VERSION ""

NS_ :

BS_:

BU_: ESP_ABR Vector__XXX

BA_DEF_ BO_ "GenMsgCycleTime" INT 0 65535;
BA_DEF_DEF_ "GenMsgCycleTime" 0;

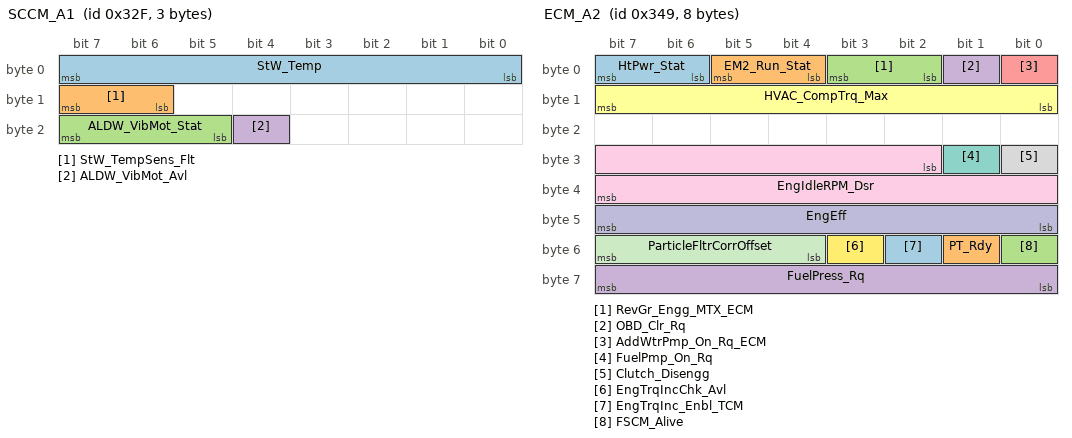
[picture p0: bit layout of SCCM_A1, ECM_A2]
BO_ 815 SCCM_A1: 3 ESP_ABR
 SG_ StW_Temp : 0|8@1+ (0.5,-40) [-40|87.5] "degC" Vector__XXX

CM_ SG_ 815 StW_Temp "StW_Temp";
 SG_ StW_TempSens_Flt : 14|2@1+ (1,0) [0|3] "" Vector__XXX

CM_ SG_ 815 StW_TempSens_Flt "StW_TempSens_Flt [source enum/value-table reference]";
 SG_ ALDW_VibMot_Stat : 21|3@1+ (1,0) [0|7] "" Vector__XXX

CM_ SG_ 815 ALDW_VibMot_Stat "ALDW_VibMot_Stat [source enum/value-table reference]";
 SG_ ALDW_VibMot_Avl : 20|1@1+ (1,0) [0|1] "" Vector__XXX

CM_ SG_ 815 ALDW_VibMot_Avl "ALDW_VibMot_Avl [source boolean]";

BA_ "GenMsgCycleTime" BO_ 815 4;

BO_ 822 TANK_OBD: 3 ESP_ABR
 SG_ TankLvl_OBD : 0|8@1+ (0.392156869173,0) [0|100.000001639] "%" Vector__XXX

CM_ SG_ 822 TankLvl_OBD "TankLvl_OBD";
 SG_ TankLvl_Max_OBD : 8|8@1+ (1,0) [0|255] "l" Vector__XXX

CM_ SG_ 822 TankLvl_Max_OBD "TankLvl_Max_OBD";
 SG_ TankSens_Rt_Stat_IC : 20|4@1+ (1,0) [0|15] "" Vector__XXX

CM_ SG_ 822 TankSens_Rt_Stat_IC "TankSens_Rt_Stat_IC [source enum/value-table reference]";
 SG_ TankSens_Lt_Stat_IC : 16|4@1+ (1,0) [0|15] "" Vector__XXX

CM_ SG_ 822 TankSens_Lt_Stat_IC "TankSens_Lt_Stat_IC [source enum/value-table reference]";

BA_ "GenMsgCycleTime" BO_ 822 4;

BO_ 828 ECM_DISP_RQ2: 8 ESP_ABR
 SG_ EngIconDisp_Rq : 6|2@1+ (1,0) [0|3] "" Vector__XXX

CM_ SG_ 828 EngIconDisp_Rq "EngIconDisp_Rq [source enum/value-table reference]";
 SG_ EM1_IconDisp_Rq : 4|2@1+ (1,0) [0|3] "" Vector__XXX

CM_ SG_ 828 EM1_IconDisp_Rq "EM1_IconDisp_Rq [source enum/value-table reference]";
 SG_ ArrEM1_EngDisp_Rq : 2|2@1+ (1,0) [0|3] "" Vector__XXX

CM_ SG_ 828 ArrEM1_EngDisp_Rq "ArrEM1_EngDisp_Rq [source enum/value-table reference]";
 SG_ ArrEM1_BatDisp_Rq : 0|2@1+ (1,0) [0|3] "" Vector__XXX

CM_ SG_ 828 ArrEM1_BatDisp_Rq "ArrEM1_BatDisp_Rq [source enum/value-table reference]";
 SG_ ArrEM1_WhlDisp_Rq : 14|2@1+ (1,0) [0|3] "" Vector__XXX

CM_ SG_ 828 ArrEM1_WhlDisp_Rq "ArrEM1_WhlDisp_Rq [source enum/value-table reference]";
 SG_ ArrBatDisp_Rq : 12|2@1+ (1,0) [0|3] "" Vector__XXX

CM_ SG_ 828 ArrBatDisp_Rq "ArrBatDisp_Rq [source enum/value-table reference]";
 SG_ PT_Rdy_IndLmp_Rq : 10|2@1+ (1,0) [0|3] "" Vector__XXX

CM_ SG_ 828 PT_Rdy_IndLmp_Rq "PT_Rdy_IndLmp_Rq [source enum/value-table reference]";
 SG_ PNHV_SupBat_SOC_Disp_Rq : 16|8@1+ (0.5,0) [0|127.5] "%" Vector__XXX

CM_ SG_ 828 PNHV_SupBat_SOC_Disp_Rq "PNHV_SupBat_SOC_Disp_Rq";
 SG_ Hyb_Msg_Disp_Rq : 28|4@1+ (1,0) [0|15] "" Vector__XXX

CM_ SG_ 828 Hyb_Msg_Disp_Rq "Hyb_Msg_Disp_Rq [source enum/value-table reference]";
 SG_ Hyb_WarnDisp_Rq : 24|4@1+ (1,0) [0|15] "" Vector__XXX

CM_ SG_ 828 Hyb_WarnDisp_Rq "Hyb_WarnDisp_Rq [source enum/value-table reference]";
 SG_ MC_ECM_DISP_RQ2 : 36|4@1+ (1,0) [0|15] "" Vector__XXX

CM_ SG_ 828 MC_ECM_DISP_RQ2 "MC_ECM_DISP_RQ2";
 SG_ Prty_PNHV_SupBat_VoltMax_Disp_Rq : 35|1@1+ (1,0) [0|1] "" Vector__XXX

CM_ SG_ 828 Prty_PNHV_SupBat_VoltMax_Disp_Rq "Prty_PNHV_SupBat_VoltMax_Disp_Rq [source boolean]";
 SG_ Prty_PNHV_VoltDn_Disp_Rq : 34|1@1+ (1,0) [0|1] "" Vector__XXX

CM_ SG_ 828 Prty_PNHV_VoltDn_Disp_Rq "Prty_PNHV_VoltDn_Disp_Rq [source boolean]";
 SG_ PNHV_VoltDn_Disp_Rq : 33|1@1+ (1,0) [0|1] "" Vector__XXX

CM_ SG_ 828 PNHV_VoltDn_Disp_Rq "PNHV_VoltDn_Disp_Rq [source boolean]";
 SG_ PT_Rdy_IndLmp_On_Rq : 32|1@1+ (1,0) [0|1] "" Vector__XXX

CM_ SG_ 828 PT_Rdy_IndLmp_On_Rq "PT_Rdy_IndLmp_On_Rq [source boolean]";
 SG_ PNHV_SupBat_VoltMax_Disp_Rq : 40|8@1+ (2,0) [0|510] "V" Vector__XXX

CM_ SG_ 828 PNHV_SupBat_VoltMax_Disp_Rq "PNHV_SupBat_VoltMax_Disp_Rq";
 SG_ PNHV_SupBat_Curr_Disp_Rq : 48|8@1+ (5,-640) [-640|635] "A" Vector__XXX

CM_ SG_ 828 PNHV_SupBat_Curr_Disp_Rq "PNHV_SupBat_Curr_Disp_Rq";
 SG_ EngOilPress_Disp_Rq : 56|8@1+ (0.10000000149,0) [0|25.50000038] "bar" Vector__XXX

CM_ SG_ 828 EngOilPress_Disp_Rq "EngOilPress_Disp_Rq";

BA_ "GenMsgCycleTime" BO_ 828 18;

BO_ 829 ECM_DISP_RQ: 4 ESP_ABR
 SG_ WtrFuelIndLmp_On_Rq : 7|1@1+ (1,0) [0|1] "" Vector__XXX

CM_ SG_ 829 WtrFuelIndLmp_On_Rq "WtrFuelIndLmp_On_Rq [source boolean]";
 SG_ FuelFltrIndLmp_On_Rq : 6|1@1+ (1,0) [0|1] "" Vector__XXX

CM_ SG_ 829 FuelFltrIndLmp_On_Rq "FuelFltrIndLmp_On_Rq [source boolean]";
 SG_ TankCapIndLmp_On_Rq : 5|1@1+ (1,0) [0|1] "" Vector__XXX

CM_ SG_ 829 TankCapIndLmp_On_Rq "TankCapIndLmp_On_Rq [source boolean]";
 SG_ MIL_On_Rq : 4|1@1+ (1,0) [0|1] "" Vector__XXX

CM_ SG_ 829 MIL_On_Rq "MIL_On_Rq [source boolean]";
 SG_ EngOilIndLmp_On_Rq : 3|1@1+ (1,0) [0|1] "" Vector__XXX

CM_ SG_ 829 EngOilIndLmp_On_Rq "EngOilIndLmp_On_Rq [source boolean]";
 SG_ PreHtIndLmp_On_Rq : 2|1@1+ (1,0) [0|1] "" Vector__XXX

CM_ SG_ 829 PreHtIndLmp_On_Rq "PreHtIndLmp_On_Rq [source boolean]";
 SG_ AirStrIndLmp_On_Rq : 1|1@1+ (1,0) [0|1] "" Vector__XXX

CM_ SG_ 829 AirStrIndLmp_On_Rq "AirStrIndLmp_On_Rq [source boolean]";
 SG_ FanMtrIndLmp_On_Rq : 0|1@1+ (1,0) [0|1] "" Vector__XXX

CM_ SG_ 829 FanMtrIndLmp_On_Rq "FanMtrIndLmp_On_Rq [source boolean]";
 SG_ EngOilTemp_Above_Max : 15|1@1+ (1,0) [0|1] "" Vector__XXX

CM_ SG_ 829 EngOilTemp_Above_Max "EngOilTemp_Above_Max [source boolean]";
 SG_ SSA_ECO_Sw_LED_On_Rq : 13|2@1+ (1,0) [0|3] "" Vector__XXX

CM_ SG_ 829 SSA_ECO_Sw_LED_On_Rq "SSA_ECO_Sw_LED_On_Rq [source enum/value-table reference]";
 SG_ SSA_ECO_Md_DispCol_Rq : 12|1@1+ (1,0) [0|1] "" Vector__XXX

CM_ SG_ 829 SSA_ECO_Md_DispCol_Rq "SSA_ECO_Md_DispCol_Rq [source boolean]";
 SG_ ParticleFltrWarn : 10|2@1+ (1,0) [0|3] "" Vector__XXX

CM_ SG_ 829 ParticleFltrWarn "ParticleFltrWarn [source enum/value-table reference]";
 SG_ OvrRPM_Actv : 9|1@1+ (1,0) [0|1] "" Vector__XXX

CM_ SG_ 829 OvrRPM_Actv "OvrRPM_Actv [source boolean]";
 SG_ DAC_StErr : 8|1@1+ (1,0) [0|1] "" Vector__XXX

CM_ SG_ 829 DAC_StErr "DAC_StErr [source boolean]";
 SG_ SSA_Msg_Disp_Rq : 20|4@1+ (1,0) [0|15] "" Vector__XXX

CM_ SG_ 829 SSA_Msg_Disp_Rq "SSA_Msg_Disp_Rq [source enum/value-table reference]";
 SG_ SSA_WarnDisp_Rq : 16|4@1+ (1,0) [0|15] "" Vector__XXX

CM_ SG_ 829 SSA_WarnDisp_Rq "SSA_WarnDisp_Rq [source enum/value-table reference]";
 SG_ Gr_Target_Disp_Rq_ECM : 28|4@1+ (1,0) [0|15] "" Vector__XXX

CM_ SG_ 829 Gr_Target_Disp_Rq_ECM "Gr_Target_Disp_Rq_ECM [source enum/value-table reference]";
 SG_ TxShiftRcmmnd_Disp_Rq_ECM : 26|2@1+ (1,0) [0|3] "" Vector__XXX

CM_ SG_ 829 TxShiftRcmmnd_Disp_Rq_ECM "TxShiftRcmmnd_Disp_Rq_ECM [source enum/value-table reference]";
 SG_ SSA_ECO_Md_Actv_Disp_Rq : 25|1@1+ (1,0) [0|1] "" Vector__XXX

CM_ SG_ 829 SSA_ECO_Md_Actv_Disp_Rq "SSA_ECO_Md_Actv_Disp_Rq [source boolean]";
 SG_ IndLmpChk_Off_Rq : 24|1@1+ (1,0) [0|1] "" Vector__XXX

CM_ SG_ 829 IndLmpChk_Off_Rq "IndLmpChk_Off_Rq [source boolean]";

BA_ "GenMsgCycleTime" BO_ 829 20;

BO_ 832 EPS_STAT: 1 ESP_ABR
 SG_ EPS_WarnDisp_Rq : 5|3@1+ (1,0) [0|7] "" Vector__XXX

CM_ SG_ 832 EPS_WarnDisp_Rq "EPS_WarnDisp_Rq [source enum/value-table reference]";

BA_ "GenMsgCycleTime" BO_ 832 1;

BO_ 841 ECM_A2: 8 ESP_ABR
 SG_ HtPwr_Stat : 6|2@1+ (1,0) [0|3] "" Vector__XXX

CM_ SG_ 841 HtPwr_Stat "HtPwr_Stat [source enum/value-table reference]";
 SG_ EM2_Run_Stat : 4|2@1+ (1,0) [0|3] "" Vector__XXX

CM_ SG_ 841 EM2_Run_Stat "EM2_Run_Stat [source enum/value-table reference]";
 SG_ RevGr_Engg_MTX_ECM : 2|2@1+ (1,0) [0|3] "" Vector__XXX

CM_ SG_ 841 RevGr_Engg_MTX_ECM "RevGr_Engg_MTX_ECM [source enum/value-table reference]";
 SG_ OBD_Clr_Rq : 1|1@1+ (1,0) [0|1] "" Vector__XXX

CM_ SG_ 841 OBD_Clr_Rq "OBD_Clr_Rq [source boolean]";
 SG_ AddWtrPmp_On_Rq_ECM : 0|1@1+ (1,0) [0|1] "" Vector__XXX

CM_ SG_ 841 AddWtrPmp_On_Rq_ECM "AddWtrPmp_On_Rq_ECM [source boolean]";
 SG_ HVAC_CompTrq_Max : 8|8@1+ (0.25,0) [0|63.75] "Nm" Vector__XXX

CM_ SG_ 841 HVAC_CompTrq_Max "HVAC_CompTrq_Max";
 SG_ FuelPmp_On_Rq : 25|1@1+ (1,0) [0|1] "" Vector__XXX

CM_ SG_ 841 FuelPmp_On_Rq "FuelPmp_On_Rq [source boolean]";
 SG_ Clutch_Disengg : 24|1@1+ (1,0) [0|1] "" Vector__XXX

CM_ SG_ 841 Clutch_Disengg "Clutch_Disengg [source boolean]";
 SG_ EngIdleRPM_Dsr : 26|14@1+ (1,0) [0|16383] "rpm" Vector__XXX

CM_ SG_ 841 EngIdleRPM_Dsr "EngIdleRPM_Dsr";
 SG_ EngEff : 40|8@1+ (0.5,0) [0|127.5] "%" Vector__XXX

CM_ SG_ 841 EngEff "EngEff";
 SG_ ParticleFltrCorrOffset : 52|4@1+ (0.0299999993294,0) [0|0.449999989942] "" Vector__XXX

CM_ SG_ 841 ParticleFltrCorrOffset "ParticleFltrCorrOffset";
 SG_ EngTrqIncChk_Avl : 51|1@1+ (1,0) [0|1] "" Vector__XXX

CM_ SG_ 841 EngTrqIncChk_Avl "EngTrqIncChk_Avl [source boolean]";
 SG_ EngTrqInc_Enbl_TCM : 50|1@1+ (1,0) [0|1] "" Vector__XXX

CM_ SG_ 841 EngTrqInc_Enbl_TCM "EngTrqInc_Enbl_TCM [source boolean]";
 SG_ PT_Rdy : 49|1@1+ (1,0) [0|1] "" Vector__XXX

CM_ SG_ 841 PT_Rdy "PT_Rdy [source boolean]";
 SG_ FSCM_Alive : 48|1@1+ (1,0) [0|1] "" Vector__XXX

CM_ SG_ 841 FSCM_Alive "FSCM_Alive [source boolean]";
 SG_ FuelPress_Rq : 56|8@1+ (0.0500000007451,0) [0|12.75000019] "bar" Vector__XXX

CM_ SG_ 841 FuelPress_Rq "FuelPress_Rq";

BA_ "GenMsgCycleTime" BO_ 841 16;

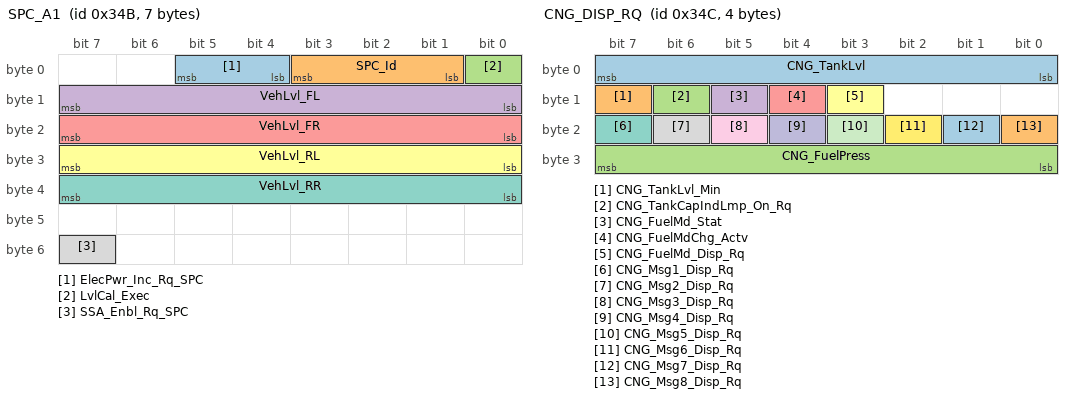
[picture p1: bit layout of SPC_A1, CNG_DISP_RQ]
BO_ 843 SPC_A1: 7 ESP_ABR
 SG_ ElecPwr_Inc_Rq_SPC : 4|2@1+ (1,0) [0|3] "" Vector__XXX

CM_ SG_ 843 ElecPwr_Inc_Rq_SPC "ElecPwr_Inc_Rq_SPC [source enum/value-table reference]";
 SG_ SPC_Id : 1|3@1+ (1,0) [0|7] "" Vector__XXX

CM_ SG_ 843 SPC_Id "SPC_Id [source enum/value-table reference]";
 SG_ LvlCal_Exec : 0|1@1+ (1,0) [0|1] "" Vector__XXX

CM_ SG_ 843 LvlCal_Exec "LvlCal_Exec [source boolean]";
 SG_ VehLvl_FL : 8|8@1+ (1,-127) [-127|128] "mm" Vector__XXX

CM_ SG_ 843 VehLvl_FL "VehLvl_FL";
 SG_ VehLvl_FR : 16|8@1+ (1,-127) [-127|128] "mm" Vector__XXX

CM_ SG_ 843 VehLvl_FR "VehLvl_FR";
 SG_ VehLvl_RL : 24|8@1+ (1,-127) [-127|128] "mm" Vector__XXX

CM_ SG_ 843 VehLvl_RL "VehLvl_RL";
 SG_ VehLvl_RR : 32|8@1+ (1,-127) [-127|128] "mm" Vector__XXX

CM_ SG_ 843 VehLvl_RR "VehLvl_RR";
 SG_ SSA_Enbl_Rq_SPC : 55|1@1+ (1,0) [0|1] "" Vector__XXX

CM_ SG_ 843 SSA_Enbl_Rq_SPC "SSA_Enbl_Rq_SPC [source boolean]";

BA_ "GenMsgCycleTime" BO_ 843 8;

BO_ 844 CNG_DISP_RQ: 4 ESP_ABR
 SG_ CNG_TankLvl : 0|8@1+ (1,0) [0|255] "%" Vector__XXX

CM_ SG_ 844 CNG_TankLvl "CNG_TankLvl";
 SG_ CNG_TankLvl_Min : 15|1@1+ (1,0) [0|1] "" Vector__XXX

CM_ SG_ 844 CNG_TankLvl_Min "CNG_TankLvl_Min [source boolean]";
 SG_ CNG_TankCapIndLmp_On_Rq : 14|1@1+ (1,0) [0|1] "" Vector__XXX

CM_ SG_ 844 CNG_TankCapIndLmp_On_Rq "CNG_TankCapIndLmp_On_Rq [source boolean]";
 SG_ CNG_FuelMd_Stat : 13|1@1+ (1,0) [0|1] "" Vector__XXX

CM_ SG_ 844 CNG_FuelMd_Stat "CNG_FuelMd_Stat [source boolean]";
 SG_ CNG_FuelMdChg_Actv : 12|1@1+ (1,0) [0|1] "" Vector__XXX

CM_ SG_ 844 CNG_FuelMdChg_Actv "CNG_FuelMdChg_Actv [source boolean]";
 SG_ CNG_FuelMd_Disp_Rq : 11|1@1+ (1,0) [0|1] "" Vector__XXX

CM_ SG_ 844 CNG_FuelMd_Disp_Rq "CNG_FuelMd_Disp_Rq [source boolean]";
 SG_ CNG_Msg1_Disp_Rq : 23|1@1+ (1,0) [0|1] "" Vector__XXX

CM_ SG_ 844 CNG_Msg1_Disp_Rq "CNG_Msg1_Disp_Rq [source boolean]";
 SG_ CNG_Msg2_Disp_Rq : 22|1@1+ (1,0) [0|1] "" Vector__XXX

CM_ SG_ 844 CNG_Msg2_Disp_Rq "CNG_Msg2_Disp_Rq [source boolean]";
 SG_ CNG_Msg3_Disp_Rq : 21|1@1+ (1,0) [0|1] "" Vector__XXX

CM_ SG_ 844 CNG_Msg3_Disp_Rq "CNG_Msg3_Disp_Rq [source boolean]";
 SG_ CNG_Msg4_Disp_Rq : 20|1@1+ (1,0) [0|1] "" Vector__XXX

CM_ SG_ 844 CNG_Msg4_Disp_Rq "CNG_Msg4_Disp_Rq [source boolean]";
 SG_ CNG_Msg5_Disp_Rq : 19|1@1+ (1,0) [0|1] "" Vector__XXX

CM_ SG_ 844 CNG_Msg5_Disp_Rq "CNG_Msg5_Disp_Rq [source boolean]";
 SG_ CNG_Msg6_Disp_Rq : 18|1@1+ (1,0) [0|1] "" Vector__XXX

CM_ SG_ 844 CNG_Msg6_Disp_Rq "CNG_Msg6_Disp_Rq [source boolean]";
 SG_ CNG_Msg7_Disp_Rq : 17|1@1+ (1,0) [0|1] "" Vector__XXX

CM_ SG_ 844 CNG_Msg7_Disp_Rq "CNG_Msg7_Disp_Rq [source boolean]";
 SG_ CNG_Msg8_Disp_Rq : 16|1@1+ (1,0) [0|1] "" Vector__XXX

CM_ SG_ 844 CNG_Msg8_Disp_Rq "CNG_Msg8_Disp_Rq [source boolean]";
 SG_ CNG_FuelPress : 24|8@1+ (1,0) [0|255] "bar" Vector__XXX

CM_ SG_ 844 CNG_FuelPress "CNG_FuelPress";

BA_ "GenMsgCycleTime" BO_ 844 15;

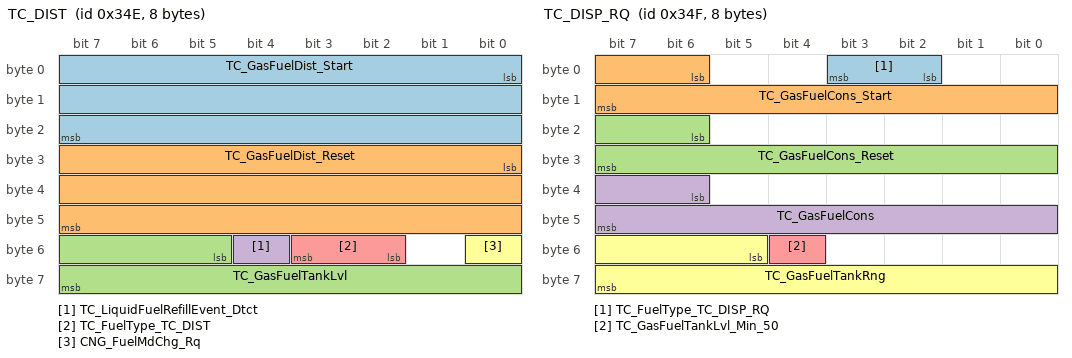
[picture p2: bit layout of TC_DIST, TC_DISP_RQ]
BO_ 846 TC_DIST: 8 ESP_ABR
 SG_ TC_GasFuelDist_Start : 0|24@1+ (0.10000000149,0) [0|1677721.525] "km" Vector__XXX

CM_ SG_ 846 TC_GasFuelDist_Start "TC_GasFuelDist_Start";
 SG_ TC_GasFuelDist_Reset : 24|24@1+ (0.10000000149,0) [0|1677721.525] "km" Vector__XXX

CM_ SG_ 846 TC_GasFuelDist_Reset "TC_GasFuelDist_Reset";
 SG_ TC_GasFuelTankLvl : 53|11@1+ (0.10000000149,0) [0|204.70000305] "kg" Vector__XXX

CM_ SG_ 846 TC_GasFuelTankLvl "TC_GasFuelTankLvl";
 SG_ TC_LiquidFuelRefillEvent_Dtct : 52|1@1+ (1,0) [0|1] "" Vector__XXX

CM_ SG_ 846 TC_LiquidFuelRefillEvent_Dtct "TC_LiquidFuelRefillEvent_Dtct [source boolean]";
 SG_ TC_FuelType_TC_DIST : 50|2@1+ (1,0) [0|3] "" Vector__XXX

CM_ SG_ 846 TC_FuelType_TC_DIST "TC_FuelType_TC_DIST [source enum/value-table reference]";
 SG_ CNG_FuelMdChg_Rq : 48|1@1+ (1,0) [0|1] "" Vector__XXX

CM_ SG_ 846 CNG_FuelMdChg_Rq "CNG_FuelMdChg_Rq [source boolean]";

BA_ "GenMsgCycleTime" BO_ 846 6;

BO_ 847 TC_DISP_RQ: 8 ESP_ABR
 SG_ TC_FuelType_TC_DISP_RQ : 2|2@1+ (1,0) [0|3] "" Vector__XXX

CM_ SG_ 847 TC_FuelType_TC_DISP_RQ "TC_FuelType_TC_DISP_RQ [source enum/value-table reference]";
 SG_ TC_GasFuelCons_Start : 6|10@1+ (0.10000000149,0) [0|102.300001524] "kg/100km" Vector__XXX

CM_ SG_ 847 TC_GasFuelCons_Start "TC_GasFuelCons_Start";
 SG_ TC_GasFuelCons_Reset : 22|10@1+ (0.10000000149,0) [0|102.300001524] "kg/100km" Vector__XXX

CM_ SG_ 847 TC_GasFuelCons_Reset "TC_GasFuelCons_Reset";
 SG_ TC_GasFuelCons : 38|10@1+ (0.10000000149,0) [0|102.300001524] "kg/100km" Vector__XXX

CM_ SG_ 847 TC_GasFuelCons "TC_GasFuelCons";
 SG_ TC_GasFuelTankLvl_Min_50 : 52|1@1+ (1,0) [0|1] "" Vector__XXX

CM_ SG_ 847 TC_GasFuelTankLvl_Min_50 "TC_GasFuelTankLvl_Min_50 [source boolean]";
 SG_ TC_GasFuelTankRng : 53|11@1+ (1,0) [0|2047] "km" Vector__XXX

CM_ SG_ 847 TC_GasFuelTankRng "TC_GasFuelTankRng";

BA_ "GenMsgCycleTime" BO_ 847 6;

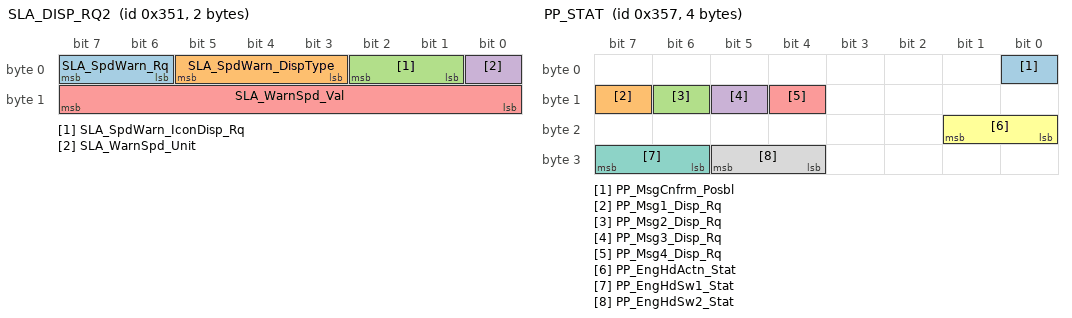
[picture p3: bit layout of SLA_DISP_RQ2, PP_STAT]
BO_ 849 SLA_DISP_RQ2: 2 ESP_ABR
 SG_ SLA_SpdWarn_Rq : 6|2@1+ (1,0) [0|3] "" Vector__XXX

CM_ SG_ 849 SLA_SpdWarn_Rq "SLA_SpdWarn_Rq [source enum/value-table reference]";
 SG_ SLA_SpdWarn_DispType : 3|3@1+ (1,0) [0|7] "" Vector__XXX

CM_ SG_ 849 SLA_SpdWarn_DispType "SLA_SpdWarn_DispType [source enum/value-table reference]";
 SG_ SLA_SpdWarn_IconDisp_Rq : 1|2@1+ (1,0) [0|3] "" Vector__XXX

CM_ SG_ 849 SLA_SpdWarn_IconDisp_Rq "SLA_SpdWarn_IconDisp_Rq [source enum/value-table reference]";
 SG_ SLA_WarnSpd_Unit : 0|1@1+ (1,0) [0|1] "" Vector__XXX

CM_ SG_ 849 SLA_WarnSpd_Unit "SLA_WarnSpd_Unit [source boolean]";
 SG_ SLA_WarnSpd_Val : 8|8@1+ (1,0) [0|255] "" Vector__XXX

CM_ SG_ 849 SLA_WarnSpd_Val "SLA_WarnSpd_Val";

BA_ "GenMsgCycleTime" BO_ 849 5;

BO_ 851 IC_A10: 1 ESP_ABR
 SG_ SLA_SpdOffset_Rq_D_Val : 1|7@1+ (1,-64) [-64|63] "" Vector__XXX

CM_ SG_ 851 SLA_SpdOffset_Rq_D_Val "SLA_SpdOffset_Rq_D_Val";
 SG_ SLA_SpdOffset_Rq_D_Unit : 0|1@1+ (1,0) [0|1] "" Vector__XXX

CM_ SG_ 851 SLA_SpdOffset_Rq_D_Unit "SLA_SpdOffset_Rq_D_Unit [source boolean]";

BA_ "GenMsgCycleTime" BO_ 851 2;

BO_ 855 PP_STAT: 4 ESP_ABR
 SG_ PP_MsgCnfrm_Posbl : 0|1@1+ (1,0) [0|1] "" Vector__XXX

CM_ SG_ 855 PP_MsgCnfrm_Posbl "PP_MsgCnfrm_Posbl [source boolean]";
 SG_ PP_Msg1_Disp_Rq : 15|1@1+ (1,0) [0|1] "" Vector__XXX

CM_ SG_ 855 PP_Msg1_Disp_Rq "PP_Msg1_Disp_Rq [source boolean]";
 SG_ PP_Msg2_Disp_Rq : 14|1@1+ (1,0) [0|1] "" Vector__XXX

CM_ SG_ 855 PP_Msg2_Disp_Rq "PP_Msg2_Disp_Rq [source boolean]";
 SG_ PP_Msg3_Disp_Rq : 13|1@1+ (1,0) [0|1] "" Vector__XXX

CM_ SG_ 855 PP_Msg3_Disp_Rq "PP_Msg3_Disp_Rq [source boolean]";
 SG_ PP_Msg4_Disp_Rq : 12|1@1+ (1,0) [0|1] "" Vector__XXX

CM_ SG_ 855 PP_Msg4_Disp_Rq "PP_Msg4_Disp_Rq [source boolean]";
 SG_ PP_EngHdActn_Stat : 16|2@1+ (1,0) [0|3] "" Vector__XXX

CM_ SG_ 855 PP_EngHdActn_Stat "PP_EngHdActn_Stat [source enum/value-table reference]";
 SG_ PP_EngHdSw1_Stat : 30|2@1+ (1,0) [0|3] "" Vector__XXX

CM_ SG_ 855 PP_EngHdSw1_Stat "PP_EngHdSw1_Stat [source enum/value-table reference]";
 SG_ PP_EngHdSw2_Stat : 28|2@1+ (1,0) [0|3] "" Vector__XXX

CM_ SG_ 855 PP_EngHdSw2_Stat "PP_EngHdSw2_Stat [source enum/value-table reference]";

BA_ "GenMsgCycleTime" BO_ 855 8;

BO_ 867 TCASE_DIFFLK_DISP_RQ: 6 ESP_ABR
 SG_ TCASE_GrLo_IndLmp_On_Rq : 10|2@1+ (1,0) [0|3] "" Vector__XXX

CM_ SG_ 867 TCASE_GrLo_IndLmp_On_Rq "TCASE_GrLo_IndLmp_On_Rq [source enum/value-table reference]";
 SG_ TCASE_Msg1_Disp_Rq : 23|1@1+ (1,0) [0|1] "" Vector__XXX

CM_ SG_ 867 TCASE_Msg1_Disp_Rq "TCASE_Msg1_Disp_Rq [source boolean]";
 SG_ TCASE_Msg2_Disp_Rq : 22|1@1+ (1,0) [0|1] "" Vector__XXX

CM_ SG_ 867 TCASE_Msg2_Disp_Rq "TCASE_Msg2_Disp_Rq [source boolean]";
 SG_ TCASE_Msg3_Disp_Rq : 21|1@1+ (1,0) [0|1] "" Vector__XXX

CM_ SG_ 867 TCASE_Msg3_Disp_Rq "TCASE_Msg3_Disp_Rq [source boolean]";
 SG_ TCASE_Msg4_Disp_Rq : 20|1@1+ (1,0) [0|1] "" Vector__XXX

CM_ SG_ 867 TCASE_Msg4_Disp_Rq "TCASE_Msg4_Disp_Rq [source boolean]";
 SG_ TCASE_Msg5_Disp_Rq : 19|1@1+ (1,0) [0|1] "" Vector__XXX

CM_ SG_ 867 TCASE_Msg5_Disp_Rq "TCASE_Msg5_Disp_Rq [source boolean]";
 SG_ TCASE_Msg6_Disp_Rq : 18|1@1+ (1,0) [0|1] "" Vector__XXX

CM_ SG_ 867 TCASE_Msg6_Disp_Rq "TCASE_Msg6_Disp_Rq [source boolean]";
 SG_ TCASE_Msg7_Disp_Rq : 17|1@1+ (1,0) [0|1] "" Vector__XXX

CM_ SG_ 867 TCASE_Msg7_Disp_Rq "TCASE_Msg7_Disp_Rq [source boolean]";
 SG_ TCASE_Msg8_Disp_Rq : 16|1@1+ (1,0) [0|1] "" Vector__XXX

CM_ SG_ 867 TCASE_Msg8_Disp_Rq "TCASE_Msg8_Disp_Rq [source boolean]";
 SG_ DiffLk_Msg9_Disp_Rq : 27|1@1+ (1,0) [0|1] "" Vector__XXX

CM_ SG_ 867 DiffLk_Msg9_Disp_Rq "DiffLk_Msg9_Disp_Rq [source boolean]";
 SG_ HPP_Disp_TrgRq_TCASE : 24|2@1+ (1,0) [0|3] "" Vector__XXX

CM_ SG_ 867 HPP_Disp_TrgRq_TCASE "HPP_Disp_TrgRq_TCASE [source enum/value-table reference]";
 SG_ DiffLk_Msg1_Disp_Rq : 39|1@1+ (1,0) [0|1] "" Vector__XXX

CM_ SG_ 867 DiffLk_Msg1_Disp_Rq "DiffLk_Msg1_Disp_Rq [source boolean]";
 SG_ DiffLk_Msg2_Disp_Rq : 38|1@1+ (1,0) [0|1] "" Vector__XXX

CM_ SG_ 867 DiffLk_Msg2_Disp_Rq "DiffLk_Msg2_Disp_Rq [source boolean]";
 SG_ DiffLk_Msg3_Disp_Rq : 37|1@1+ (1,0) [0|1] "" Vector__XXX

CM_ SG_ 867 DiffLk_Msg3_Disp_Rq "DiffLk_Msg3_Disp_Rq [source boolean]";
 SG_ DiffLk_Msg4_Disp_Rq : 36|1@1+ (1,0) [0|1] "" Vector__XXX

CM_ SG_ 867 DiffLk_Msg4_Disp_Rq "DiffLk_Msg4_Disp_Rq [source boolean]";
 SG_ DiffLk_Msg5_Disp_Rq : 35|1@1+ (1,0) [0|1] "" Vector__XXX

CM_ SG_ 867 DiffLk_Msg5_Disp_Rq "DiffLk_Msg5_Disp_Rq [source boolean]";
 SG_ DiffLk_Msg6_Disp_Rq : 34|1@1+ (1,0) [0|1] "" Vector__XXX

CM_ SG_ 867 DiffLk_Msg6_Disp_Rq "DiffLk_Msg6_Disp_Rq [source boolean]";
 SG_ DiffLk_Msg7_Disp_Rq : 33|1@1+ (1,0) [0|1] "" Vector__XXX

CM_ SG_ 867 DiffLk_Msg7_Disp_Rq "DiffLk_Msg7_Disp_Rq [source boolean]";
 SG_ DiffLk_Msg8_Disp_Rq : 32|1@1+ (1,0) [0|1] "" Vector__XXX

CM_ SG_ 867 DiffLk_Msg8_Disp_Rq "DiffLk_Msg8_Disp_Rq [source boolean]";
 SG_ TCASE_Msg9_Disp_Rq : 47|1@1+ (1,0) [0|1] "" Vector__XXX

CM_ SG_ 867 TCASE_Msg9_Disp_Rq "TCASE_Msg9_Disp_Rq [source boolean]";
 SG_ TCASE_Msg10_Disp_Rq : 46|1@1+ (1,0) [0|1] "" Vector__XXX

CM_ SG_ 867 TCASE_Msg10_Disp_Rq "TCASE_Msg10_Disp_Rq [source boolean]";
 SG_ TCASE_Msg11_Disp_Rq : 45|1@1+ (1,0) [0|1] "" Vector__XXX

CM_ SG_ 867 TCASE_Msg11_Disp_Rq "TCASE_Msg11_Disp_Rq [source boolean]";

BA_ "GenMsgCycleTime" BO_ 867 22;

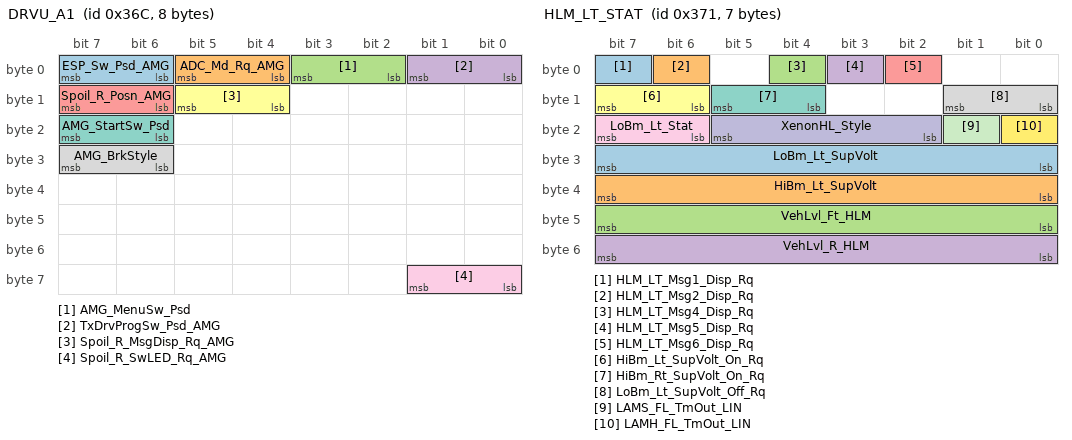
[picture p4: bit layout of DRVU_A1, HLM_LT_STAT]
BO_ 876 DRVU_A1: 8 ESP_ABR
 SG_ ESP_Sw_Psd_AMG : 6|2@1+ (1,0) [0|3] "" Vector__XXX

CM_ SG_ 876 ESP_Sw_Psd_AMG "ESP_Sw_Psd_AMG [source enum/value-table reference]";
 SG_ ADC_Md_Rq_AMG : 4|2@1+ (1,0) [0|3] "" Vector__XXX

CM_ SG_ 876 ADC_Md_Rq_AMG "ADC_Md_Rq_AMG [source enum/value-table reference]";
 SG_ AMG_MenuSw_Psd : 2|2@1+ (1,0) [0|3] "" Vector__XXX

CM_ SG_ 876 AMG_MenuSw_Psd "AMG_MenuSw_Psd [source enum/value-table reference]";
 SG_ TxDrvProgSw_Psd_AMG : 0|2@1+ (1,0) [0|3] "" Vector__XXX

CM_ SG_ 876 TxDrvProgSw_Psd_AMG "TxDrvProgSw_Psd_AMG [source enum/value-table reference]";
 SG_ Spoil_R_Posn_AMG : 14|2@1+ (1,0) [0|3] "" Vector__XXX

CM_ SG_ 876 Spoil_R_Posn_AMG "Spoil_R_Posn_AMG [source enum/value-table reference]";
 SG_ Spoil_R_MsgDisp_Rq_AMG : 12|2@1+ (1,0) [0|3] "" Vector__XXX

CM_ SG_ 876 Spoil_R_MsgDisp_Rq_AMG "Spoil_R_MsgDisp_Rq_AMG [source enum/value-table reference]";
 SG_ AMG_StartSw_Psd : 22|2@1+ (1,0) [0|3] "" Vector__XXX

CM_ SG_ 876 AMG_StartSw_Psd "AMG_StartSw_Psd [source enum/value-table reference]";
 SG_ AMG_BrkStyle : 30|2@1+ (1,0) [0|3] "" Vector__XXX

CM_ SG_ 876 AMG_BrkStyle "AMG_BrkStyle [source enum/value-table reference]";
 SG_ Spoil_R_SwLED_Rq_AMG : 56|2@1+ (1,0) [0|3] "" Vector__XXX

CM_ SG_ 876 Spoil_R_SwLED_Rq_AMG "Spoil_R_SwLED_Rq_AMG [source enum/value-table reference]";

BA_ "GenMsgCycleTime" BO_ 876 9;

BO_ 881 HLM_LT_STAT: 7 ESP_ABR
 SG_ HLM_LT_Msg1_Disp_Rq : 7|1@1+ (1,0) [0|1] "" Vector__XXX

CM_ SG_ 881 HLM_LT_Msg1_Disp_Rq "HLM_LT_Msg1_Disp_Rq [source boolean]";
 SG_ HLM_LT_Msg2_Disp_Rq : 6|1@1+ (1,0) [0|1] "" Vector__XXX

CM_ SG_ 881 HLM_LT_Msg2_Disp_Rq "HLM_LT_Msg2_Disp_Rq [source boolean]";
 SG_ HLM_LT_Msg4_Disp_Rq : 4|1@1+ (1,0) [0|1] "" Vector__XXX

CM_ SG_ 881 HLM_LT_Msg4_Disp_Rq "HLM_LT_Msg4_Disp_Rq [source boolean]";
 SG_ HLM_LT_Msg5_Disp_Rq : 3|1@1+ (1,0) [0|1] "" Vector__XXX

CM_ SG_ 881 HLM_LT_Msg5_Disp_Rq "HLM_LT_Msg5_Disp_Rq [source boolean]";
 SG_ HLM_LT_Msg6_Disp_Rq : 2|1@1+ (1,0) [0|1] "" Vector__XXX

CM_ SG_ 881 HLM_LT_Msg6_Disp_Rq "HLM_LT_Msg6_Disp_Rq [source boolean]";
 SG_ HiBm_Lt_SupVolt_On_Rq : 14|2@1+ (1,0) [0|3] "" Vector__XXX

CM_ SG_ 881 HiBm_Lt_SupVolt_On_Rq "HiBm_Lt_SupVolt_On_Rq [source enum/value-table reference]";
 SG_ HiBm_Rt_SupVolt_On_Rq : 12|2@1+ (1,0) [0|3] "" Vector__XXX

CM_ SG_ 881 HiBm_Rt_SupVolt_On_Rq "HiBm_Rt_SupVolt_On_Rq [source enum/value-table reference]";
 SG_ LoBm_Lt_SupVolt_Off_Rq : 8|2@1+ (1,0) [0|3] "" Vector__XXX

CM_ SG_ 881 LoBm_Lt_SupVolt_Off_Rq "LoBm_Lt_SupVolt_Off_Rq [source enum/value-table reference]";
 SG_ LoBm_Lt_Stat : 22|2@1+ (1,0) [0|3] "" Vector__XXX

CM_ SG_ 881 LoBm_Lt_Stat "LoBm_Lt_Stat [source enum/value-table reference]";
 SG_ XenonHL_Style : 18|4@1+ (1,0) [0|15] "" Vector__XXX

CM_ SG_ 881 XenonHL_Style "XenonHL_Style [source enum/value-table reference]";
 SG_ LAMS_FL_TmOut_LIN : 17|1@1+ (1,0) [0|1] "" Vector__XXX

CM_ SG_ 881 LAMS_FL_TmOut_LIN "LAMS_FL_TmOut_LIN [source boolean]";
 SG_ LAMH_FL_TmOut_LIN : 16|1@1+ (1,0) [0|1] "" Vector__XXX

CM_ SG_ 881 LAMH_FL_TmOut_LIN "LAMH_FL_TmOut_LIN [source boolean]";
 SG_ LoBm_Lt_SupVolt : 24|8@1+ (0.10000000149,0) [0|25.50000038] "V" Vector__XXX

CM_ SG_ 881 LoBm_Lt_SupVolt "LoBm_Lt_SupVolt";
 SG_ HiBm_Lt_SupVolt : 32|8@1+ (0.10000000149,0) [0|25.50000038] "V" Vector__XXX

CM_ SG_ 881 HiBm_Lt_SupVolt "HiBm_Lt_SupVolt";
 SG_ VehLvl_Ft_HLM : 40|8@1+ (1,-127) [-127|128] "mm" Vector__XXX

CM_ SG_ 881 VehLvl_Ft_HLM "VehLvl_Ft_HLM";
 SG_ VehLvl_R_HLM : 48|8@1+ (1,-127) [-127|128] "mm" Vector__XXX

CM_ SG_ 881 VehLvl_R_HLM "VehLvl_R_HLM";

BA_ "GenMsgCycleTime" BO_ 881 16;

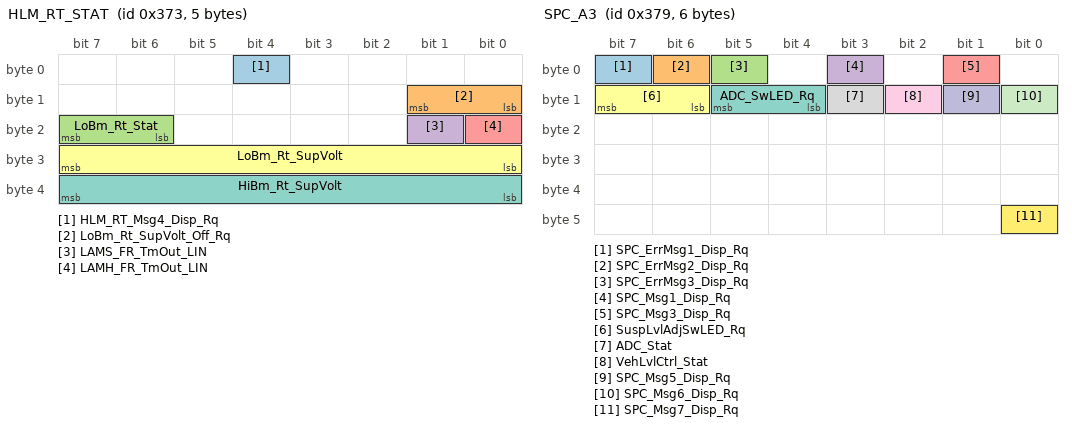
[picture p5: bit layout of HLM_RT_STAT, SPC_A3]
BO_ 883 HLM_RT_STAT: 5 ESP_ABR
 SG_ HLM_RT_Msg4_Disp_Rq : 4|1@1+ (1,0) [0|1] "" Vector__XXX

CM_ SG_ 883 HLM_RT_Msg4_Disp_Rq "HLM_RT_Msg4_Disp_Rq [source boolean]";
 SG_ LoBm_Rt_SupVolt_Off_Rq : 8|2@1+ (1,0) [0|3] "" Vector__XXX

CM_ SG_ 883 LoBm_Rt_SupVolt_Off_Rq "LoBm_Rt_SupVolt_Off_Rq [source enum/value-table reference]";
 SG_ LoBm_Rt_Stat : 22|2@1+ (1,0) [0|3] "" Vector__XXX

CM_ SG_ 883 LoBm_Rt_Stat "LoBm_Rt_Stat [source enum/value-table reference]";
 SG_ LAMS_FR_TmOut_LIN : 17|1@1+ (1,0) [0|1] "" Vector__XXX

CM_ SG_ 883 LAMS_FR_TmOut_LIN "LAMS_FR_TmOut_LIN [source boolean]";
 SG_ LAMH_FR_TmOut_LIN : 16|1@1+ (1,0) [0|1] "" Vector__XXX

CM_ SG_ 883 LAMH_FR_TmOut_LIN "LAMH_FR_TmOut_LIN [source boolean]";
 SG_ LoBm_Rt_SupVolt : 24|8@1+ (0.10000000149,0) [0|25.50000038] "V" Vector__XXX

CM_ SG_ 883 LoBm_Rt_SupVolt "LoBm_Rt_SupVolt";
 SG_ HiBm_Rt_SupVolt : 32|8@1+ (0.10000000149,0) [0|25.50000038] "V" Vector__XXX

CM_ SG_ 883 HiBm_Rt_SupVolt "HiBm_Rt_SupVolt";

BA_ "GenMsgCycleTime" BO_ 883 7;

BO_ 885 ORC_A1: 8 ESP_ABR
 SG_ SRS_SrvMsg_Disp_Rq : 6|2@1+ (1,0) [0|3] "" Vector__XXX

CM_ SG_ 885 SRS_SrvMsg_Disp_Rq "SRS_SrvMsg_Disp_Rq [source enum/value-table reference]";
 SG_ SRS_IndLmp_Rq : 4|2@1+ (1,0) [0|3] "" Vector__XXX

CM_ SG_ 885 SRS_IndLmp_Rq "SRS_IndLmp_Rq [source enum/value-table reference]";
 SG_ COD_IndLmp_Rq : 2|2@1+ (1,0) [0|3] "" Vector__XXX

CM_ SG_ 885 COD_IndLmp_Rq "COD_IndLmp_Rq [source enum/value-table reference]";
 SG_ Airbag_P_LED_On_Rq : 0|2@1+ (1,0) [0|3] "" Vector__XXX

CM_ SG_ 885 Airbag_P_LED_On_Rq "Airbag_P_LED_On_Rq [source enum/value-table reference]";
 SG_ OC_P_ORC : 13|3@1+ (1,0) [0|7] "" Vector__XXX

CM_ SG_ 885 OC_P_ORC "OC_P_ORC [source enum/value-table reference]";
 SG_ OC_P_Flt_ORC : 12|1@1+ (1,0) [0|1] "" Vector__XXX

CM_ SG_ 885 OC_P_Flt_ORC "OC_P_Flt_ORC [source boolean]";
 SG_ OC_P_Fast_ORC : 10|2@1+ (1,0) [0|3] "" Vector__XXX

CM_ SG_ 885 OC_P_Fast_ORC "OC_P_Fast_ORC [source enum/value-table reference]";
 SG_ KG_Sync : 9|1@1+ (1,0) [0|1] "" Vector__XXX

CM_ SG_ 885 KG_Sync "KG_Sync [source boolean]";
 SG_ Bckl_Sw_D_Stat : 22|2@1+ (1,0) [0|3] "" Vector__XXX

CM_ SG_ 885 Bckl_Sw_D_Stat "Bckl_Sw_D_Stat [source enum/value-table reference]";
 SG_ Bckl_Sw_FP_Stat : 20|2@1+ (1,0) [0|3] "" Vector__XXX

CM_ SG_ 885 Bckl_Sw_FP_Stat "Bckl_Sw_FP_Stat [source enum/value-table reference]";
 SG_ CSL_Sw_FP_Stat : 18|2@1+ (1,0) [0|3] "" Vector__XXX

CM_ SG_ 885 CSL_Sw_FP_Stat "CSL_Sw_FP_Stat [source enum/value-table reference]";
 SG_ COD_Stat : 45|3@1+ (1,0) [0|7] "" Vector__XXX

CM_ SG_ 885 COD_Stat "COD_Stat [source enum/value-table reference]";
 SG_ SRS_DtlMsg01_Disp_Rq : 55|1@1+ (1,0) [0|1] "" Vector__XXX

CM_ SG_ 885 SRS_DtlMsg01_Disp_Rq "SRS_DtlMsg01_Disp_Rq [source boolean]";
 SG_ SRS_DtlMsg02_Disp_Rq : 54|1@1+ (1,0) [0|1] "" Vector__XXX

CM_ SG_ 885 SRS_DtlMsg02_Disp_Rq "SRS_DtlMsg02_Disp_Rq [source boolean]";
 SG_ SRS_DtlMsg03_Disp_Rq : 53|1@1+ (1,0) [0|1] "" Vector__XXX

CM_ SG_ 885 SRS_DtlMsg03_Disp_Rq "SRS_DtlMsg03_Disp_Rq [source boolean]";
 SG_ SRS_DtlMsg04_Disp_Rq : 52|1@1+ (1,0) [0|1] "" Vector__XXX

CM_ SG_ 885 SRS_DtlMsg04_Disp_Rq "SRS_DtlMsg04_Disp_Rq [source boolean]";
 SG_ SRS_DtlMsg05_Disp_Rq : 51|1@1+ (1,0) [0|1] "" Vector__XXX

CM_ SG_ 885 SRS_DtlMsg05_Disp_Rq "SRS_DtlMsg05_Disp_Rq [source boolean]";
 SG_ SRS_DtlMsg06_Disp_Rq : 50|1@1+ (1,0) [0|1] "" Vector__XXX

CM_ SG_ 885 SRS_DtlMsg06_Disp_Rq "SRS_DtlMsg06_Disp_Rq [source boolean]";
 SG_ SRS_DtlMsg07_Disp_Rq : 49|1@1+ (1,0) [0|1] "" Vector__XXX

CM_ SG_ 885 SRS_DtlMsg07_Disp_Rq "SRS_DtlMsg07_Disp_Rq [source boolean]";
 SG_ SRS_DtlMsg08_Disp_Rq : 48|1@1+ (1,0) [0|1] "" Vector__XXX

CM_ SG_ 885 SRS_DtlMsg08_Disp_Rq "SRS_DtlMsg08_Disp_Rq [source boolean]";
 SG_ SRS_DtlMsg09_Disp_Rq : 63|1@1+ (1,0) [0|1] "" Vector__XXX

CM_ SG_ 885 SRS_DtlMsg09_Disp_Rq "SRS_DtlMsg09_Disp_Rq [source boolean]";
 SG_ SRS_DtlMsg10_Disp_Rq : 62|1@1+ (1,0) [0|1] "" Vector__XXX

CM_ SG_ 885 SRS_DtlMsg10_Disp_Rq "SRS_DtlMsg10_Disp_Rq [source boolean]";
 SG_ SRS_DtlMsg11_Disp_Rq : 61|1@1+ (1,0) [0|1] "" Vector__XXX

CM_ SG_ 885 SRS_DtlMsg11_Disp_Rq "SRS_DtlMsg11_Disp_Rq [source boolean]";
 SG_ SRS_DtlMsg12_Disp_Rq : 60|1@1+ (1,0) [0|1] "" Vector__XXX

CM_ SG_ 885 SRS_DtlMsg12_Disp_Rq "SRS_DtlMsg12_Disp_Rq [source boolean]";
 SG_ SRS_DtlMsg13_Disp_Rq : 59|1@1+ (1,0) [0|1] "" Vector__XXX

CM_ SG_ 885 SRS_DtlMsg13_Disp_Rq "SRS_DtlMsg13_Disp_Rq [source boolean]";
 SG_ SRS_DtlMsg14_Disp_Rq : 58|1@1+ (1,0) [0|1] "" Vector__XXX

CM_ SG_ 885 SRS_DtlMsg14_Disp_Rq "SRS_DtlMsg14_Disp_Rq [source boolean]";
 SG_ SRS_DtlMsg15_Disp_Rq : 57|1@1+ (1,0) [0|1] "" Vector__XXX

CM_ SG_ 885 SRS_DtlMsg15_Disp_Rq "SRS_DtlMsg15_Disp_Rq [source boolean]";
 SG_ SRS_DtlMsg16_Disp_Rq : 56|1@1+ (1,0) [0|1] "" Vector__XXX

CM_ SG_ 885 SRS_DtlMsg16_Disp_Rq "SRS_DtlMsg16_Disp_Rq [source boolean]";

BA_ "GenMsgCycleTime" BO_ 885 28;

BO_ 887 TP_PTS_IC33: 8 ESP_ABR
 SG_ TP_PTS_IC : 0|64@1+ (1,0) [0|9.22337203685e+18] "" Vector__XXX

CM_ SG_ 887 TP_PTS_IC "TP_PTS_IC [source string/raw data]";

BA_ "GenMsgCycleTime" BO_ 887 1;

BO_ 888 DTR_DISP_RQ: 8 ESP_ABR
 SG_ DTR_FltDisp_Rq_V2 : 4|4@1+ (1,0) [0|15] "" Vector__XXX

CM_ SG_ 888 DTR_FltDisp_Rq_V2 "DTR_FltDisp_Rq_V2 [source enum/value-table reference]";
 SG_ DTR_IndLmp_On_Rq : 3|1@1+ (1,0) [0|1] "" Vector__XXX

CM_ SG_ 888 DTR_IndLmp_On_Rq "DTR_IndLmp_On_Rq [source boolean]";
 SG_ DTR_Beep_Rq : 2|1@1+ (1,0) [0|1] "" Vector__XXX

CM_ SG_ 888 DTR_Beep_Rq "DTR_Beep_Rq [source boolean]";
 SG_ SRD_Off_GPS : 1|1@1+ (1,0) [0|1] "" Vector__XXX

CM_ SG_ 888 SRD_Off_GPS "SRD_Off_GPS [source boolean]";
 SG_ DTR_Disp_On_Rq : 0|1@1+ (1,0) [0|1] "" Vector__XXX

CM_ SG_ 888 DTR_Disp_On_Rq "DTR_Disp_On_Rq [source boolean]";
 SG_ DTR_Spd_Dsr : 8|8@1+ (1,0) [0|255] "km/h(mph)" Vector__XXX

CM_ SG_ 888 DTR_Spd_Dsr "DTR_Spd_Dsr";
 SG_ ObjIntrst_Dist : 16|8@1+ (1,0) [0|255] "m" Vector__XXX

CM_ SG_ 888 ObjIntrst_Dist "ObjIntrst_Dist";
 SG_ Dist_D_Dsr : 24|8@1+ (1,0) [0|255] "m" Vector__XXX

CM_ SG_ 888 Dist_D_Dsr "Dist_D_Dsr";
 SG_ DTR_CC_Enbl : 39|1@1+ (1,0) [0|1] "" Vector__XXX

CM_ SG_ 888 DTR_CC_Enbl "DTR_CC_Enbl [source boolean]";
 SG_ DTR_Disp_Blink_Rq : 38|1@1+ (1,0) [0|1] "" Vector__XXX

CM_ SG_ 888 DTR_Disp_Blink_Rq "DTR_Disp_Blink_Rq [source boolean]";
 SG_ DTR_SegDisp_On_Rq : 37|1@1+ (1,0) [0|1] "" Vector__XXX

CM_ SG_ 888 DTR_SegDisp_On_Rq "DTR_SegDisp_On_Rq [source boolean]";
 SG_ ObjIntrst_Dtct : 36|1@1+ (1,0) [0|1] "" Vector__XXX

CM_ SG_ 888 ObjIntrst_Dtct "ObjIntrst_Dtct [source boolean]";
 SG_ DTR_Enbl : 35|1@1+ (1,0) [0|1] "" Vector__XXX

CM_ SG_ 888 DTR_Enbl "DTR_Enbl [source boolean]";
 SG_ DTR_Msg1_Disp_Rq : 34|1@1+ (1,0) [0|1] "" Vector__XXX

CM_ SG_ 888 DTR_Msg1_Disp_Rq "DTR_Msg1_Disp_Rq [source boolean]";
 SG_ DTR_Msg2_Disp_Rq : 33|1@1+ (1,0) [0|1] "" Vector__XXX

CM_ SG_ 888 DTR_Msg2_Disp_Rq "DTR_Msg2_Disp_Rq [source boolean]";
 SG_ DTR_Msg3_Disp_Rq : 32|1@1+ (1,0) [0|1] "" Vector__XXX

CM_ SG_ 888 DTR_Msg3_Disp_Rq "DTR_Msg3_Disp_Rq [source boolean]";
 SG_ TargetVehSpd : 40|8@1+ (1,0) [0|255] "km/h(mph)" Vector__XXX

CM_ SG_ 888 TargetVehSpd "TargetVehSpd";
 SG_ AS_Actv_V3 : 54|2@1+ (1,0) [0|3] "" Vector__XXX

CM_ SG_ 888 AS_Actv_V3 "AS_Actv_V3 [source enum/value-table reference]";
 SG_ DTR_DistWarn_Enbl : 51|1@1+ (1,0) [0|1] "" Vector__XXX

CM_ SG_ 888 DTR_DistWarn_Enbl "DTR_DistWarn_Enbl [source boolean]";
 SG_ DTR_Avl_Ind : 50|1@1+ (1,0) [0|1] "" Vector__XXX

CM_ SG_ 888 DTR_Avl_Ind "DTR_Avl_Ind [source boolean]";
 SG_ DTR_Ovr_D : 49|1@1+ (1,0) [0|1] "" Vector__XXX

CM_ SG_ 888 DTR_Ovr_D "DTR_Ovr_D [source boolean]";
 SG_ MinIndTm_Reset_Rq : 48|1@1+ (1,0) [0|1] "" Vector__XXX

CM_ SG_ 888 MinIndTm_Reset_Rq "MinIndTm_Reset_Rq [source boolean]";
 SG_ AS_MsgDisp_Rq_V4 : 59|5@1+ (1,0) [0|31] "" Vector__XXX

CM_ SG_ 888 AS_MsgDisp_Rq_V4 "AS_MsgDisp_Rq_V4 [source enum/value-table reference]";
 SG_ PKAS_FltDisp_Rq : 56|3@1+ (1,0) [0|7] "" Vector__XXX

CM_ SG_ 888 PKAS_FltDisp_Rq "PKAS_FltDisp_Rq [source enum/value-table reference]";

BA_ "GenMsgCycleTime" BO_ 888 24;

BO_ 889 SPC_A3: 6 ESP_ABR
 SG_ SPC_ErrMsg1_Disp_Rq : 7|1@1+ (1,0) [0|1] "" Vector__XXX

CM_ SG_ 889 SPC_ErrMsg1_Disp_Rq "SPC_ErrMsg1_Disp_Rq [source boolean]";
 SG_ SPC_ErrMsg2_Disp_Rq : 6|1@1+ (1,0) [0|1] "" Vector__XXX

CM_ SG_ 889 SPC_ErrMsg2_Disp_Rq "SPC_ErrMsg2_Disp_Rq [source boolean]";
 SG_ SPC_ErrMsg3_Disp_Rq : 5|1@1+ (1,0) [0|1] "" Vector__XXX

CM_ SG_ 889 SPC_ErrMsg3_Disp_Rq "SPC_ErrMsg3_Disp_Rq [source boolean]";
 SG_ SPC_Msg1_Disp_Rq : 3|1@1+ (1,0) [0|1] "" Vector__XXX

CM_ SG_ 889 SPC_Msg1_Disp_Rq "SPC_Msg1_Disp_Rq [source boolean]";
 SG_ SPC_Msg3_Disp_Rq : 1|1@1+ (1,0) [0|1] "" Vector__XXX

CM_ SG_ 889 SPC_Msg3_Disp_Rq "SPC_Msg3_Disp_Rq [source boolean]";
 SG_ SuspLvlAdjSwLED_Rq : 14|2@1+ (1,0) [0|3] "" Vector__XXX

CM_ SG_ 889 SuspLvlAdjSwLED_Rq "SuspLvlAdjSwLED_Rq [source enum/value-table reference]";
 SG_ ADC_SwLED_Rq : 12|2@1+ (1,0) [0|3] "" Vector__XXX

CM_ SG_ 889 ADC_SwLED_Rq "ADC_SwLED_Rq [source enum/value-table reference]";
 SG_ ADC_Stat : 11|1@1+ (1,0) [0|1] "" Vector__XXX

CM_ SG_ 889 ADC_Stat "ADC_Stat [source boolean]";
 SG_ VehLvlCtrl_Stat : 10|1@1+ (1,0) [0|1] "" Vector__XXX

CM_ SG_ 889 VehLvlCtrl_Stat "VehLvlCtrl_Stat [source boolean]";
 SG_ SPC_Msg5_Disp_Rq : 9|1@1+ (1,0) [0|1] "" Vector__XXX

CM_ SG_ 889 SPC_Msg5_Disp_Rq "SPC_Msg5_Disp_Rq [source boolean]";
 SG_ SPC_Msg6_Disp_Rq : 8|1@1+ (1,0) [0|1] "" Vector__XXX

CM_ SG_ 889 SPC_Msg6_Disp_Rq "SPC_Msg6_Disp_Rq [source boolean]";
 SG_ SPC_Msg7_Disp_Rq : 40|1@1+ (1,0) [0|1] "" Vector__XXX

CM_ SG_ 889 SPC_Msg7_Disp_Rq "SPC_Msg7_Disp_Rq [source boolean]";

BA_ "GenMsgCycleTime" BO_ 889 12;

BO_ 890 EIS_A3: 7 ESP_ABR
 SG_ KeyId_EIS : 0|32@1+ (1,0) [0|4294967295] "" Vector__XXX

CM_ SG_ 890 KeyId_EIS "KeyId_EIS";
 SG_ Odo_EIS : 32|24@1+ (0.10000000149,0) [0|1677721.525] "km" Vector__XXX

CM_ SG_ 890 Odo_EIS "Odo_EIS";

BA_ "GenMsgCycleTime" BO_ 890 2;

BO_ 892 TP_IC_PTS33: 8 ESP_ABR
 SG_ TP_IC_PTS : 0|64@1+ (1,0) [0|9.22337203685e+18] "" Vector__XXX

CM_ SG_ 892 TP_IC_PTS "TP_IC_PTS [source string/raw data]";

BA_ "GenMsgCycleTime" BO_ 892 1;

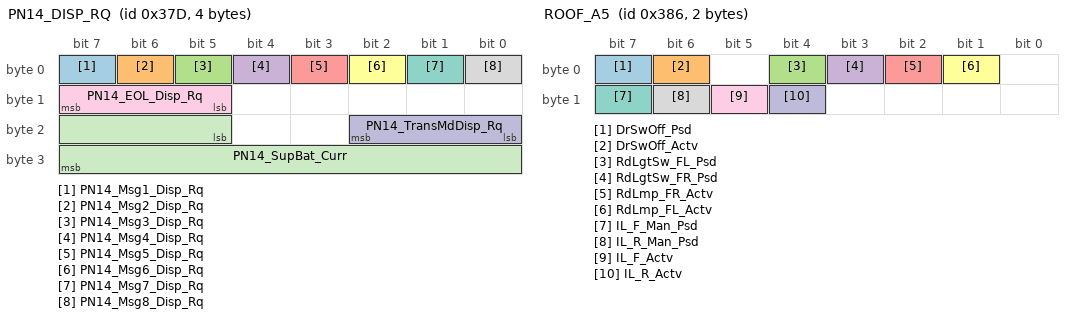
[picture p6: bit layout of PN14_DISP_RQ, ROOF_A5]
BO_ 893 PN14_DISP_RQ: 4 ESP_ABR
 SG_ PN14_Msg1_Disp_Rq : 7|1@1+ (1,0) [0|1] "" Vector__XXX

CM_ SG_ 893 PN14_Msg1_Disp_Rq "PN14_Msg1_Disp_Rq [source boolean]";
 SG_ PN14_Msg2_Disp_Rq : 6|1@1+ (1,0) [0|1] "" Vector__XXX

CM_ SG_ 893 PN14_Msg2_Disp_Rq "PN14_Msg2_Disp_Rq [source boolean]";
 SG_ PN14_Msg3_Disp_Rq : 5|1@1+ (1,0) [0|1] "" Vector__XXX

CM_ SG_ 893 PN14_Msg3_Disp_Rq "PN14_Msg3_Disp_Rq [source boolean]";
 SG_ PN14_Msg4_Disp_Rq : 4|1@1+ (1,0) [0|1] "" Vector__XXX

CM_ SG_ 893 PN14_Msg4_Disp_Rq "PN14_Msg4_Disp_Rq [source boolean]";
 SG_ PN14_Msg5_Disp_Rq : 3|1@1+ (1,0) [0|1] "" Vector__XXX

CM_ SG_ 893 PN14_Msg5_Disp_Rq "PN14_Msg5_Disp_Rq [source boolean]";
 SG_ PN14_Msg6_Disp_Rq : 2|1@1+ (1,0) [0|1] "" Vector__XXX

CM_ SG_ 893 PN14_Msg6_Disp_Rq "PN14_Msg6_Disp_Rq [source boolean]";
 SG_ PN14_Msg7_Disp_Rq : 1|1@1+ (1,0) [0|1] "" Vector__XXX

CM_ SG_ 893 PN14_Msg7_Disp_Rq "PN14_Msg7_Disp_Rq [source boolean]";
 SG_ PN14_Msg8_Disp_Rq : 0|1@1+ (1,0) [0|1] "" Vector__XXX

CM_ SG_ 893 PN14_Msg8_Disp_Rq "PN14_Msg8_Disp_Rq [source boolean]";
 SG_ PN14_EOL_Disp_Rq : 13|3@1+ (1,0) [0|7] "" Vector__XXX

CM_ SG_ 893 PN14_EOL_Disp_Rq "PN14_EOL_Disp_Rq [source enum/value-table reference]";
 SG_ PN14_TransMdDisp_Rq : 16|3@1+ (1,0) [0|7] "" Vector__XXX

CM_ SG_ 893 PN14_TransMdDisp_Rq "PN14_TransMdDisp_Rq [source enum/value-table reference]";
 SG_ PN14_SupBat_Curr : 21|11@1+ (0.10000000149,-102.400001526) [-102.400001526|102.300001524] "A" Vector__XXX

CM_ SG_ 893 PN14_SupBat_Curr "PN14_SupBat_Curr";

BA_ "GenMsgCycleTime" BO_ 893 11;

BO_ 894 DCL_APD_STAT: 3 ESP_ABR
 SG_ DCL_Accel_X_BhvrIdx : 0|8@1+ (1,0) [0|255] "" Vector__XXX

CM_ SG_ 894 DCL_Accel_X_BhvrIdx "DCL_Accel_X_BhvrIdx";
 SG_ DCL_Accel_Y_BhvrIdx : 8|8@1+ (1,0) [0|255] "" Vector__XXX

CM_ SG_ 894 DCL_Accel_Y_BhvrIdx "DCL_Accel_Y_BhvrIdx";
 SG_ DCL_BrkBhvrIdx : 16|8@1+ (1,0) [0|255] "" Vector__XXX

CM_ SG_ 894 DCL_BrkBhvrIdx "DCL_BrkBhvrIdx";

BA_ "GenMsgCycleTime" BO_ 894 3;

BO_ 895 TP_RDU_IC7: 8 ESP_ABR
 SG_ TP_RDU_IC : 0|64@1+ (1,0) [0|9.22337203685e+18] "" Vector__XXX

CM_ SG_ 895 TP_RDU_IC "TP_RDU_IC [source string/raw data]";

BA_ "GenMsgCycleTime" BO_ 895 1;

BO_ 902 ROOF_A5: 2 ESP_ABR
 SG_ DrSwOff_Psd : 7|1@1+ (1,0) [0|1] "" Vector__XXX

CM_ SG_ 902 DrSwOff_Psd "DrSwOff_Psd [source boolean]";
 SG_ DrSwOff_Actv : 6|1@1+ (1,0) [0|1] "" Vector__XXX

CM_ SG_ 902 DrSwOff_Actv "DrSwOff_Actv [source boolean]";
 SG_ RdLgtSw_FL_Psd : 4|1@1+ (1,0) [0|1] "" Vector__XXX

CM_ SG_ 902 RdLgtSw_FL_Psd "RdLgtSw_FL_Psd [source boolean]";
 SG_ RdLgtSw_FR_Psd : 3|1@1+ (1,0) [0|1] "" Vector__XXX

CM_ SG_ 902 RdLgtSw_FR_Psd "RdLgtSw_FR_Psd [source boolean]";
 SG_ RdLmp_FR_Actv : 2|1@1+ (1,0) [0|1] "" Vector__XXX

CM_ SG_ 902 RdLmp_FR_Actv "RdLmp_FR_Actv [source boolean]";
 SG_ RdLmp_FL_Actv : 1|1@1+ (1,0) [0|1] "" Vector__XXX

CM_ SG_ 902 RdLmp_FL_Actv "RdLmp_FL_Actv [source boolean]";
 SG_ IL_F_Man_Psd : 15|1@1+ (1,0) [0|1] "" Vector__XXX

CM_ SG_ 902 IL_F_Man_Psd "IL_F_Man_Psd [source boolean]";
 SG_ IL_R_Man_Psd : 14|1@1+ (1,0) [0|1] "" Vector__XXX

CM_ SG_ 902 IL_R_Man_Psd "IL_R_Man_Psd [source boolean]";
 SG_ IL_F_Actv : 13|1@1+ (1,0) [0|1] "" Vector__XXX

CM_ SG_ 902 IL_F_Actv "IL_F_Actv [source boolean]";
 SG_ IL_R_Actv : 12|1@1+ (1,0) [0|1] "" Vector__XXX

CM_ SG_ 902 IL_R_Actv "IL_R_Actv [source boolean]";

BA_ "GenMsgCycleTime" BO_ 902 10;

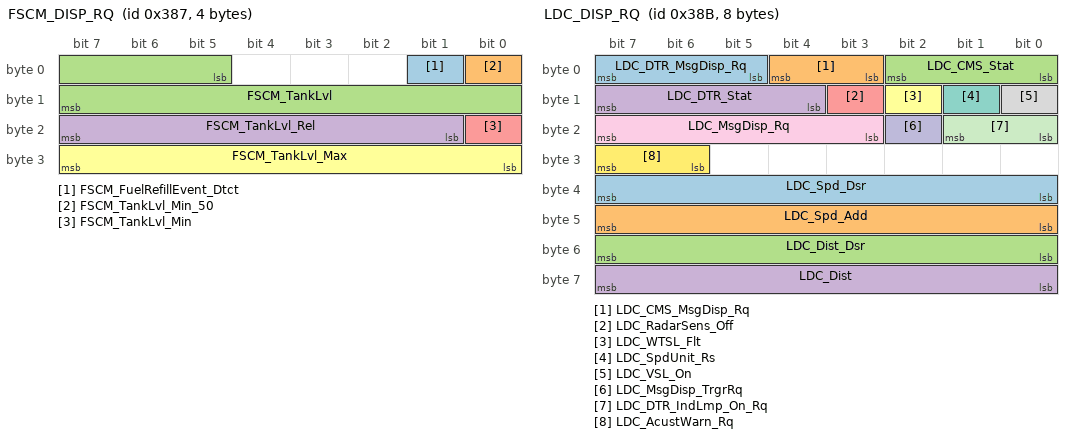
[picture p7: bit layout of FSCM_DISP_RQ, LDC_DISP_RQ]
BO_ 903 FSCM_DISP_RQ: 4 ESP_ABR
 SG_ FSCM_FuelRefillEvent_Dtct : 1|1@1+ (1,0) [0|1] "" Vector__XXX

CM_ SG_ 903 FSCM_FuelRefillEvent_Dtct "FSCM_FuelRefillEvent_Dtct [source boolean]";
 SG_ FSCM_TankLvl_Min_50 : 0|1@1+ (1,0) [0|1] "" Vector__XXX

CM_ SG_ 903 FSCM_TankLvl_Min_50 "FSCM_TankLvl_Min_50 [source boolean]";
 SG_ FSCM_TankLvl : 5|11@1+ (0.10000000149,0) [0|204.70000305] "l" Vector__XXX

CM_ SG_ 903 FSCM_TankLvl "FSCM_TankLvl";
 SG_ FSCM_TankLvl_Rel : 17|7@1+ (1,0) [0|127] "%" Vector__XXX

CM_ SG_ 903 FSCM_TankLvl_Rel "FSCM_TankLvl_Rel";
 SG_ FSCM_TankLvl_Min : 16|1@1+ (1,0) [0|1] "" Vector__XXX

CM_ SG_ 903 FSCM_TankLvl_Min "FSCM_TankLvl_Min [source boolean]";
 SG_ FSCM_TankLvl_Max : 24|8@1+ (1,0) [0|255] "l" Vector__XXX

CM_ SG_ 903 FSCM_TankLvl_Max "FSCM_TankLvl_Max";

BA_ "GenMsgCycleTime" BO_ 903 6;

BO_ 907 LDC_DISP_RQ: 8 ESP_ABR
 SG_ LDC_DTR_MsgDisp_Rq : 5|3@1+ (1,0) [0|7] "" Vector__XXX

CM_ SG_ 907 LDC_DTR_MsgDisp_Rq "LDC_DTR_MsgDisp_Rq [source enum/value-table reference]";
 SG_ LDC_CMS_MsgDisp_Rq : 3|2@1+ (1,0) [0|3] "" Vector__XXX

CM_ SG_ 907 LDC_CMS_MsgDisp_Rq "LDC_CMS_MsgDisp_Rq [source enum/value-table reference]";
 SG_ LDC_CMS_Stat : 0|3@1+ (1,0) [0|7] "" Vector__XXX

CM_ SG_ 907 LDC_CMS_Stat "LDC_CMS_Stat [source enum/value-table reference]";
 SG_ LDC_DTR_Stat : 12|4@1+ (1,0) [0|15] "" Vector__XXX

CM_ SG_ 907 LDC_DTR_Stat "LDC_DTR_Stat [source enum/value-table reference]";
 SG_ LDC_RadarSens_Off : 11|1@1+ (1,0) [0|1] "" Vector__XXX

CM_ SG_ 907 LDC_RadarSens_Off "LDC_RadarSens_Off [source boolean]";
 SG_ LDC_WTSL_Flt : 10|1@1+ (1,0) [0|1] "" Vector__XXX

CM_ SG_ 907 LDC_WTSL_Flt "LDC_WTSL_Flt [source boolean]";
 SG_ LDC_SpdUnit_Rs : 9|1@1+ (1,0) [0|1] "" Vector__XXX

CM_ SG_ 907 LDC_SpdUnit_Rs "LDC_SpdUnit_Rs [source boolean]";
 SG_ LDC_VSL_On : 8|1@1+ (1,0) [0|1] "" Vector__XXX

CM_ SG_ 907 LDC_VSL_On "LDC_VSL_On [source boolean]";
 SG_ LDC_MsgDisp_Rq : 19|5@1+ (1,0) [0|31] "" Vector__XXX

CM_ SG_ 907 LDC_MsgDisp_Rq "LDC_MsgDisp_Rq [source enum/value-table reference]";
 SG_ LDC_MsgDisp_TrgrRq : 18|1@1+ (1,0) [0|1] "" Vector__XXX

CM_ SG_ 907 LDC_MsgDisp_TrgrRq "LDC_MsgDisp_TrgrRq [source boolean]";
 SG_ LDC_DTR_IndLmp_On_Rq : 16|2@1+ (1,0) [0|3] "" Vector__XXX

CM_ SG_ 907 LDC_DTR_IndLmp_On_Rq "LDC_DTR_IndLmp_On_Rq [source enum/value-table reference]";
 SG_ LDC_AcustWarn_Rq : 30|2@1+ (1,0) [0|3] "" Vector__XXX

CM_ SG_ 907 LDC_AcustWarn_Rq "LDC_AcustWarn_Rq [source enum/value-table reference]";
 SG_ LDC_Spd_Dsr : 32|8@1+ (1,0) [0|255] "km/h(mph)" Vector__XXX

CM_ SG_ 907 LDC_Spd_Dsr "LDC_Spd_Dsr";
 SG_ LDC_Spd_Add : 40|8@1+ (1,0) [0|255] "km/h(mph)" Vector__XXX

CM_ SG_ 907 LDC_Spd_Add "LDC_Spd_Add";
 SG_ LDC_Dist_Dsr : 48|8@1+ (1,0) [0|255] "m" Vector__XXX

CM_ SG_ 907 LDC_Dist_Dsr "LDC_Dist_Dsr";
 SG_ LDC_Dist : 56|8@1+ (1,0) [0|255] "m" Vector__XXX

CM_ SG_ 907 LDC_Dist "LDC_Dist";

BA_ "GenMsgCycleTime" BO_ 907 16;

BO_ 909 NV_DISP_CTRL_TGW: 1 ESP_ABR
 SG_ NV_DispLnk_Flt_TGW : 7|1@1+ (1,0) [0|1] "" Vector__XXX

CM_ SG_ 909 NV_DispLnk_Flt_TGW "NV_DispLnk_Flt_TGW [source boolean]";
 SG_ NV_Disp_Actv_TGW : 6|1@1+ (1,0) [0|1] "" Vector__XXX

CM_ SG_ 909 NV_Disp_Actv_TGW "NV_Disp_Actv_TGW [source boolean]";

BA_ "GenMsgCycleTime" BO_ 909 2;

BO_ 911 SLA_DISP_RQ: 8 ESP_ABR
 SG_ SLA_Disp_Rq : 0|64@1+ (1,0) [0|9.22337203685e+18] "" Vector__XXX

CM_ SG_ 911 SLA_Disp_Rq "SLA_Disp_Rq [source string/raw data]";

BA_ "GenMsgCycleTime" BO_ 911 1;

BO_ 925 IC_A2: 8 ESP_ABR
 SG_ TankLvl_Disp : 1|7@1+ (1,0) [0|127] "l" Vector__XXX

CM_ SG_ 925 TankLvl_Disp "TankLvl_Disp";
 SG_ TankLvl_Min : 0|1@1+ (1,0) [0|1] "" Vector__XXX

CM_ SG_ 925 TankLvl_Min "TankLvl_Min [source boolean]";
 SG_ SPCR_Conf_IC : 14|2@1+ (1,0) [0|3] "" Vector__XXX

CM_ SG_ 925 SPCR_Conf_IC "SPCR_Conf_IC [source enum/value-table reference]";
 SG_ SPCR_Flt_IC : 12|2@1+ (1,0) [0|3] "" Vector__XXX

CM_ SG_ 925 SPCR_Flt_IC "SPCR_Flt_IC [source enum/value-table reference]";
 SG_ ESP_Md_Rq : 10|2@1+ (1,0) [0|3] "" Vector__XXX

CM_ SG_ 925 ESP_Md_Rq "ESP_Md_Rq [source enum/value-table reference]";
 SG_ PreHtIndLmp_Flt : 8|1@1+ (1,0) [0|1] "" Vector__XXX

CM_ SG_ 925 PreHtIndLmp_Flt "PreHtIndLmp_Flt [source boolean]";
 SG_ TankRng : 16|16@1+ (1,0) [0|65535] "km" Vector__XXX

CM_ SG_ 925 TankRng "TankRng";
 SG_ VehTireMaxSpd : 32|8@1+ (1,0) [0|255] "km/h" Vector__XXX

CM_ SG_ 925 VehTireMaxSpd "VehTireMaxSpd";
 SG_ UnitGap : 47|1@1+ (1,0) [0|1] "" Vector__XXX

CM_ SG_ 925 UnitGap "UnitGap [source boolean]";
 SG_ UnitVehSpd : 46|1@1+ (1,0) [0|1] "" Vector__XXX

CM_ SG_ 925 UnitVehSpd "UnitVehSpd [source boolean]";
 SG_ SPEEDO_Cal : 45|1@1+ (1,0) [0|1] "" Vector__XXX

CM_ SG_ 925 SPEEDO_Cal "SPEEDO_Cal [source boolean]";
 SG_ SPEEDO_Seg_Avl : 44|1@1+ (1,0) [0|1] "" Vector__XXX

CM_ SG_ 925 SPEEDO_Seg_Avl "SPEEDO_Seg_Avl [source boolean]";
 SG_ DTR_Disp_Off : 43|1@1+ (1,0) [0|1] "" Vector__XXX

CM_ SG_ 925 DTR_Disp_Off "DTR_Disp_Off [source boolean]";
 SG_ DTR_Disp_Actv : 42|1@1+ (1,0) [0|1] "" Vector__XXX

CM_ SG_ 925 DTR_Disp_Actv "DTR_Disp_Actv [source boolean]";
 SG_ DTR_VisualWarn_Off : 41|1@1+ (1,0) [0|1] "" Vector__XXX

CM_ SG_ 925 DTR_VisualWarn_Off "DTR_VisualWarn_Off [source boolean]";
 SG_ DTR_AcustWarn_Off : 40|1@1+ (1,0) [0|1] "" Vector__XXX

CM_ SG_ 925 DTR_AcustWarn_Off "DTR_AcustWarn_Off [source boolean]";
 SG_ RollTestMd_Actv : 54|2@1+ (1,0) [0|3] "" Vector__XXX

CM_ SG_ 925 RollTestMd_Actv "RollTestMd_Actv [source enum/value-table reference]";
 SG_ Parity_RollTestMd_Actv : 53|1@1+ (1,0) [0|1] "" Vector__XXX

CM_ SG_ 925 Parity_RollTestMd_Actv "Parity_RollTestMd_Actv [source boolean]";
 SG_ DrowDtct_On_Rq : 52|1@1+ (1,0) [0|1] "" Vector__XXX

CM_ SG_ 925 DrowDtct_On_Rq "DrowDtct_On_Rq [source boolean]";
 SG_ DrowWarnDisp_Stat : 49|3@1+ (1,0) [0|7] "" Vector__XXX

CM_ SG_ 925 DrowWarnDisp_Stat "DrowWarnDisp_Stat [source enum/value-table reference]";
 SG_ EPkBrkMd_Rq_V2 : 61|3@1+ (1,0) [0|7] "" Vector__XXX

CM_ SG_ 925 EPkBrkMd_Rq_V2 "EPkBrkMd_Rq_V2 [source enum/value-table reference]";
 SG_ MC_IC_A2 : 57|4@1+ (1,0) [0|15] "" Vector__XXX

CM_ SG_ 925 MC_IC_A2 "MC_IC_A2";

BA_ "GenMsgCycleTime" BO_ 925 22;

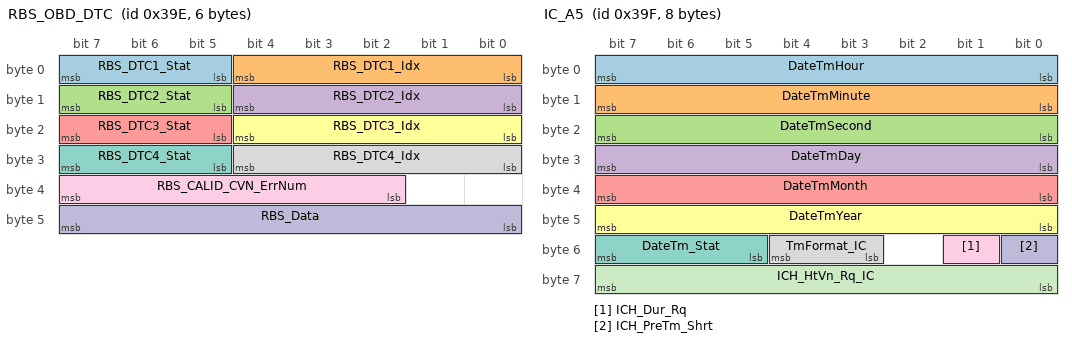
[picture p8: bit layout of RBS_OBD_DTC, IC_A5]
BO_ 926 RBS_OBD_DTC: 6 ESP_ABR
 SG_ RBS_DTC1_Stat : 5|3@1+ (1,0) [0|7] "" Vector__XXX

CM_ SG_ 926 RBS_DTC1_Stat "RBS_DTC1_Stat [source enum/value-table reference]";
 SG_ RBS_DTC1_Idx : 0|5@1+ (1,0) [0|31] "" Vector__XXX

CM_ SG_ 926 RBS_DTC1_Idx "RBS_DTC1_Idx";
 SG_ RBS_DTC2_Stat : 13|3@1+ (1,0) [0|7] "" Vector__XXX

CM_ SG_ 926 RBS_DTC2_Stat "RBS_DTC2_Stat [source enum/value-table reference]";
 SG_ RBS_DTC2_Idx : 8|5@1+ (1,32) [32|63] "" Vector__XXX

CM_ SG_ 926 RBS_DTC2_Idx "RBS_DTC2_Idx";
 SG_ RBS_DTC3_Stat : 21|3@1+ (1,0) [0|7] "" Vector__XXX

CM_ SG_ 926 RBS_DTC3_Stat "RBS_DTC3_Stat [source enum/value-table reference]";
 SG_ RBS_DTC3_Idx : 16|5@1+ (1,64) [64|95] "" Vector__XXX

CM_ SG_ 926 RBS_DTC3_Idx "RBS_DTC3_Idx";
 SG_ RBS_DTC4_Stat : 29|3@1+ (1,0) [0|7] "" Vector__XXX

CM_ SG_ 926 RBS_DTC4_Stat "RBS_DTC4_Stat [source enum/value-table reference]";
 SG_ RBS_DTC4_Idx : 24|5@1+ (1,96) [96|127] "" Vector__XXX

CM_ SG_ 926 RBS_DTC4_Idx "RBS_DTC4_Idx";
 SG_ RBS_CALID_CVN_ErrNum : 34|6@1+ (1,0) [0|63] "" Vector__XXX

CM_ SG_ 926 RBS_CALID_CVN_ErrNum "RBS_CALID_CVN_ErrNum";
 SG_ RBS_Data : 40|8@1+ (1,0) [0|255] "" Vector__XXX

CM_ SG_ 926 RBS_Data "RBS_Data";

BA_ "GenMsgCycleTime" BO_ 926 10;

BO_ 927 IC_A5: 8 ESP_ABR
 SG_ DateTmHour : 0|8@1+ (1,0) [0|255] "h" Vector__XXX

CM_ SG_ 927 DateTmHour "DateTmHour";
 SG_ DateTmMinute : 8|8@1+ (1,0) [0|255] "min" Vector__XXX

CM_ SG_ 927 DateTmMinute "DateTmMinute";
 SG_ DateTmSecond : 16|8@1+ (1,0) [0|255] "s" Vector__XXX

CM_ SG_ 927 DateTmSecond "DateTmSecond";
 SG_ DateTmDay : 24|8@1+ (1,0) [0|255] "Days" Vector__XXX

CM_ SG_ 927 DateTmDay "DateTmDay";
 SG_ DateTmMonth : 32|8@1+ (1,0) [0|255] "Months" Vector__XXX

CM_ SG_ 927 DateTmMonth "DateTmMonth";
 SG_ DateTmYear : 40|8@1+ (1,0) [0|255] "Years" Vector__XXX

CM_ SG_ 927 DateTmYear "DateTmYear";
 SG_ DateTm_Stat : 53|3@1+ (1,0) [0|7] "" Vector__XXX

CM_ SG_ 927 DateTm_Stat "DateTm_Stat [source enum/value-table reference]";
 SG_ TmFormat_IC : 51|2@1+ (1,0) [0|3] "" Vector__XXX

CM_ SG_ 927 TmFormat_IC "TmFormat_IC [source enum/value-table reference]";
 SG_ ICH_Dur_Rq : 49|1@1+ (1,0) [0|1] "" Vector__XXX

CM_ SG_ 927 ICH_Dur_Rq "ICH_Dur_Rq [source boolean]";
 SG_ ICH_PreTm_Shrt : 48|1@1+ (1,0) [0|1] "" Vector__XXX

CM_ SG_ 927 ICH_PreTm_Shrt "ICH_PreTm_Shrt [source boolean]";
 SG_ ICH_HtVn_Rq_IC : 56|8@1+ (1,0) [0|255] "min" Vector__XXX

CM_ SG_ 927 ICH_HtVn_Rq_IC "ICH_HtVn_Rq_IC";

BA_ "GenMsgCycleTime" BO_ 927 11;

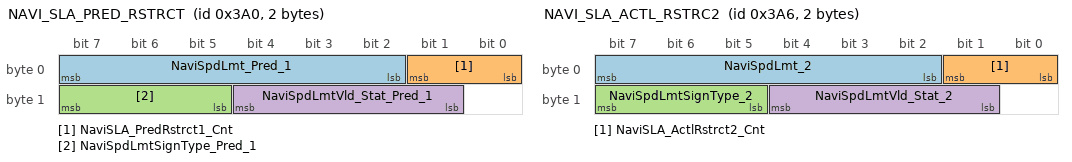
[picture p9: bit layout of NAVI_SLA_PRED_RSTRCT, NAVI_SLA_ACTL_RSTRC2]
BO_ 928 NAVI_SLA_PRED_RSTRCT: 2 ESP_ABR
 SG_ NaviSpdLmt_Pred_1 : 2|6@1+ (5,0) [0|315] "km/h(mph)" Vector__XXX

CM_ SG_ 928 NaviSpdLmt_Pred_1 "NaviSpdLmt_Pred_1";
 SG_ NaviSLA_PredRstrct1_Cnt : 0|2@1+ (1,0) [0|3] "" Vector__XXX

CM_ SG_ 928 NaviSLA_PredRstrct1_Cnt "NaviSLA_PredRstrct1_Cnt";
 SG_ NaviSpdLmtSignType_Pred_1 : 13|3@1+ (1,0) [0|7] "" Vector__XXX

CM_ SG_ 928 NaviSpdLmtSignType_Pred_1 "NaviSpdLmtSignType_Pred_1 [source enum/value-table reference]";
 SG_ NaviSpdLmtVld_Stat_Pred_1 : 9|4@1+ (1,0) [0|15] "" Vector__XXX

CM_ SG_ 928 NaviSpdLmtVld_Stat_Pred_1 "NaviSpdLmtVld_Stat_Pred_1 [source enum/value-table reference]";

BA_ "GenMsgCycleTime" BO_ 928 4;

BO_ 931 HVAC_OBD_DTC: 3 ESP_ABR
 SG_ HVAC_CALID_CVN_ErrNum : 2|6@1+ (1,0) [0|63] "" Vector__XXX

CM_ SG_ 931 HVAC_CALID_CVN_ErrNum "HVAC_CALID_CVN_ErrNum";
 SG_ HVAC_Data : 8|8@1+ (1,0) [0|255] "" Vector__XXX

CM_ SG_ 931 HVAC_Data "HVAC_Data";
 SG_ HVAC_DTC1_Stat : 21|3@1+ (1,0) [0|7] "" Vector__XXX

CM_ SG_ 931 HVAC_DTC1_Stat "HVAC_DTC1_Stat [source enum/value-table reference]";
 SG_ HVAC_DTC1_Idx : 16|5@1+ (1,0) [0|31] "" Vector__XXX

CM_ SG_ 931 HVAC_DTC1_Idx "HVAC_DTC1_Idx";

BA_ "GenMsgCycleTime" BO_ 931 4;

BO_ 934 NAVI_SLA_ACTL_RSTRC2: 2 ESP_ABR
 SG_ NaviSpdLmt_2 : 2|6@1+ (5,0) [0|315] "km/h(mph)" Vector__XXX

CM_ SG_ 934 NaviSpdLmt_2 "NaviSpdLmt_2";
 SG_ NaviSLA_ActlRstrct2_Cnt : 0|2@1+ (1,0) [0|3] "" Vector__XXX

CM_ SG_ 934 NaviSLA_ActlRstrct2_Cnt "NaviSLA_ActlRstrct2_Cnt";
 SG_ NaviSpdLmtSignType_2 : 13|3@1+ (1,0) [0|7] "" Vector__XXX

CM_ SG_ 934 NaviSpdLmtSignType_2 "NaviSpdLmtSignType_2 [source enum/value-table reference]";
 SG_ NaviSpdLmtVld_Stat_2 : 9|4@1+ (1,0) [0|15] "" Vector__XXX

CM_ SG_ 934 NaviSpdLmtVld_Stat_2 "NaviSpdLmtVld_Stat_2 [source enum/value-table reference]";

BA_ "GenMsgCycleTime" BO_ 934 4;

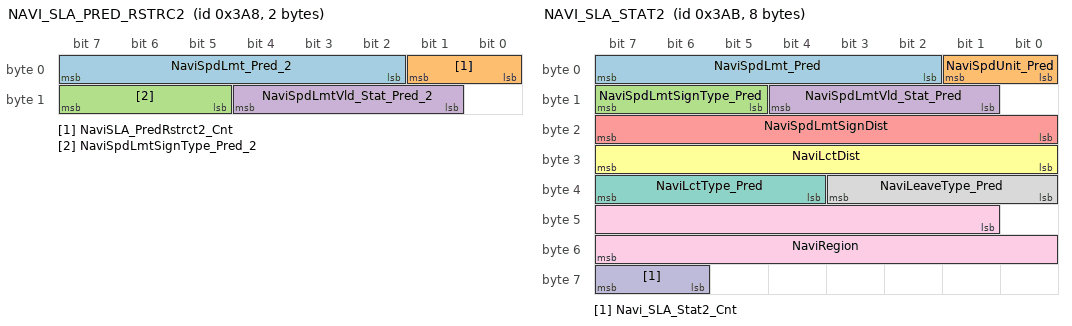
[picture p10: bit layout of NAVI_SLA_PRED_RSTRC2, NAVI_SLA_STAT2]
BO_ 936 NAVI_SLA_PRED_RSTRC2: 2 ESP_ABR
 SG_ NaviSpdLmt_Pred_2 : 2|6@1+ (5,0) [0|315] "km/h(mph)" Vector__XXX

CM_ SG_ 936 NaviSpdLmt_Pred_2 "NaviSpdLmt_Pred_2";
 SG_ NaviSLA_PredRstrct2_Cnt : 0|2@1+ (1,0) [0|3] "" Vector__XXX

CM_ SG_ 936 NaviSLA_PredRstrct2_Cnt "NaviSLA_PredRstrct2_Cnt";
 SG_ NaviSpdLmtSignType_Pred_2 : 13|3@1+ (1,0) [0|7] "" Vector__XXX

CM_ SG_ 936 NaviSpdLmtSignType_Pred_2 "NaviSpdLmtSignType_Pred_2 [source enum/value-table reference]";
 SG_ NaviSpdLmtVld_Stat_Pred_2 : 9|4@1+ (1,0) [0|15] "" Vector__XXX

CM_ SG_ 936 NaviSpdLmtVld_Stat_Pred_2 "NaviSpdLmtVld_Stat_Pred_2 [source enum/value-table reference]";

BA_ "GenMsgCycleTime" BO_ 936 4;

BO_ 939 NAVI_SLA_STAT2: 8 ESP_ABR
 SG_ NaviSpdLmt_Pred : 2|6@1+ (5,0) [0|315] "km/h(mph)" Vector__XXX

CM_ SG_ 939 NaviSpdLmt_Pred "NaviSpdLmt_Pred";
 SG_ NaviSpdUnit_Pred : 0|2@1+ (1,0) [0|3] "" Vector__XXX

CM_ SG_ 939 NaviSpdUnit_Pred "NaviSpdUnit_Pred [source enum/value-table reference]";
 SG_ NaviSpdLmtSignType_Pred : 13|3@1+ (1,0) [0|7] "" Vector__XXX

CM_ SG_ 939 NaviSpdLmtSignType_Pred "NaviSpdLmtSignType_Pred [source enum/value-table reference]";
 SG_ NaviSpdLmtVld_Stat_Pred : 9|4@1+ (1,0) [0|15] "" Vector__XXX

CM_ SG_ 939 NaviSpdLmtVld_Stat_Pred "NaviSpdLmtVld_Stat_Pred [source enum/value-table reference]";
 SG_ NaviSpdLmtSignDist : 16|8@1+ (2,0) [0|510] "m" Vector__XXX

CM_ SG_ 939 NaviSpdLmtSignDist "NaviSpdLmtSignDist";
 SG_ NaviLctDist : 24|8@1+ (2,0) [0|510] "m" Vector__XXX

CM_ SG_ 939 NaviLctDist "NaviLctDist";
 SG_ NaviLctType_Pred : 36|4@1+ (1,0) [0|15] "" Vector__XXX

CM_ SG_ 939 NaviLctType_Pred "NaviLctType_Pred [source enum/value-table reference]";
 SG_ NaviLeaveType_Pred : 32|4@1+ (1,0) [0|15] "" Vector__XXX

CM_ SG_ 939 NaviLeaveType_Pred "NaviLeaveType_Pred [source enum/value-table reference]";
 SG_ NaviRegion : 41|15@1+ (1,0) [0|32767] "" Vector__XXX

CM_ SG_ 939 NaviRegion "NaviRegion";
 SG_ Navi_SLA_Stat2_Cnt : 62|2@1+ (1,0) [0|3] "" Vector__XXX

CM_ SG_ 939 Navi_SLA_Stat2_Cnt "Navi_SLA_Stat2_Cnt";

BA_ "GenMsgCycleTime" BO_ 939 10;

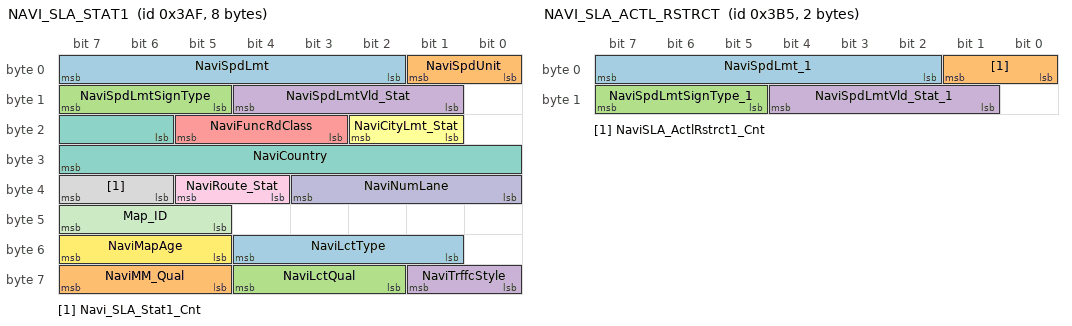
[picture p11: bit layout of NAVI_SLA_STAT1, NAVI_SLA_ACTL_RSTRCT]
BO_ 943 NAVI_SLA_STAT1: 8 ESP_ABR
 SG_ NaviSpdLmt : 2|6@1+ (5,0) [0|315] "km/h(mph)" Vector__XXX

CM_ SG_ 943 NaviSpdLmt "NaviSpdLmt";
 SG_ NaviSpdUnit : 0|2@1+ (1,0) [0|3] "" Vector__XXX

CM_ SG_ 943 NaviSpdUnit "NaviSpdUnit [source enum/value-table reference]";
 SG_ NaviSpdLmtSignType : 13|3@1+ (1,0) [0|7] "" Vector__XXX

CM_ SG_ 943 NaviSpdLmtSignType "NaviSpdLmtSignType [source enum/value-table reference]";
 SG_ NaviSpdLmtVld_Stat : 9|4@1+ (1,0) [0|15] "" Vector__XXX

CM_ SG_ 943 NaviSpdLmtVld_Stat "NaviSpdLmtVld_Stat [source enum/value-table reference]";
 SG_ NaviFuncRdClass : 19|3@1+ (1,0) [0|7] "" Vector__XXX

CM_ SG_ 943 NaviFuncRdClass "NaviFuncRdClass [source enum/value-table reference]";
 SG_ NaviCityLmt_Stat : 17|2@1+ (1,0) [0|3] "" Vector__XXX

CM_ SG_ 943 NaviCityLmt_Stat "NaviCityLmt_Stat [source enum/value-table reference]";
 SG_ NaviCountry : 22|10@1+ (1,0) [0|1023] "" Vector__XXX

CM_ SG_ 943 NaviCountry "NaviCountry";
 SG_ Navi_SLA_Stat1_Cnt : 38|2@1+ (1,0) [0|3] "" Vector__XXX

CM_ SG_ 943 Navi_SLA_Stat1_Cnt "Navi_SLA_Stat1_Cnt";
 SG_ NaviRoute_Stat : 36|2@1+ (1,0) [0|3] "" Vector__XXX

CM_ SG_ 943 NaviRoute_Stat "NaviRoute_Stat [source enum/value-table reference]";
 SG_ NaviNumLane : 32|4@1+ (1,0) [0|15] "" Vector__XXX

CM_ SG_ 943 NaviNumLane "NaviNumLane [source enum/value-table reference]";
 SG_ Map_ID : 45|3@1+ (1,0) [0|7] "" Vector__XXX

CM_ SG_ 943 Map_ID "Map_ID [source enum/value-table reference]";
 SG_ NaviMapAge : 53|3@1+ (1,0) [0|7] "" Vector__XXX

CM_ SG_ 943 NaviMapAge "NaviMapAge [source enum/value-table reference]";
 SG_ NaviLctType : 49|4@1+ (1,0) [0|15] "" Vector__XXX

CM_ SG_ 943 NaviLctType "NaviLctType [source enum/value-table reference]";
 SG_ NaviMM_Qual : 61|3@1+ (1,0) [0|7] "" Vector__XXX

CM_ SG_ 943 NaviMM_Qual "NaviMM_Qual [source enum/value-table reference]";
 SG_ NaviLctQual : 58|3@1+ (1,0) [0|7] "" Vector__XXX

CM_ SG_ 943 NaviLctQual "NaviLctQual [source enum/value-table reference]";
 SG_ NaviTrffcStyle : 56|2@1+ (1,0) [0|3] "" Vector__XXX

CM_ SG_ 943 NaviTrffcStyle "NaviTrffcStyle [source enum/value-table reference]";

BA_ "GenMsgCycleTime" BO_ 943 16;

BO_ 949 NAVI_SLA_ACTL_RSTRCT: 2 ESP_ABR
 SG_ NaviSpdLmt_1 : 2|6@1+ (5,0) [0|315] "km/h(mph)" Vector__XXX

CM_ SG_ 949 NaviSpdLmt_1 "NaviSpdLmt_1";
 SG_ NaviSLA_ActlRstrct1_Cnt : 0|2@1+ (1,0) [0|3] "" Vector__XXX

CM_ SG_ 949 NaviSLA_ActlRstrct1_Cnt "NaviSLA_ActlRstrct1_Cnt";
 SG_ NaviSpdLmtSignType_1 : 13|3@1+ (1,0) [0|7] "" Vector__XXX

CM_ SG_ 949 NaviSpdLmtSignType_1 "NaviSpdLmtSignType_1 [source enum/value-table reference]";
 SG_ NaviSpdLmtVld_Stat_1 : 9|4@1+ (1,0) [0|15] "" Vector__XXX

CM_ SG_ 949 NaviSpdLmtVld_Stat_1 "NaviSpdLmtVld_Stat_1 [source enum/value-table reference]";

BA_ "GenMsgCycleTime" BO_ 949 4;

BO_ 965 BODY_R2: 8 ESP_ABR
 SG_ SuspLvlAdjSw_Psd : 6|2@1+ (1,0) [0|3] "" Vector__XXX

CM_ SG_ 965 SuspLvlAdjSw_Psd "SuspLvlAdjSw_Psd [source enum/value-table reference]";
 SG_ VehDrvProgSw_Psd : 0|2@1+ (1,0) [0|3] "" Vector__XXX

CM_ SG_ 965 VehDrvProgSw_Psd "VehDrvProgSw_Psd [source enum/value-table reference]";
 SG_ ESP_Sw_Psd : 14|2@1+ (1,0) [0|3] "" Vector__XXX

CM_ SG_ 965 ESP_Sw_Psd "ESP_Sw_Psd [source enum/value-table reference]";
 SG_ NV_Sw_Psd : 12|2@1+ (1,0) [0|3] "" Vector__XXX

CM_ SG_ 965 NV_Sw_Psd "NV_Sw_Psd [source enum/value-table reference]";
 SG_ PTS_Sw_Psd : 8|2@1+ (1,0) [0|3] "" Vector__XXX

CM_ SG_ 965 PTS_Sw_Psd "PTS_Sw_Psd [source enum/value-table reference]";
 SG_ PKAS_Sw_Psd : 22|2@1+ (1,0) [0|3] "" Vector__XXX

CM_ SG_ 965 PKAS_Sw_Psd "PKAS_Sw_Psd [source enum/value-table reference]";
 SG_ TX_Actv : 18|1@1+ (1,0) [0|1] "" Vector__XXX

CM_ SG_ 965 TX_Actv "TX_Actv [source boolean]";
 SG_ DL_Sw_Psd : 17|1@1+ (1,0) [0|1] "" Vector__XXX

CM_ SG_ 965 DL_Sw_Psd "DL_Sw_Psd [source boolean]";
 SG_ CoolIndLmp_On_Rq : 16|1@1+ (1,0) [0|1] "" Vector__XXX

CM_ SG_ 965 CoolIndLmp_On_Rq "CoolIndLmp_On_Rq [source boolean]";
 SG_ BSM_WarnUnit_Lt_Stat : 34|2@1+ (1,0) [0|3] "" Vector__XXX

CM_ SG_ 965 BSM_WarnUnit_Lt_Stat "BSM_WarnUnit_Lt_Stat [source enum/value-table reference]";
 SG_ BSM_WarnUnit_Rt_Stat : 32|2@1+ (1,0) [0|3] "" Vector__XXX

CM_ SG_ 965 BSM_WarnUnit_Rt_Stat "BSM_WarnUnit_Rt_Stat [source enum/value-table reference]";
 SG_ ADC_Sw_Psd_V2 : 46|2@1+ (1,0) [0|3] "" Vector__XXX

CM_ SG_ 965 ADC_Sw_Psd_V2 "ADC_Sw_Psd_V2 [source enum/value-table reference]";
 SG_ Phonecall_SDS_Actv : 44|2@1+ (1,0) [0|3] "" Vector__XXX

CM_ SG_ 965 Phonecall_SDS_Actv "Phonecall_SDS_Actv [source enum/value-table reference]";
 SG_ Tlm_Sw_Psd : 42|2@1+ (1,0) [0|3] "" Vector__XXX

CM_ SG_ 965 Tlm_Sw_Psd "Tlm_Sw_Psd [source enum/value-table reference]";
 SG_ DSR_Sw_Psd : 40|2@1+ (1,0) [0|3] "" Vector__XXX

CM_ SG_ 965 DSR_Sw_Psd "DSR_Sw_Psd [source enum/value-table reference]";
 SG_ OffRoadSw_Psd : 54|2@1+ (1,0) [0|3] "" Vector__XXX

CM_ SG_ 965 OffRoadSw_Psd "OffRoadSw_Psd [source enum/value-table reference]";
 SG_ ADC_Sw_Psd_CTRL_L_V2 : 52|2@1+ (1,0) [0|3] "" Vector__XXX

CM_ SG_ 965 ADC_Sw_Psd_CTRL_L_V2 "ADC_Sw_Psd_CTRL_L_V2 [source enum/value-table reference]";
 SG_ SuspLvlAdjSw_Psd_CTRL_L : 50|2@1+ (1,0) [0|3] "" Vector__XXX

CM_ SG_ 965 SuspLvlAdjSw_Psd_CTRL_L "SuspLvlAdjSw_Psd_CTRL_L [source enum/value-table reference]";
 SG_ SSA_ECO_Sw_Psd_CTRL_U : 48|2@1+ (1,0) [0|3] "" Vector__XXX

CM_ SG_ 965 SSA_ECO_Sw_Psd_CTRL_U "SSA_ECO_Sw_Psd_CTRL_U [source enum/value-table reference]";
 SG_ IrLmp_Stat : 61|3@1+ (1,0) [0|7] "" Vector__XXX

CM_ SG_ 965 IrLmp_Stat "IrLmp_Stat [source enum/value-table reference]";

BA_ "GenMsgCycleTime" BO_ 965 20;

BO_ 980 CGW_OBD: 1 ESP_ABR
 SG_ AirTemp_Outsd_Sens_Stat : 5|3@1+ (1,0) [0|7] "" Vector__XXX

CM_ SG_ 980 AirTemp_Outsd_Sens_Stat "AirTemp_Outsd_Sens_Stat [source enum/value-table reference]";

BA_ "GenMsgCycleTime" BO_ 980 1;

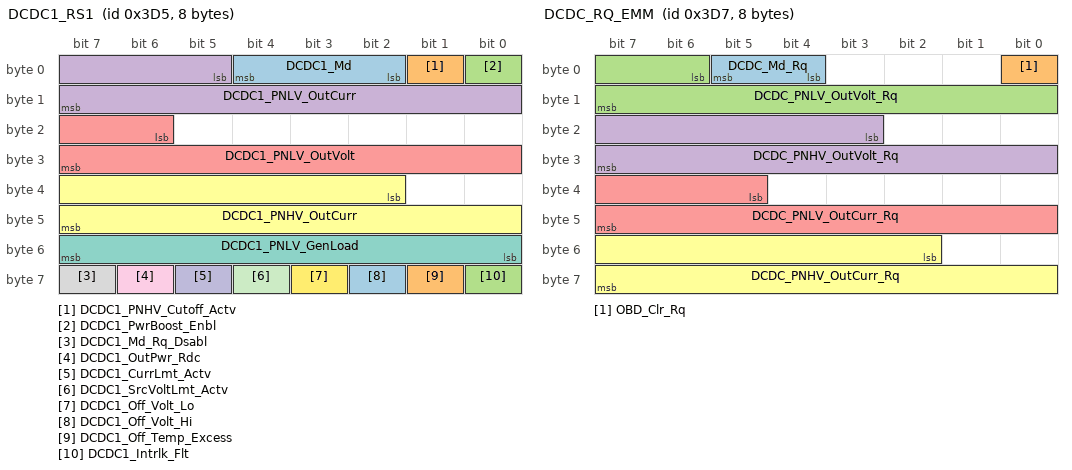
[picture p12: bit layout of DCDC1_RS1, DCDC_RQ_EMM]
BO_ 981 DCDC1_RS1: 8 ESP_ABR
 SG_ DCDC1_Md : 2|3@1+ (1,0) [0|7] "" Vector__XXX

CM_ SG_ 981 DCDC1_Md "DCDC1_Md [source enum/value-table reference]";
 SG_ DCDC1_PNHV_Cutoff_Actv : 1|1@1+ (1,0) [0|1] "" Vector__XXX

CM_ SG_ 981 DCDC1_PNHV_Cutoff_Actv "DCDC1_PNHV_Cutoff_Actv [source boolean]";
 SG_ DCDC1_PwrBoost_Enbl : 0|1@1+ (1,0) [0|1] "" Vector__XXX

CM_ SG_ 981 DCDC1_PwrBoost_Enbl "DCDC1_PwrBoost_Enbl [source boolean]";
 SG_ DCDC1_PNLV_OutCurr : 5|11@1+ (1,-1024) [-1024|1023] "A" Vector__XXX

CM_ SG_ 981 DCDC1_PNLV_OutCurr "DCDC1_PNLV_OutCurr";
 SG_ DCDC1_PNLV_OutVolt : 22|10@1+ (0.10000000149,0) [0|102.300001524] "V" Vector__XXX

CM_ SG_ 981 DCDC1_PNLV_OutVolt "DCDC1_PNLV_OutVolt";
 SG_ DCDC1_PNHV_OutCurr : 34|14@1+ (0.10000000149,-819.200012207) [-819.200012207|819.100012206] "A" Vector__XXX

CM_ SG_ 981 DCDC1_PNHV_OutCurr "DCDC1_PNHV_OutCurr";
 SG_ DCDC1_PNLV_GenLoad : 48|8@1+ (1,0) [0|255] "%" Vector__XXX

CM_ SG_ 981 DCDC1_PNLV_GenLoad "DCDC1_PNLV_GenLoad";
 SG_ DCDC1_Md_Rq_Dsabl : 63|1@1+ (1,0) [0|1] "" Vector__XXX

CM_ SG_ 981 DCDC1_Md_Rq_Dsabl "DCDC1_Md_Rq_Dsabl [source boolean]";
 SG_ DCDC1_OutPwr_Rdc : 62|1@1+ (1,0) [0|1] "" Vector__XXX

CM_ SG_ 981 DCDC1_OutPwr_Rdc "DCDC1_OutPwr_Rdc [source boolean]";
 SG_ DCDC1_CurrLmt_Actv : 61|1@1+ (1,0) [0|1] "" Vector__XXX

CM_ SG_ 981 DCDC1_CurrLmt_Actv "DCDC1_CurrLmt_Actv [source boolean]";
 SG_ DCDC1_SrcVoltLmt_Actv : 60|1@1+ (1,0) [0|1] "" Vector__XXX

CM_ SG_ 981 DCDC1_SrcVoltLmt_Actv "DCDC1_SrcVoltLmt_Actv [source boolean]";
 SG_ DCDC1_Off_Volt_Lo : 59|1@1+ (1,0) [0|1] "" Vector__XXX

CM_ SG_ 981 DCDC1_Off_Volt_Lo "DCDC1_Off_Volt_Lo [source boolean]";
 SG_ DCDC1_Off_Volt_Hi : 58|1@1+ (1,0) [0|1] "" Vector__XXX

CM_ SG_ 981 DCDC1_Off_Volt_Hi "DCDC1_Off_Volt_Hi [source boolean]";
 SG_ DCDC1_Off_Temp_Excess : 57|1@1+ (1,0) [0|1] "" Vector__XXX

CM_ SG_ 981 DCDC1_Off_Temp_Excess "DCDC1_Off_Temp_Excess [source boolean]";
 SG_ DCDC1_Intrlk_Flt : 56|1@1+ (1,0) [0|1] "" Vector__XXX

CM_ SG_ 981 DCDC1_Intrlk_Flt "DCDC1_Intrlk_Flt [source boolean]";

BA_ "GenMsgCycleTime" BO_ 981 15;

BO_ 983 DCDC_RQ_EMM: 8 ESP_ABR
 SG_ DCDC_Md_Rq : 4|2@1+ (1,0) [0|3] "" Vector__XXX

CM_ SG_ 983 DCDC_Md_Rq "DCDC_Md_Rq [source enum/value-table reference]";
 SG_ OBD_Clr_Rq : 0|1@1+ (1,0) [0|1] "" Vector__XXX

CM_ SG_ 983 OBD_Clr_Rq "OBD_Clr_Rq [source boolean]";
 SG_ DCDC_PNLV_OutVolt_Rq : 6|10@1+ (0.10000000149,0) [0|102.300001524] "V" Vector__XXX

CM_ SG_ 983 DCDC_PNLV_OutVolt_Rq "DCDC_PNLV_OutVolt_Rq";
 SG_ DCDC_PNHV_OutVolt_Rq : 19|13@1+ (0.10000000149,0) [0|819.100012206] "V" Vector__XXX

CM_ SG_ 983 DCDC_PNHV_OutVolt_Rq "DCDC_PNHV_OutVolt_Rq";
 SG_ DCDC_PNLV_OutCurr_Rq : 37|11@1+ (1,-1024) [-1024|1023] "A" Vector__XXX

CM_ SG_ 983 DCDC_PNLV_OutCurr_Rq "DCDC_PNLV_OutCurr_Rq";
 SG_ DCDC_PNHV_OutCurr_Rq : 50|14@1+ (0.10000000149,-819.200012207) [-819.200012207|819.100012206] "A" Vector__XXX

CM_ SG_ 983 DCDC_PNHV_OutCurr_Rq "DCDC_PNHV_OutCurr_Rq";

BA_ "GenMsgCycleTime" BO_ 983 6;

BO_ 985 IC_A4: 7 ESP_ABR
 SG_ KeyId_IC : 0|32@1+ (1,0) [0|4294967295] "" Vector__XXX

CM_ SG_ 985 KeyId_IC "KeyId_IC";
 SG_ Odo_IC : 32|24@1+ (0.10000000149,0) [0|1677721.525] "km" Vector__XXX

CM_ SG_ 985 Odo_IC "Odo_IC";

BA_ "GenMsgCycleTime" BO_ 985 2;

BO_ 991 TP_IC_RDU7: 8 ESP_ABR
 SG_ TP_IC_RDU : 0|64@1+ (1,0) [0|9.22337203685e+18] "" Vector__XXX

CM_ SG_ 991 TP_IC_RDU "TP_IC_RDU [source string/raw data]";

BA_ "GenMsgCycleTime" BO_ 991 1;

BO_ 993 IC_A3: 8 ESP_ABR
 SG_ FTW_On_Rq : 6|2@1+ (1,0) [0|3] "" Vector__XXX

CM_ SG_ 993 FTW_On_Rq "FTW_On_Rq [source enum/value-table reference]";
 SG_ TPM_Actv_Rq_V2 : 4|2@1+ (1,0) [0|3] "" Vector__XXX

CM_ SG_ 993 TPM_Actv_Rq_V2 "TPM_Actv_Rq_V2 [source enum/value-table reference]";
 SG_ DRLt_On_Rq : 2|2@1+ (1,0) [0|3] "" Vector__XXX

CM_ SG_ 993 DRLt_On_Rq "DRLt_On_Rq [source enum/value-table reference]";
 SG_ RadarSensMd_Rq : 0|2@1+ (1,0) [0|3] "" Vector__XXX

CM_ SG_ 993 RadarSensMd_Rq "RadarSensMd_Rq [source enum/value-table reference]";
 SG_ DataRadioMenu_Stat : 14|2@1+ (1,0) [0|3] "" Vector__XXX

CM_ SG_ 993 DataRadioMenu_Stat "DataRadioMenu_Stat [source enum/value-table reference]";
 SG_ TaxiMd_Rq : 12|2@1+ (1,0) [0|3] "" Vector__XXX

CM_ SG_ 993 TaxiMd_Rq "TaxiMd_Rq [source enum/value-table reference]";
 SG_ TaxiRoofLmpMd_Rq : 10|2@1+ (1,0) [0|3] "" Vector__XXX

CM_ SG_ 993 TaxiRoofLmpMd_Rq "TaxiRoofLmpMd_Rq [source enum/value-table reference]";
 SG_ TaxiToneMd_Rq : 8|2@1+ (1,0) [0|3] "" Vector__XXX

CM_ SG_ 993 TaxiToneMd_Rq "TaxiToneMd_Rq [source enum/value-table reference]";
 SG_ TAX_Rq : 22|2@1+ (1,0) [0|3] "" Vector__XXX

CM_ SG_ 993 TAX_Rq "TAX_Rq [source enum/value-table reference]";
 SG_ DRVM_SysMd_Rq : 20|2@1+ (1,0) [0|3] "" Vector__XXX

CM_ SG_ 993 DRVM_SysMd_Rq "DRVM_SysMd_Rq [source enum/value-table reference]";
 SG_ DRVM_AudioMd_Rq : 18|2@1+ (1,0) [0|3] "" Vector__XXX

CM_ SG_ 993 DRVM_AudioMd_Rq "DRVM_AudioMd_Rq [source enum/value-table reference]";
 SG_ UnitTemp_Rq : 16|2@1+ (1,0) [0|3] "" Vector__XXX

CM_ SG_ 993 UnitTemp_Rq "UnitTemp_Rq [source enum/value-table reference]";
 SG_ UnitPress_Rq : 30|2@1+ (1,0) [0|3] "" Vector__XXX

CM_ SG_ 993 UnitPress_Rq "UnitPress_Rq [source enum/value-table reference]";
 SG_ AFS_Md_Rq : 28|2@1+ (1,0) [0|3] "" Vector__XXX

CM_ SG_ 993 AFS_Md_Rq "AFS_Md_Rq [source enum/value-table reference]";
 SG_ SSA_ECO_Md_Rq : 26|2@1+ (1,0) [0|3] "" Vector__XXX

CM_ SG_ 993 SSA_ECO_Md_Rq "SSA_ECO_Md_Rq [source enum/value-table reference]";
 SG_ IHC_Md_Rq : 24|2@1+ (1,0) [0|3] "" Vector__XXX

CM_ SG_ 993 IHC_Md_Rq "IHC_Md_Rq [source enum/value-table reference]";
 SG_ ALDW_Md_Rq : 37|3@1+ (1,0) [0|7] "" Vector__XXX

CM_ SG_ 993 ALDW_Md_Rq "ALDW_Md_Rq [source enum/value-table reference]";
 SG_ SLA_Md_Rq : 35|2@1+ (1,0) [0|3] "" Vector__XXX

CM_ SG_ 993 SLA_Md_Rq "SLA_Md_Rq [source enum/value-table reference]";
 SG_ BltSlckDec_Md_Rq : 32|2@1+ (1,0) [0|3] "" Vector__XXX

CM_ SG_ 993 BltSlckDec_Md_Rq "BltSlckDec_Md_Rq [source enum/value-table reference]";
 SG_ PTS_AcustWarn_Enbl : 46|2@1+ (1,0) [0|3] "" Vector__XXX

CM_ SG_ 993 PTS_AcustWarn_Enbl "PTS_AcustWarn_Enbl [source enum/value-table reference]";
 SG_ PTS_Md_Rq : 44|2@1+ (1,0) [0|3] "" Vector__XXX

CM_ SG_ 993 PTS_Md_Rq "PTS_Md_Rq [source enum/value-table reference]";
 SG_ BSM_Md_Rq : 40|2@1+ (1,0) [0|3] "" Vector__XXX

CM_ SG_ 993 BSM_Md_Rq "BSM_Md_Rq [source enum/value-table reference]";
 SG_ ILS_TouristMd_Rq : 58|2@1+ (1,0) [0|3] "" Vector__XXX

CM_ SG_ 993 ILS_TouristMd_Rq "ILS_TouristMd_Rq [source enum/value-table reference]";
 SG_ CLkS_Akust_Lk_Rq_Enbl : 56|2@1+ (1,0) [0|3] "" Vector__XXX

CM_ SG_ 993 CLkS_Akust_Lk_Rq_Enbl "CLkS_Akust_Lk_Rq_Enbl [source enum/value-table reference]";

BA_ "GenMsgCycleTime" BO_ 993 24;

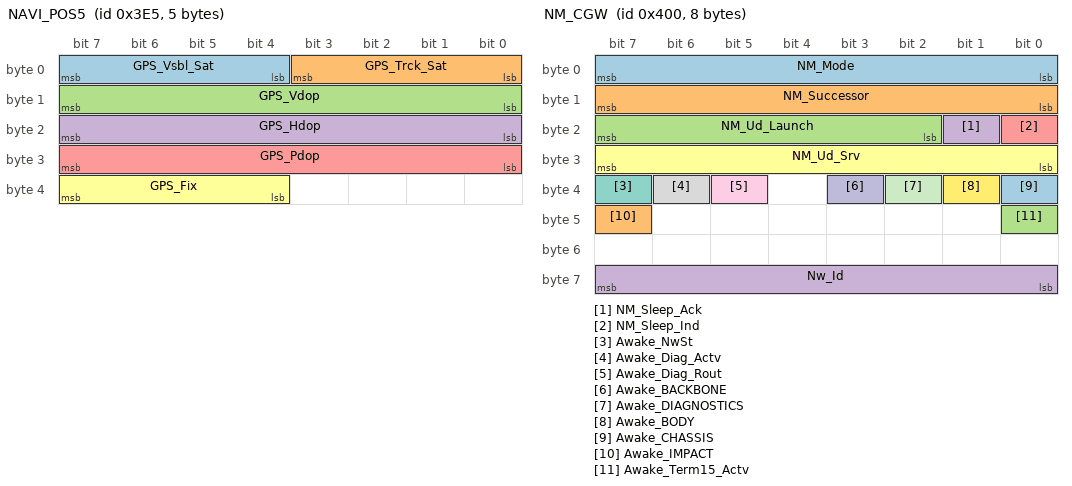
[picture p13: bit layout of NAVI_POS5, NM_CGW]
BO_ 997 NAVI_POS5: 5 ESP_ABR
 SG_ GPS_Vsbl_Sat : 4|4@1+ (1,0) [0|15] "" Vector__XXX

CM_ SG_ 997 GPS_Vsbl_Sat "GPS_Vsbl_Sat";
 SG_ GPS_Trck_Sat : 0|4@1+ (1,0) [0|15] "" Vector__XXX

CM_ SG_ 997 GPS_Trck_Sat "GPS_Trck_Sat";
 SG_ GPS_Vdop : 8|8@1+ (0.10000000149,0) [0|25.50000038] "" Vector__XXX

CM_ SG_ 997 GPS_Vdop "GPS_Vdop";
 SG_ GPS_Hdop : 16|8@1+ (0.10000000149,0) [0|25.50000038] "" Vector__XXX

CM_ SG_ 997 GPS_Hdop "GPS_Hdop";
 SG_ GPS_Pdop : 24|8@1+ (0.10000000149,0) [0|25.50000038] "" Vector__XXX

CM_ SG_ 997 GPS_Pdop "GPS_Pdop";
 SG_ GPS_Fix : 36|4@1+ (1,0) [0|15] "" Vector__XXX

CM_ SG_ 997 GPS_Fix "GPS_Fix [source enum/value-table reference]";

BA_ "GenMsgCycleTime" BO_ 997 6;

BO_ 999 NAVI_POS4: 8 ESP_ABR
 SG_ DR_MM_Lat : 0|32@1+ (0.301748514175,-324000000) [-324000000|971999999.698] "mas" Vector__XXX

CM_ SG_ 999 DR_MM_Lat "DR_MM_Lat";
 SG_ DR_MM_Long : 32|32@1+ (0.301748514175,-648000000) [-648000000|647999999.698] "mas" Vector__XXX

CM_ SG_ 999 DR_MM_Long "DR_MM_Long";

BA_ "GenMsgCycleTime" BO_ 999 2;

BO_ 1009 TP_IC_TELEAID5: 8 ESP_ABR
 SG_ TP_IC_TELEAID : 0|64@1+ (1,0) [0|9.22337203685e+18] "" Vector__XXX

CM_ SG_ 1009 TP_IC_TELEAID "TP_IC_TELEAID [source string/raw data]";

BA_ "GenMsgCycleTime" BO_ 1009 1;

BO_ 1024 NM_CGW: 8 ESP_ABR
 SG_ NM_Mode : 0|8@1+ (1,0) [0|255] "" Vector__XXX

CM_ SG_ 1024 NM_Mode "NM_Mode [source enum/value-table reference]";
 SG_ NM_Successor : 8|8@1+ (1,0) [0|255] "" Vector__XXX

CM_ SG_ 1024 NM_Successor "NM_Successor";
 SG_ NM_Ud_Launch : 18|6@1+ (1,0) [0|63] "" Vector__XXX

CM_ SG_ 1024 NM_Ud_Launch "NM_Ud_Launch [source enum/value-table reference]";
 SG_ NM_Sleep_Ack : 17|1@1+ (1,0) [0|1] "" Vector__XXX

CM_ SG_ 1024 NM_Sleep_Ack "NM_Sleep_Ack [source boolean]";
 SG_ NM_Sleep_Ind : 16|1@1+ (1,0) [0|1] "" Vector__XXX

CM_ SG_ 1024 NM_Sleep_Ind "NM_Sleep_Ind [source boolean]";
 SG_ NM_Ud_Srv : 24|8@1+ (1,0) [0|255] "" Vector__XXX

CM_ SG_ 1024 NM_Ud_Srv "NM_Ud_Srv [source enum/value-table reference]";
 SG_ Awake_NwSt : 39|1@1+ (1,0) [0|1] "" Vector__XXX

CM_ SG_ 1024 Awake_NwSt "Awake_NwSt [source boolean]";
 SG_ Awake_Diag_Actv : 38|1@1+ (1,0) [0|1] "" Vector__XXX

CM_ SG_ 1024 Awake_Diag_Actv "Awake_Diag_Actv [source boolean]";
 SG_ Awake_Diag_Rout : 37|1@1+ (1,0) [0|1] "" Vector__XXX

CM_ SG_ 1024 Awake_Diag_Rout "Awake_Diag_Rout [source boolean]";
 SG_ Awake_BACKBONE : 35|1@1+ (1,0) [0|1] "" Vector__XXX

CM_ SG_ 1024 Awake_BACKBONE "Awake_BACKBONE [source boolean]";
 SG_ Awake_DIAGNOSTICS : 34|1@1+ (1,0) [0|1] "" Vector__XXX

CM_ SG_ 1024 Awake_DIAGNOSTICS "Awake_DIAGNOSTICS [source boolean]";
 SG_ Awake_BODY : 33|1@1+ (1,0) [0|1] "" Vector__XXX

CM_ SG_ 1024 Awake_BODY "Awake_BODY [source boolean]";
 SG_ Awake_CHASSIS : 32|1@1+ (1,0) [0|1] "" Vector__XXX

CM_ SG_ 1024 Awake_CHASSIS "Awake_CHASSIS [source boolean]";
 SG_ Awake_IMPACT : 47|1@1+ (1,0) [0|1] "" Vector__XXX

CM_ SG_ 1024 Awake_IMPACT "Awake_IMPACT [source boolean]";
 SG_ Awake_Term15_Actv : 40|1@1+ (1,0) [0|1] "" Vector__XXX

CM_ SG_ 1024 Awake_Term15_Actv "Awake_Term15_Actv [source boolean]";
 SG_ Nw_Id : 56|8@1+ (1,0) [0|255] "" Vector__XXX

CM_ SG_ 1024 Nw_Id "Nw_Id [source enum/value-table reference]";

BA_ "GenMsgCycleTime" BO_ 1024 16;

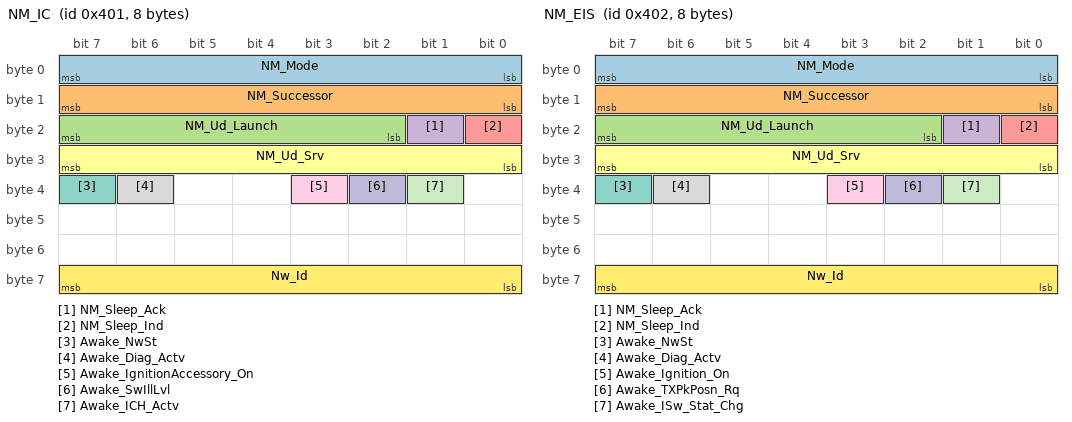
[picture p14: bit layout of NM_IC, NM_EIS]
BO_ 1025 NM_IC: 8 ESP_ABR
 SG_ NM_Mode : 0|8@1+ (1,0) [0|255] "" Vector__XXX

CM_ SG_ 1025 NM_Mode "NM_Mode [source enum/value-table reference]";
 SG_ NM_Successor : 8|8@1+ (1,0) [0|255] "" Vector__XXX

CM_ SG_ 1025 NM_Successor "NM_Successor";
 SG_ NM_Ud_Launch : 18|6@1+ (1,0) [0|63] "" Vector__XXX

CM_ SG_ 1025 NM_Ud_Launch "NM_Ud_Launch [source enum/value-table reference]";
 SG_ NM_Sleep_Ack : 17|1@1+ (1,0) [0|1] "" Vector__XXX

CM_ SG_ 1025 NM_Sleep_Ack "NM_Sleep_Ack [source boolean]";
 SG_ NM_Sleep_Ind : 16|1@1+ (1,0) [0|1] "" Vector__XXX

CM_ SG_ 1025 NM_Sleep_Ind "NM_Sleep_Ind [source boolean]";
 SG_ NM_Ud_Srv : 24|8@1+ (1,0) [0|255] "" Vector__XXX

CM_ SG_ 1025 NM_Ud_Srv "NM_Ud_Srv [source enum/value-table reference]";
 SG_ Awake_NwSt : 39|1@1+ (1,0) [0|1] "" Vector__XXX

CM_ SG_ 1025 Awake_NwSt "Awake_NwSt [source boolean]";
 SG_ Awake_Diag_Actv : 38|1@1+ (1,0) [0|1] "" Vector__XXX

CM_ SG_ 1025 Awake_Diag_Actv "Awake_Diag_Actv [source boolean]";
 SG_ Awake_IgnitionAccessory_On : 35|1@1+ (1,0) [0|1] "" Vector__XXX

CM_ SG_ 1025 Awake_IgnitionAccessory_On "Awake_IgnitionAccessory_On [source boolean]";
 SG_ Awake_SwIllLvl : 34|1@1+ (1,0) [0|1] "" Vector__XXX

CM_ SG_ 1025 Awake_SwIllLvl "Awake_SwIllLvl [source boolean]";
 SG_ Awake_ICH_Actv : 33|1@1+ (1,0) [0|1] "" Vector__XXX

CM_ SG_ 1025 Awake_ICH_Actv "Awake_ICH_Actv [source boolean]";
 SG_ Nw_Id : 56|8@1+ (1,0) [0|255] "" Vector__XXX

CM_ SG_ 1025 Nw_Id "Nw_Id [source enum/value-table reference]";

BA_ "GenMsgCycleTime" BO_ 1025 12;

BO_ 1026 NM_EIS: 8 ESP_ABR
 SG_ NM_Mode : 0|8@1+ (1,0) [0|255] "" Vector__XXX

CM_ SG_ 1026 NM_Mode "NM_Mode [source enum/value-table reference]";
 SG_ NM_Successor : 8|8@1+ (1,0) [0|255] "" Vector__XXX

CM_ SG_ 1026 NM_Successor "NM_Successor";
 SG_ NM_Ud_Launch : 18|6@1+ (1,0) [0|63] "" Vector__XXX

CM_ SG_ 1026 NM_Ud_Launch "NM_Ud_Launch [source enum/value-table reference]";
 SG_ NM_Sleep_Ack : 17|1@1+ (1,0) [0|1] "" Vector__XXX

CM_ SG_ 1026 NM_Sleep_Ack "NM_Sleep_Ack [source boolean]";
 SG_ NM_Sleep_Ind : 16|1@1+ (1,0) [0|1] "" Vector__XXX

CM_ SG_ 1026 NM_Sleep_Ind "NM_Sleep_Ind [source boolean]";
 SG_ NM_Ud_Srv : 24|8@1+ (1,0) [0|255] "" Vector__XXX

CM_ SG_ 1026 NM_Ud_Srv "NM_Ud_Srv [source enum/value-table reference]";
 SG_ Awake_NwSt : 39|1@1+ (1,0) [0|1] "" Vector__XXX

CM_ SG_ 1026 Awake_NwSt "Awake_NwSt [source boolean]";
 SG_ Awake_Diag_Actv : 38|1@1+ (1,0) [0|1] "" Vector__XXX

CM_ SG_ 1026 Awake_Diag_Actv "Awake_Diag_Actv [source boolean]";
 SG_ Awake_Ignition_On : 35|1@1+ (1,0) [0|1] "" Vector__XXX

CM_ SG_ 1026 Awake_Ignition_On "Awake_Ignition_On [source boolean]";
 SG_ Awake_TXPkPosn_Rq : 34|1@1+ (1,0) [0|1] "" Vector__XXX

CM_ SG_ 1026 Awake_TXPkPosn_Rq "Awake_TXPkPosn_Rq [source boolean]";
 SG_ Awake_ISw_Stat_Chg : 33|1@1+ (1,0) [0|1] "" Vector__XXX

CM_ SG_ 1026 Awake_ISw_Stat_Chg "Awake_ISw_Stat_Chg [source boolean]";
 SG_ Nw_Id : 56|8@1+ (1,0) [0|255] "" Vector__XXX

CM_ SG_ 1026 Nw_Id "Nw_Id [source enum/value-table reference]";

BA_ "GenMsgCycleTime" BO_ 1026 12;

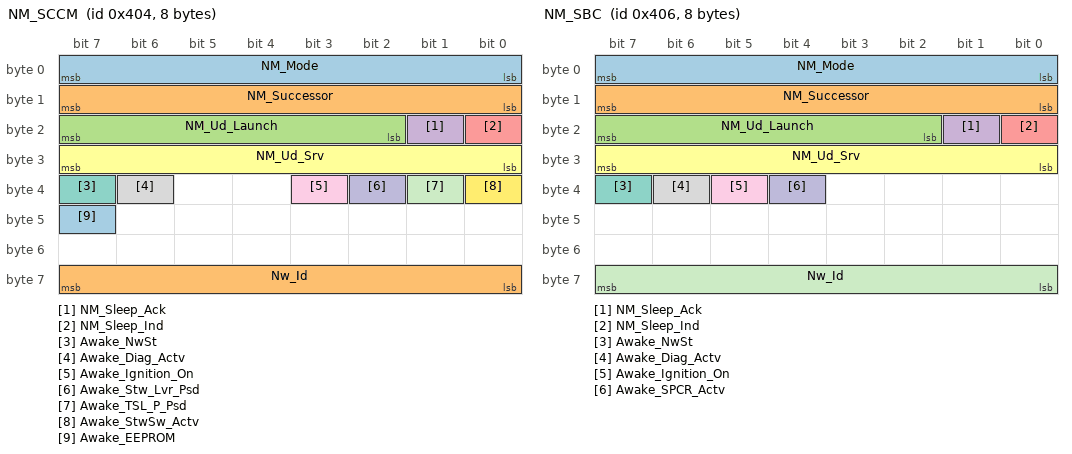
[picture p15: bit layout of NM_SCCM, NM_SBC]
BO_ 1028 NM_SCCM: 8 ESP_ABR
 SG_ NM_Mode : 0|8@1+ (1,0) [0|255] "" Vector__XXX

CM_ SG_ 1028 NM_Mode "NM_Mode [source enum/value-table reference]";
 SG_ NM_Successor : 8|8@1+ (1,0) [0|255] "" Vector__XXX

CM_ SG_ 1028 NM_Successor "NM_Successor";
 SG_ NM_Ud_Launch : 18|6@1+ (1,0) [0|63] "" Vector__XXX

CM_ SG_ 1028 NM_Ud_Launch "NM_Ud_Launch [source enum/value-table reference]";
 SG_ NM_Sleep_Ack : 17|1@1+ (1,0) [0|1] "" Vector__XXX

CM_ SG_ 1028 NM_Sleep_Ack "NM_Sleep_Ack [source boolean]";
 SG_ NM_Sleep_Ind : 16|1@1+ (1,0) [0|1] "" Vector__XXX

CM_ SG_ 1028 NM_Sleep_Ind "NM_Sleep_Ind [source boolean]";
 SG_ NM_Ud_Srv : 24|8@1+ (1,0) [0|255] "" Vector__XXX

CM_ SG_ 1028 NM_Ud_Srv "NM_Ud_Srv [source enum/value-table reference]";
 SG_ Awake_NwSt : 39|1@1+ (1,0) [0|1] "" Vector__XXX

CM_ SG_ 1028 Awake_NwSt "Awake_NwSt [source boolean]";
 SG_ Awake_Diag_Actv : 38|1@1+ (1,0) [0|1] "" Vector__XXX

CM_ SG_ 1028 Awake_Diag_Actv "Awake_Diag_Actv [source boolean]";
 SG_ Awake_Ignition_On : 35|1@1+ (1,0) [0|1] "" Vector__XXX

CM_ SG_ 1028 Awake_Ignition_On "Awake_Ignition_On [source boolean]";
 SG_ Awake_Stw_Lvr_Psd : 34|1@1+ (1,0) [0|1] "" Vector__XXX

CM_ SG_ 1028 Awake_Stw_Lvr_Psd "Awake_Stw_Lvr_Psd [source boolean]";
 SG_ Awake_TSL_P_Psd : 33|1@1+ (1,0) [0|1] "" Vector__XXX

CM_ SG_ 1028 Awake_TSL_P_Psd "Awake_TSL_P_Psd [source boolean]";
 SG_ Awake_StwSw_Actv : 32|1@1+ (1,0) [0|1] "" Vector__XXX

CM_ SG_ 1028 Awake_StwSw_Actv "Awake_StwSw_Actv [source boolean]";
 SG_ Awake_EEPROM : 47|1@1+ (1,0) [0|1] "" Vector__XXX

CM_ SG_ 1028 Awake_EEPROM "Awake_EEPROM [source boolean]";
 SG_ Nw_Id : 56|8@1+ (1,0) [0|255] "" Vector__XXX

CM_ SG_ 1028 Nw_Id "Nw_Id [source enum/value-table reference]";

BA_ "GenMsgCycleTime" BO_ 1028 14;

BO_ 1030 NM_SBC: 8 ESP_ABR
 SG_ NM_Mode : 0|8@1+ (1,0) [0|255] "" Vector__XXX

CM_ SG_ 1030 NM_Mode "NM_Mode [source enum/value-table reference]";
 SG_ NM_Successor : 8|8@1+ (1,0) [0|255] "" Vector__XXX

CM_ SG_ 1030 NM_Successor "NM_Successor";
 SG_ NM_Ud_Launch : 18|6@1+ (1,0) [0|63] "" Vector__XXX

CM_ SG_ 1030 NM_Ud_Launch "NM_Ud_Launch [source enum/value-table reference]";
 SG_ NM_Sleep_Ack : 17|1@1+ (1,0) [0|1] "" Vector__XXX

CM_ SG_ 1030 NM_Sleep_Ack "NM_Sleep_Ack [source boolean]";
 SG_ NM_Sleep_Ind : 16|1@1+ (1,0) [0|1] "" Vector__XXX

CM_ SG_ 1030 NM_Sleep_Ind "NM_Sleep_Ind [source boolean]";
 SG_ NM_Ud_Srv : 24|8@1+ (1,0) [0|255] "" Vector__XXX

CM_ SG_ 1030 NM_Ud_Srv "NM_Ud_Srv [source enum/value-table reference]";
 SG_ Awake_NwSt : 39|1@1+ (1,0) [0|1] "" Vector__XXX

CM_ SG_ 1030 Awake_NwSt "Awake_NwSt [source boolean]";
 SG_ Awake_Diag_Actv : 38|1@1+ (1,0) [0|1] "" Vector__XXX

CM_ SG_ 1030 Awake_Diag_Actv "Awake_Diag_Actv [source boolean]";
 SG_ Awake_Ignition_On : 37|1@1+ (1,0) [0|1] "" Vector__XXX

CM_ SG_ 1030 Awake_Ignition_On "Awake_Ignition_On [source boolean]";
 SG_ Awake_SPCR_Actv : 36|1@1+ (1,0) [0|1] "" Vector__XXX

CM_ SG_ 1030 Awake_SPCR_Actv "Awake_SPCR_Actv [source boolean]";
 SG_ Nw_Id : 56|8@1+ (1,0) [0|255] "" Vector__XXX

CM_ SG_ 1030 Nw_Id "Nw_Id [source enum/value-table reference]";

BA_ "GenMsgCycleTime" BO_ 1030 11;

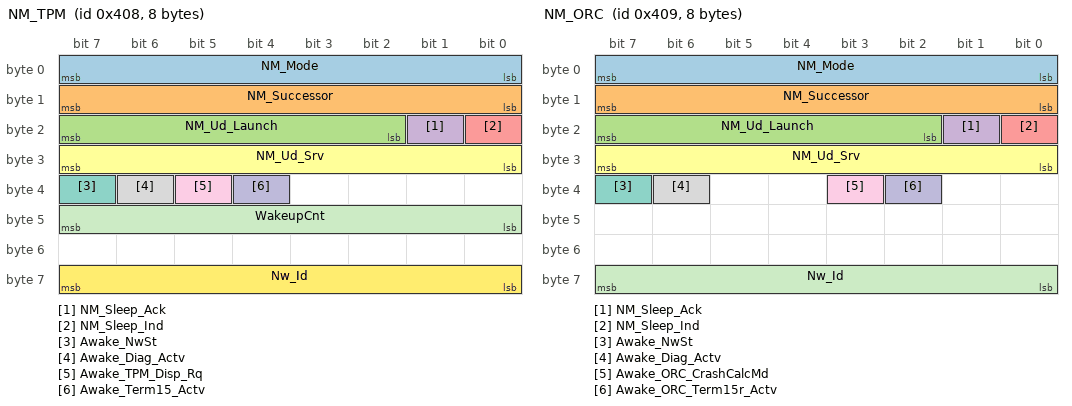
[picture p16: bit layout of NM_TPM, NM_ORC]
BO_ 1032 NM_TPM: 8 ESP_ABR
 SG_ NM_Mode : 0|8@1+ (1,0) [0|255] "" Vector__XXX

CM_ SG_ 1032 NM_Mode "NM_Mode [source enum/value-table reference]";
 SG_ NM_Successor : 8|8@1+ (1,0) [0|255] "" Vector__XXX

CM_ SG_ 1032 NM_Successor "NM_Successor";
 SG_ NM_Ud_Launch : 18|6@1+ (1,0) [0|63] "" Vector__XXX

CM_ SG_ 1032 NM_Ud_Launch "NM_Ud_Launch [source enum/value-table reference]";
 SG_ NM_Sleep_Ack : 17|1@1+ (1,0) [0|1] "" Vector__XXX

CM_ SG_ 1032 NM_Sleep_Ack "NM_Sleep_Ack [source boolean]";
 SG_ NM_Sleep_Ind : 16|1@1+ (1,0) [0|1] "" Vector__XXX

CM_ SG_ 1032 NM_Sleep_Ind "NM_Sleep_Ind [source boolean]";
 SG_ NM_Ud_Srv : 24|8@1+ (1,0) [0|255] "" Vector__XXX

CM_ SG_ 1032 NM_Ud_Srv "NM_Ud_Srv [source enum/value-table reference]";
 SG_ Awake_NwSt : 39|1@1+ (1,0) [0|1] "" Vector__XXX

CM_ SG_ 1032 Awake_NwSt "Awake_NwSt [source boolean]";
 SG_ Awake_Diag_Actv : 38|1@1+ (1,0) [0|1] "" Vector__XXX

CM_ SG_ 1032 Awake_Diag_Actv "Awake_Diag_Actv [source boolean]";
 SG_ Awake_TPM_Disp_Rq : 37|1@1+ (1,0) [0|1] "" Vector__XXX

CM_ SG_ 1032 Awake_TPM_Disp_Rq "Awake_TPM_Disp_Rq [source boolean]";
 SG_ Awake_Term15_Actv : 36|1@1+ (1,0) [0|1] "" Vector__XXX

CM_ SG_ 1032 Awake_Term15_Actv "Awake_Term15_Actv [source boolean]";
 SG_ WakeupCnt : 40|8@1+ (1,0) [0|255] "" Vector__XXX

CM_ SG_ 1032 WakeupCnt "WakeupCnt";
 SG_ Nw_Id : 56|8@1+ (1,0) [0|255] "" Vector__XXX

CM_ SG_ 1032 Nw_Id "Nw_Id [source enum/value-table reference]";

BA_ "GenMsgCycleTime" BO_ 1032 12;

BO_ 1033 NM_ORC: 8 ESP_ABR
 SG_ NM_Mode : 0|8@1+ (1,0) [0|255] "" Vector__XXX

CM_ SG_ 1033 NM_Mode "NM_Mode [source enum/value-table reference]";
 SG_ NM_Successor : 8|8@1+ (1,0) [0|255] "" Vector__XXX

CM_ SG_ 1033 NM_Successor "NM_Successor";
 SG_ NM_Ud_Launch : 18|6@1+ (1,0) [0|63] "" Vector__XXX

CM_ SG_ 1033 NM_Ud_Launch "NM_Ud_Launch [source enum/value-table reference]";
 SG_ NM_Sleep_Ack : 17|1@1+ (1,0) [0|1] "" Vector__XXX

CM_ SG_ 1033 NM_Sleep_Ack "NM_Sleep_Ack [source boolean]";
 SG_ NM_Sleep_Ind : 16|1@1+ (1,0) [0|1] "" Vector__XXX

CM_ SG_ 1033 NM_Sleep_Ind "NM_Sleep_Ind [source boolean]";
 SG_ NM_Ud_Srv : 24|8@1+ (1,0) [0|255] "" Vector__XXX

CM_ SG_ 1033 NM_Ud_Srv "NM_Ud_Srv [source enum/value-table reference]";
 SG_ Awake_NwSt : 39|1@1+ (1,0) [0|1] "" Vector__XXX

CM_ SG_ 1033 Awake_NwSt "Awake_NwSt [source boolean]";
 SG_ Awake_Diag_Actv : 38|1@1+ (1,0) [0|1] "" Vector__XXX

CM_ SG_ 1033 Awake_Diag_Actv "Awake_Diag_Actv [source boolean]";
 SG_ Awake_ORC_CrashCalcMd : 35|1@1+ (1,0) [0|1] "" Vector__XXX

CM_ SG_ 1033 Awake_ORC_CrashCalcMd "Awake_ORC_CrashCalcMd [source boolean]";
 SG_ Awake_ORC_Term15r_Actv : 34|1@1+ (1,0) [0|1] "" Vector__XXX

CM_ SG_ 1033 Awake_ORC_Term15r_Actv "Awake_ORC_Term15r_Actv [source boolean]";
 SG_ Nw_Id : 56|8@1+ (1,0) [0|255] "" Vector__XXX

CM_ SG_ 1033 Nw_Id "Nw_Id [source enum/value-table reference]";

BA_ "GenMsgCycleTime" BO_ 1033 11;

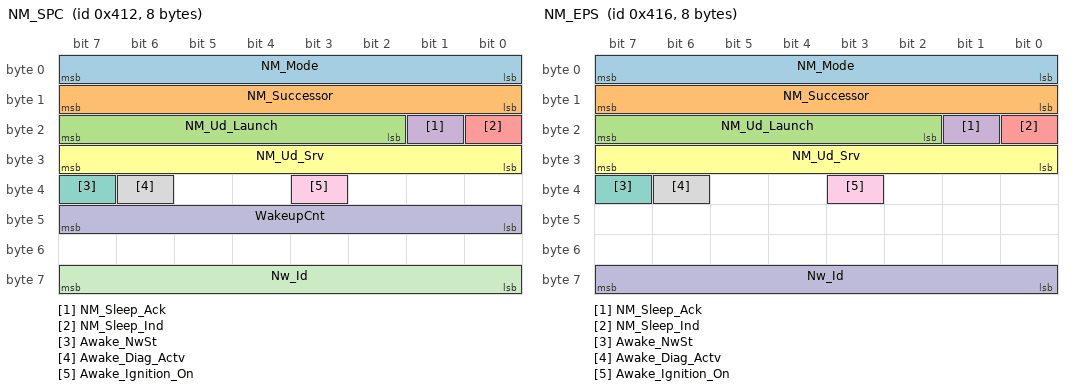
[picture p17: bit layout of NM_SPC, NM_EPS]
BO_ 1042 NM_SPC: 8 ESP_ABR
 SG_ NM_Mode : 0|8@1+ (1,0) [0|255] "" Vector__XXX

CM_ SG_ 1042 NM_Mode "NM_Mode [source enum/value-table reference]";
 SG_ NM_Successor : 8|8@1+ (1,0) [0|255] "" Vector__XXX

CM_ SG_ 1042 NM_Successor "NM_Successor";
 SG_ NM_Ud_Launch : 18|6@1+ (1,0) [0|63] "" Vector__XXX

CM_ SG_ 1042 NM_Ud_Launch "NM_Ud_Launch [source enum/value-table reference]";
 SG_ NM_Sleep_Ack : 17|1@1+ (1,0) [0|1] "" Vector__XXX

CM_ SG_ 1042 NM_Sleep_Ack "NM_Sleep_Ack [source boolean]";
 SG_ NM_Sleep_Ind : 16|1@1+ (1,0) [0|1] "" Vector__XXX

CM_ SG_ 1042 NM_Sleep_Ind "NM_Sleep_Ind [source boolean]";
 SG_ NM_Ud_Srv : 24|8@1+ (1,0) [0|255] "" Vector__XXX

CM_ SG_ 1042 NM_Ud_Srv "NM_Ud_Srv [source enum/value-table reference]";
 SG_ Awake_NwSt : 39|1@1+ (1,0) [0|1] "" Vector__XXX

CM_ SG_ 1042 Awake_NwSt "Awake_NwSt [source boolean]";
 SG_ Awake_Diag_Actv : 38|1@1+ (1,0) [0|1] "" Vector__XXX

CM_ SG_ 1042 Awake_Diag_Actv "Awake_Diag_Actv [source boolean]";
 SG_ Awake_Ignition_On : 35|1@1+ (1,0) [0|1] "" Vector__XXX

CM_ SG_ 1042 Awake_Ignition_On "Awake_Ignition_On [source boolean]";
 SG_ WakeupCnt : 40|8@1+ (1,0) [0|255] "" Vector__XXX

CM_ SG_ 1042 WakeupCnt "WakeupCnt";
 SG_ Nw_Id : 56|8@1+ (1,0) [0|255] "" Vector__XXX

CM_ SG_ 1042 Nw_Id "Nw_Id [source enum/value-table reference]";

BA_ "GenMsgCycleTime" BO_ 1042 11;

BO_ 1046 NM_EPS: 8 ESP_ABR
 SG_ NM_Mode : 0|8@1+ (1,0) [0|255] "" Vector__XXX

CM_ SG_ 1046 NM_Mode "NM_Mode [source enum/value-table reference]";
 SG_ NM_Successor : 8|8@1+ (1,0) [0|255] "" Vector__XXX

CM_ SG_ 1046 NM_Successor "NM_Successor";
 SG_ NM_Ud_Launch : 18|6@1+ (1,0) [0|63] "" Vector__XXX

CM_ SG_ 1046 NM_Ud_Launch "NM_Ud_Launch [source enum/value-table reference]";
 SG_ NM_Sleep_Ack : 17|1@1+ (1,0) [0|1] "" Vector__XXX

CM_ SG_ 1046 NM_Sleep_Ack "NM_Sleep_Ack [source boolean]";
 SG_ NM_Sleep_Ind : 16|1@1+ (1,0) [0|1] "" Vector__XXX

CM_ SG_ 1046 NM_Sleep_Ind "NM_Sleep_Ind [source boolean]";
 SG_ NM_Ud_Srv : 24|8@1+ (1,0) [0|255] "" Vector__XXX

CM_ SG_ 1046 NM_Ud_Srv "NM_Ud_Srv [source enum/value-table reference]";
 SG_ Awake_NwSt : 39|1@1+ (1,0) [0|1] "" Vector__XXX

CM_ SG_ 1046 Awake_NwSt "Awake_NwSt [source boolean]";
 SG_ Awake_Diag_Actv : 38|1@1+ (1,0) [0|1] "" Vector__XXX

CM_ SG_ 1046 Awake_Diag_Actv "Awake_Diag_Actv [source boolean]";
 SG_ Awake_Ignition_On : 35|1@1+ (1,0) [0|1] "" Vector__XXX

CM_ SG_ 1046 Awake_Ignition_On "Awake_Ignition_On [source boolean]";
 SG_ Nw_Id : 56|8@1+ (1,0) [0|255] "" Vector__XXX

CM_ SG_ 1046 Nw_Id "Nw_Id [source enum/value-table reference]";

BA_ "GenMsgCycleTime" BO_ 1046 10;

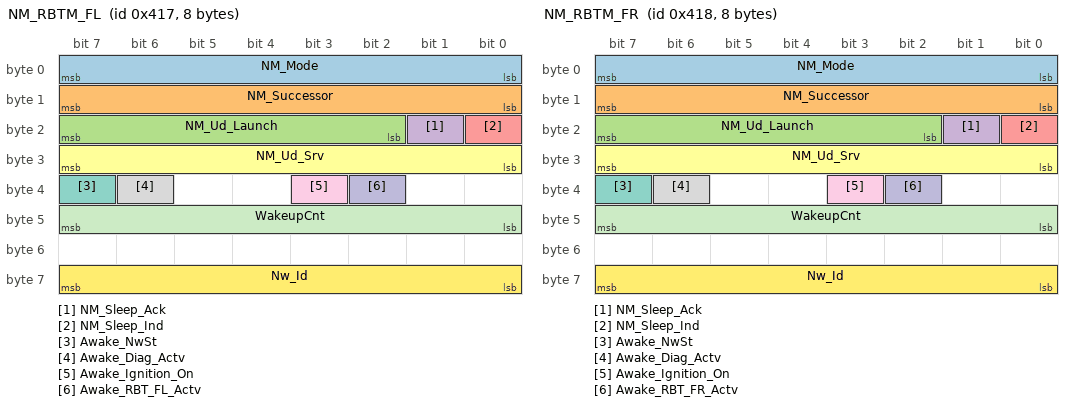
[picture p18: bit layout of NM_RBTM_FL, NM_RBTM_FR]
BO_ 1047 NM_RBTM_FL: 8 ESP_ABR
 SG_ NM_Mode : 0|8@1+ (1,0) [0|255] "" Vector__XXX

CM_ SG_ 1047 NM_Mode "NM_Mode [source enum/value-table reference]";
 SG_ NM_Successor : 8|8@1+ (1,0) [0|255] "" Vector__XXX

CM_ SG_ 1047 NM_Successor "NM_Successor";
 SG_ NM_Ud_Launch : 18|6@1+ (1,0) [0|63] "" Vector__XXX

CM_ SG_ 1047 NM_Ud_Launch "NM_Ud_Launch [source enum/value-table reference]";
 SG_ NM_Sleep_Ack : 17|1@1+ (1,0) [0|1] "" Vector__XXX

CM_ SG_ 1047 NM_Sleep_Ack "NM_Sleep_Ack [source boolean]";
 SG_ NM_Sleep_Ind : 16|1@1+ (1,0) [0|1] "" Vector__XXX

CM_ SG_ 1047 NM_Sleep_Ind "NM_Sleep_Ind [source boolean]";
 SG_ NM_Ud_Srv : 24|8@1+ (1,0) [0|255] "" Vector__XXX

CM_ SG_ 1047 NM_Ud_Srv "NM_Ud_Srv [source enum/value-table reference]";
 SG_ Awake_NwSt : 39|1@1+ (1,0) [0|1] "" Vector__XXX

CM_ SG_ 1047 Awake_NwSt "Awake_NwSt [source boolean]";
 SG_ Awake_Diag_Actv : 38|1@1+ (1,0) [0|1] "" Vector__XXX

CM_ SG_ 1047 Awake_Diag_Actv "Awake_Diag_Actv [source boolean]";
 SG_ Awake_Ignition_On : 35|1@1+ (1,0) [0|1] "" Vector__XXX

CM_ SG_ 1047 Awake_Ignition_On "Awake_Ignition_On [source boolean]";
 SG_ Awake_RBT_FL_Actv : 34|1@1+ (1,0) [0|1] "" Vector__XXX

CM_ SG_ 1047 Awake_RBT_FL_Actv "Awake_RBT_FL_Actv [source boolean]";
 SG_ WakeupCnt : 40|8@1+ (1,0) [0|255] "" Vector__XXX

CM_ SG_ 1047 WakeupCnt "WakeupCnt";
 SG_ Nw_Id : 56|8@1+ (1,0) [0|255] "" Vector__XXX

CM_ SG_ 1047 Nw_Id "Nw_Id [source enum/value-table reference]";

BA_ "GenMsgCycleTime" BO_ 1047 12;

BO_ 1048 NM_RBTM_FR: 8 ESP_ABR
 SG_ NM_Mode : 0|8@1+ (1,0) [0|255] "" Vector__XXX

CM_ SG_ 1048 NM_Mode "NM_Mode [source enum/value-table reference]";
 SG_ NM_Successor : 8|8@1+ (1,0) [0|255] "" Vector__XXX

CM_ SG_ 1048 NM_Successor "NM_Successor";
 SG_ NM_Ud_Launch : 18|6@1+ (1,0) [0|63] "" Vector__XXX

CM_ SG_ 1048 NM_Ud_Launch "NM_Ud_Launch [source enum/value-table reference]";
 SG_ NM_Sleep_Ack : 17|1@1+ (1,0) [0|1] "" Vector__XXX

CM_ SG_ 1048 NM_Sleep_Ack "NM_Sleep_Ack [source boolean]";
 SG_ NM_Sleep_Ind : 16|1@1+ (1,0) [0|1] "" Vector__XXX

CM_ SG_ 1048 NM_Sleep_Ind "NM_Sleep_Ind [source boolean]";
 SG_ NM_Ud_Srv : 24|8@1+ (1,0) [0|255] "" Vector__XXX

CM_ SG_ 1048 NM_Ud_Srv "NM_Ud_Srv [source enum/value-table reference]";
 SG_ Awake_NwSt : 39|1@1+ (1,0) [0|1] "" Vector__XXX

CM_ SG_ 1048 Awake_NwSt "Awake_NwSt [source boolean]";
 SG_ Awake_Diag_Actv : 38|1@1+ (1,0) [0|1] "" Vector__XXX

CM_ SG_ 1048 Awake_Diag_Actv "Awake_Diag_Actv [source boolean]";
 SG_ Awake_Ignition_On : 35|1@1+ (1,0) [0|1] "" Vector__XXX

CM_ SG_ 1048 Awake_Ignition_On "Awake_Ignition_On [source boolean]";
 SG_ Awake_RBT_FR_Actv : 34|1@1+ (1,0) [0|1] "" Vector__XXX

CM_ SG_ 1048 Awake_RBT_FR_Actv "Awake_RBT_FR_Actv [source boolean]";
 SG_ WakeupCnt : 40|8@1+ (1,0) [0|255] "" Vector__XXX

CM_ SG_ 1048 WakeupCnt "WakeupCnt";
 SG_ Nw_Id : 56|8@1+ (1,0) [0|255] "" Vector__XXX

CM_ SG_ 1048 Nw_Id "Nw_Id [source enum/value-table reference]";

BA_ "GenMsgCycleTime" BO_ 1048 12;

BO_ 1065 NM_ECM: 8 ESP_ABR
 SG_ NM_Mode : 0|8@1+ (1,0) [0|255] "" Vector__XXX

CM_ SG_ 1065 NM_Mode "NM_Mode [source enum/value-table reference]";
 SG_ NM_Successor : 8|8@1+ (1,0) [0|255] "" Vector__XXX

CM_ SG_ 1065 NM_Successor "NM_Successor";
 SG_ NM_Ud_Launch : 18|6@1+ (1,0) [0|63] "" Vector__XXX

CM_ SG_ 1065 NM_Ud_Launch "NM_Ud_Launch [source enum/value-table reference]";
 SG_ NM_Sleep_Ack : 17|1@1+ (1,0) [0|1] "" Vector__XXX

CM_ SG_ 1065 NM_Sleep_Ack "NM_Sleep_Ack [source boolean]";
 SG_ NM_Sleep_Ind : 16|1@1+ (1,0) [0|1] "" Vector__XXX

CM_ SG_ 1065 NM_Sleep_Ind "NM_Sleep_Ind [source boolean]";
 SG_ NM_Ud_Srv : 24|8@1+ (1,0) [0|255] "" Vector__XXX

CM_ SG_ 1065 NM_Ud_Srv "NM_Ud_Srv [source enum/value-table reference]";
 SG_ Awake_NwSt : 39|1@1+ (1,0) [0|1] "" Vector__XXX

CM_ SG_ 1065 Awake_NwSt "Awake_NwSt [source boolean]";
 SG_ Awake_Diag_Actv : 38|1@1+ (1,0) [0|1] "" Vector__XXX

CM_ SG_ 1065 Awake_Diag_Actv "Awake_Diag_Actv [source boolean]";
 SG_ Awake_Ignition_On : 35|1@1+ (1,0) [0|1] "" Vector__XXX

CM_ SG_ 1065 Awake_Ignition_On "Awake_Ignition_On [source boolean]";
 SG_ Awake_Afterrun_Actv : 34|1@1+ (1,0) [0|1] "" Vector__XXX

CM_ SG_ 1065 Awake_Afterrun_Actv "Awake_Afterrun_Actv [source boolean]";
 SG_ Awake_EngFan_Actv : 33|1@1+ (1,0) [0|1] "" Vector__XXX

CM_ SG_ 1065 Awake_EngFan_Actv "Awake_EngFan_Actv [source boolean]";
 SG_ Awake_EngRestart : 32|1@1+ (1,0) [0|1] "" Vector__XXX

CM_ SG_ 1065 Awake_EngRestart "Awake_EngRestart [source boolean]";
 SG_ Awake_CHASSIS : 47|1@1+ (1,0) [0|1] "" Vector__XXX

CM_ SG_ 1065 Awake_CHASSIS "Awake_CHASSIS [source boolean]";
 SG_ Awake_POWERTRAIN : 46|1@1+ (1,0) [0|1] "" Vector__XXX

CM_ SG_ 1065 Awake_POWERTRAIN "Awake_POWERTRAIN [source boolean]";
 SG_ Awake_CCP_Actv : 45|1@1+ (1,0) [0|1] "" Vector__XXX

CM_ SG_ 1065 Awake_CCP_Actv "Awake_CCP_Actv [source boolean]";
 SG_ Awake_HYBRID : 44|1@1+ (1,0) [0|1] "" Vector__XXX

CM_ SG_ 1065 Awake_HYBRID "Awake_HYBRID [source boolean]";
 SG_ Nw_Id : 56|8@1+ (1,0) [0|255] "" Vector__XXX

CM_ SG_ 1065 Nw_Id "Nw_Id [source enum/value-table reference]";

BA_ "GenMsgCycleTime" BO_ 1065 17;

BO_ 1088 DG_RQ_GLOBAL: 8 ESP_ABR
 SG_ DG_RQ_GLOBAL : 0|64@1+ (1,0) [0|9.22337203685e+18] "" Vector__XXX

CM_ SG_ 1088 DG_RQ_GLOBAL "DG_RQ_GLOBAL [source string/raw data]";

BA_ "GenMsgCycleTime" BO_ 1088 1;

BO_ 1089 DG_RQ_GLOBAL_UDS: 8 ESP_ABR
 SG_ DG_RQ_GLOBAL_UDS : 0|64@1+ (1,0) [0|9.22337203685e+18] "" Vector__XXX

CM_ SG_ 1089 DG_RQ_GLOBAL_UDS "DG_RQ_GLOBAL_UDS [source string/raw data]";

BA_ "GenMsgCycleTime" BO_ 1089 1;

BO_ 1096 D_RQ_SRD_F1: 8 ESP_ABR
 SG_ D_RQ_SRD_F1 : 0|64@1+ (1,0) [0|9.22337203685e+18] "" Vector__XXX

CM_ SG_ 1096 D_RQ_SRD_F1 "D_RQ_SRD_F1 [source string/raw data]";

BA_ "GenMsgCycleTime" BO_ 1096 1;

BO_ 1097 D_RQ_SRD_F2: 8 ESP_ABR
 SG_ D_RQ_SRD_F2 : 0|64@1+ (1,0) [0|9.22337203685e+18] "" Vector__XXX

CM_ SG_ 1097 D_RQ_SRD_F2 "D_RQ_SRD_F2 [source string/raw data]";

BA_ "GenMsgCycleTime" BO_ 1097 1;

BO_ 1098 D_RQ_SRD_F3: 8 ESP_ABR
 SG_ D_RQ_SRD_F3 : 0|64@1+ (1,0) [0|9.22337203685e+18] "" Vector__XXX

CM_ SG_ 1098 D_RQ_SRD_F3 "D_RQ_SRD_F3 [source string/raw data]";

BA_ "GenMsgCycleTime" BO_ 1098 1;

BO_ 1099 D_RQ_SRD_F4: 8 ESP_ABR
 SG_ D_RQ_SRD_F4 : 0|64@1+ (1,0) [0|9.22337203685e+18] "" Vector__XXX

CM_ SG_ 1099 D_RQ_SRD_F4 "D_RQ_SRD_F4 [source string/raw data]";

BA_ "GenMsgCycleTime" BO_ 1099 1;

BO_ 1100 D_RQ_SRD_R1: 8 ESP_ABR
 SG_ D_RQ_SRD_R1 : 0|64@1+ (1,0) [0|9.22337203685e+18] "" Vector__XXX

CM_ SG_ 1100 D_RQ_SRD_R1 "D_RQ_SRD_R1 [source string/raw data]";

BA_ "GenMsgCycleTime" BO_ 1100 1;

BO_ 1101 D_RQ_SRD_R2: 8 ESP_ABR
 SG_ D_RQ_SRD_R2 : 0|64@1+ (1,0) [0|9.22337203685e+18] "" Vector__XXX

CM_ SG_ 1101 D_RQ_SRD_R2 "D_RQ_SRD_R2 [source string/raw data]";

BA_ "GenMsgCycleTime" BO_ 1101 1;

BO_ 1103 D_RQ_SRD_R3: 8 ESP_ABR
 SG_ D_RQ_SRD_R3 : 0|64@1+ (1,0) [0|9.22337203685e+18] "" Vector__XXX

CM_ SG_ 1103 D_RQ_SRD_R3 "D_RQ_SRD_R3 [source string/raw data]";

BA_ "GenMsgCycleTime" BO_ 1103 1;

BO_ 1153 D_RS_IC: 8 ESP_ABR
 SG_ D_RS_IC : 0|64@1+ (1,0) [0|9.22337203685e+18] "" Vector__XXX

CM_ SG_ 1153 D_RS_IC "D_RS_IC [source string/raw data]";

BA_ "GenMsgCycleTime" BO_ 1153 1;

BO_ 1154 D_RS_EIS: 8 ESP_ABR
 SG_ D_RS_EIS : 0|64@1+ (1,0) [0|9.22337203685e+18] "" Vector__XXX

CM_ SG_ 1154 D_RS_EIS "D_RS_EIS [source string/raw data]";

BA_ "GenMsgCycleTime" BO_ 1154 1;

BO_ 1156 D_RS_SCCM: 8 ESP_ABR
 SG_ D_RS_SCCM : 0|64@1+ (1,0) [0|9.22337203685e+18] "" Vector__XXX

CM_ SG_ 1156 D_RS_SCCM "D_RS_SCCM [source string/raw data]";

BA_ "GenMsgCycleTime" BO_ 1156 1;

BO_ 1157 D_RS_DRVU: 8 ESP_ABR
 SG_ D_RS_DRVU : 0|64@1+ (1,0) [0|9.22337203685e+18] "" Vector__XXX

CM_ SG_ 1157 D_RS_DRVU "D_RS_DRVU [source string/raw data]";

BA_ "GenMsgCycleTime" BO_ 1157 1;

BO_ 1158 D_RS_SBC: 8 ESP_ABR
 SG_ D_RS_SBC : 0|64@1+ (1,0) [0|9.22337203685e+18] "" Vector__XXX

CM_ SG_ 1158 D_RS_SBC "D_RS_SBC [source string/raw data]";

BA_ "GenMsgCycleTime" BO_ 1158 1;

BO_ 1159 D_RS_RDU: 8 ESP_ABR
 SG_ D_RS_RDU : 0|64@1+ (1,0) [0|9.22337203685e+18] "" Vector__XXX

CM_ SG_ 1159 D_RS_RDU "D_RS_RDU [source string/raw data]";

BA_ "GenMsgCycleTime" BO_ 1159 1;

BO_ 1160 D_RS_TPM_CHASSIS: 8 ESP_ABR
 SG_ D_RS_TPM_CHASSIS : 0|64@1+ (1,0) [0|9.22337203685e+18] "" Vector__XXX

CM_ SG_ 1160 D_RS_TPM_CHASSIS "D_RS_TPM_CHASSIS [source string/raw data]";

BA_ "GenMsgCycleTime" BO_ 1160 1;

BO_ 1161 D_RS_ORC: 8 ESP_ABR
 SG_ D_RS_ORC : 0|64@1+ (1,0) [0|9.22337203685e+18] "" Vector__XXX

CM_ SG_ 1161 D_RS_ORC "D_RS_ORC [source string/raw data]";

BA_ "GenMsgCycleTime" BO_ 1161 1;

BO_ 1170 D_RS_SPC: 8 ESP_ABR
 SG_ D_RS_SPC : 0|64@1+ (1,0) [0|9.22337203685e+18] "" Vector__XXX

CM_ SG_ 1170 D_RS_SPC "D_RS_SPC [source string/raw data]";

BA_ "GenMsgCycleTime" BO_ 1170 1;

BO_ 1172 D_RS_MPC: 8 ESP_ABR
 SG_ D_RS_MPC : 0|64@1+ (1,0) [0|9.22337203685e+18] "" Vector__XXX

CM_ SG_ 1172 D_RS_MPC "D_RS_MPC [source string/raw data]";

BA_ "GenMsgCycleTime" BO_ 1172 1;

BO_ 1174 D_RS_EPS: 8 ESP_ABR
 SG_ D_RS_EPS : 0|64@1+ (1,0) [0|9.22337203685e+18] "" Vector__XXX

CM_ SG_ 1174 D_RS_EPS "D_RS_EPS [source string/raw data]";

BA_ "GenMsgCycleTime" BO_ 1174 1;

BO_ 1175 D_RS_RBTM_FL: 8 ESP_ABR
 SG_ D_RS_RBTM_FL : 0|64@1+ (1,0) [0|9.22337203685e+18] "" Vector__XXX

CM_ SG_ 1175 D_RS_RBTM_FL "D_RS_RBTM_FL [source string/raw data]";

BA_ "GenMsgCycleTime" BO_ 1175 1;

BO_ 1176 D_RS_RBTM_FR: 8 ESP_ABR
 SG_ D_RS_RBTM_FR : 0|64@1+ (1,0) [0|9.22337203685e+18] "" Vector__XXX

CM_ SG_ 1176 D_RS_RBTM_FR "D_RS_RBTM_FR [source string/raw data]";

BA_ "GenMsgCycleTime" BO_ 1176 1;

BO_ 1177 D_RS_EAC: 8 ESP_ABR
 SG_ D_RS_EAC : 0|64@1+ (1,0) [0|9.22337203685e+18] "" Vector__XXX

CM_ SG_ 1177 D_RS_EAC "D_RS_EAC [source string/raw data]";

BA_ "GenMsgCycleTime" BO_ 1177 1;

BO_ 1178 D_RS_DCDC1: 8 ESP_ABR
 SG_ D_RS_DCDC1 : 0|64@1+ (1,0) [0|9.22337203685e+18] "" Vector__XXX

CM_ SG_ 1178 D_RS_DCDC1 "D_RS_DCDC1 [source string/raw data]";

BA_ "GenMsgCycleTime" BO_ 1178 1;

BO_ 1181 D_RS_ISM: 8 ESP_ABR
 SG_ D_RS_ISM : 0|64@1+ (1,0) [0|9.22337203685e+18] "" Vector__XXX

CM_ SG_ 1181 D_RS_ISM "D_RS_ISM [source string/raw data]";

BA_ "GenMsgCycleTime" BO_ 1181 1;

BO_ 1182 D_RS_SSP: 8 ESP_ABR
 SG_ D_RS_SSP : 0|64@1+ (1,0) [0|9.22337203685e+18] "" Vector__XXX

CM_ SG_ 1182 D_RS_SSP "D_RS_SSP [source string/raw data]";

BA_ "GenMsgCycleTime" BO_ 1182 1;

BO_ 1183 D_RS_FSCM: 8 ESP_ABR
 SG_ D_RS_FSCM : 0|64@1+ (1,0) [0|9.22337203685e+18] "" Vector__XXX

CM_ SG_ 1183 D_RS_FSCM "D_RS_FSCM [source string/raw data]";

BA_ "GenMsgCycleTime" BO_ 1183 1;

BO_ 1184 D_RS_DTR: 8 ESP_ABR
 SG_ D_RS_DTR : 0|64@1+ (1,0) [0|9.22337203685e+18] "" Vector__XXX

CM_ SG_ 1184 D_RS_DTR "D_RS_DTR [source string/raw data]";

BA_ "GenMsgCycleTime" BO_ 1184 1;

BO_ 1185 D_RS_NV: 8 ESP_ABR
 SG_ D_RS_NV : 0|64@1+ (1,0) [0|9.22337203685e+18] "" Vector__XXX

CM_ SG_ 1185 D_RS_NV "D_RS_NV [source string/raw data]";

BA_ "GenMsgCycleTime" BO_ 1185 1;

BO_ 1186 D_RS_SBC_SC: 8 ESP_ABR
 SG_ D_RS_SBC_SC : 0|64@1+ (1,0) [0|9.22337203685e+18] "" Vector__XXX

CM_ SG_ 1186 D_RS_SBC_SC "D_RS_SBC_SC [source string/raw data]";

BA_ "GenMsgCycleTime" BO_ 1186 1;

BO_ 1187 D_RS_SSM: 8 ESP_ABR
 SG_ D_RS_SSM : 0|64@1+ (1,0) [0|9.22337203685e+18] "" Vector__XXX

CM_ SG_ 1187 D_RS_SSM "D_RS_SSM [source string/raw data]";

BA_ "GenMsgCycleTime" BO_ 1187 1;

BO_ 1190 D_RS_EPKB: 8 ESP_ABR
 SG_ D_RS_EPKB : 0|64@1+ (1,0) [0|9.22337203685e+18] "" Vector__XXX

CM_ SG_ 1190 D_RS_EPKB "D_RS_EPKB [source string/raw data]";

BA_ "GenMsgCycleTime" BO_ 1190 1;

BO_ 1193 SG_APPL_ECM_B1: 8 ESP_ABR
 SG_ SG_APPL_ECM_B1 : 0|64@1+ (1,0) [0|9.22337203685e+18] "" Vector__XXX

CM_ SG_ 1193 SG_APPL_ECM_B1 "SG_APPL_ECM_B1 [source string/raw data]";

BA_ "GenMsgCycleTime" BO_ 1193 1;

BO_ 1196 D_RS_CNG: 8 ESP_ABR
 SG_ D_RS_CNG : 0|64@1+ (1,0) [0|9.22337203685e+18] "" Vector__XXX

CM_ SG_ 1196 D_RS_CNG "D_RS_CNG [source string/raw data]";

BA_ "GenMsgCycleTime" BO_ 1196 1;

BO_ 1199 D_RS_TSLM: 8 ESP_ABR
 SG_ D_RS_TSLM : 0|64@1+ (1,0) [0|9.22337203685e+18] "" Vector__XXX

CM_ SG_ 1199 D_RS_TSLM "D_RS_TSLM [source string/raw data]";

BA_ "GenMsgCycleTime" BO_ 1199 1;

BO_ 1201 D_RS_PTS_APX: 8 ESP_ABR
 SG_ D_RS_PTS_APX : 0|64@1+ (1,0) [0|9.22337203685e+18] "" Vector__XXX

CM_ SG_ 1201 D_RS_PTS_APX "D_RS_PTS_APX [source string/raw data]";

BA_ "GenMsgCycleTime" BO_ 1201 1;

BO_ 1202 D_RS_DSI: 8 ESP_ABR
 SG_ D_RS_DSI : 0|64@1+ (1,0) [0|9.22337203685e+18] "" Vector__XXX

CM_ SG_ 1202 D_RS_DSI "D_RS_DSI [source string/raw data]";

BA_ "GenMsgCycleTime" BO_ 1202 1;

BO_ 1203 D_RS_TCASE: 8 ESP_ABR
 SG_ D_RS_TCASE : 0|64@1+ (1,0) [0|9.22337203685e+18] "" Vector__XXX

CM_ SG_ 1203 D_RS_TCASE "D_RS_TCASE [source string/raw data]";

BA_ "GenMsgCycleTime" BO_ 1203 1;

BO_ 1205 D_RS_FSCM2: 8 ESP_ABR
 SG_ D_RS_FSCM2 : 0|64@1+ (1,0) [0|9.22337203685e+18] "" Vector__XXX

CM_ SG_ 1205 D_RS_FSCM2 "D_RS_FSCM2 [source string/raw data]";

BA_ "GenMsgCycleTime" BO_ 1205 1;

BO_ 1281 SG_APPL_IC: 8 ESP_ABR
 SG_ SG_APPL_IC : 0|64@1+ (1,0) [0|9.22337203685e+18] "" Vector__XXX

CM_ SG_ 1281 SG_APPL_IC "SG_APPL_IC [source string/raw data]";

BA_ "GenMsgCycleTime" BO_ 1281 1;

BO_ 1282 SG_APPL_EIS: 8 ESP_ABR
 SG_ SG_APPL_EIS : 0|64@1+ (1,0) [0|9.22337203685e+18] "" Vector__XXX

CM_ SG_ 1282 SG_APPL_EIS "SG_APPL_EIS [source string/raw data]";

BA_ "GenMsgCycleTime" BO_ 1282 1;

BO_ 1284 SG_APPL_SCCM: 8 ESP_ABR
 SG_ SG_APPL_SCCM : 0|64@1+ (1,0) [0|9.22337203685e+18] "" Vector__XXX

CM_ SG_ 1284 SG_APPL_SCCM "SG_APPL_SCCM [source string/raw data]";

BA_ "GenMsgCycleTime" BO_ 1284 1;

BO_ 1286 SG_APPL_SBC: 8 ESP_ABR
 SG_ SG_APPL_SBC : 0|64@1+ (1,0) [0|9.22337203685e+18] "" Vector__XXX

CM_ SG_ 1286 SG_APPL_SBC "SG_APPL_SBC [source string/raw data]";

BA_ "GenMsgCycleTime" BO_ 1286 1;

BO_ 1287 SG_APPL_RDU: 8 ESP_ABR
 SG_ SG_APPL_RDU : 0|64@1+ (1,0) [0|9.22337203685e+18] "" Vector__XXX

CM_ SG_ 1287 SG_APPL_RDU "SG_APPL_RDU [source string/raw data]";

BA_ "GenMsgCycleTime" BO_ 1287 1;

BO_ 1289 SG_APPL_ORC: 8 ESP_ABR
 SG_ SG_APPL_ORC : 0|64@1+ (1,0) [0|9.22337203685e+18] "" Vector__XXX

CM_ SG_ 1289 SG_APPL_ORC "SG_APPL_ORC [source string/raw data]";

BA_ "GenMsgCycleTime" BO_ 1289 1;

BO_ 1298 SG_APPL_SPC: 8 ESP_ABR
 SG_ SG_APPL_SPC : 0|64@1+ (1,0) [0|9.22337203685e+18] "" Vector__XXX

CM_ SG_ 1298 SG_APPL_SPC "SG_APPL_SPC [source string/raw data]";

BA_ "GenMsgCycleTime" BO_ 1298 1;

BO_ 1302 SG_APPL_EPS: 8 ESP_ABR
 SG_ SG_APPL_EPS : 0|64@1+ (1,0) [0|9.22337203685e+18] "" Vector__XXX

CM_ SG_ 1302 SG_APPL_EPS "SG_APPL_EPS [source string/raw data]";

BA_ "GenMsgCycleTime" BO_ 1302 1;

BO_ 1303 SG_APPL_RBTM_FL: 8 ESP_ABR
 SG_ SG_APPL_RBTM_FL : 0|64@1+ (1,0) [0|9.22337203685e+18] "" Vector__XXX

CM_ SG_ 1303 SG_APPL_RBTM_FL "SG_APPL_RBTM_FL [source string/raw data]";

BA_ "GenMsgCycleTime" BO_ 1303 1;

BO_ 1304 SG_APPL_RBTM_FR: 8 ESP_ABR
 SG_ SG_APPL_RBTM_FR : 0|64@1+ (1,0) [0|9.22337203685e+18] "" Vector__XXX

CM_ SG_ 1304 SG_APPL_RBTM_FR "SG_APPL_RBTM_FR [source string/raw data]";

BA_ "GenMsgCycleTime" BO_ 1304 1;

BO_ 1305 SG_APPL_EAC: 8 ESP_ABR
 SG_ SG_APPL_EAC : 0|64@1+ (1,0) [0|9.22337203685e+18] "" Vector__XXX

CM_ SG_ 1305 SG_APPL_EAC "SG_APPL_EAC [source string/raw data]";

BA_ "GenMsgCycleTime" BO_ 1305 1;

BO_ 1306 SG_APPL_DCDC1: 8 ESP_ABR
 SG_ SG_APPL_DCDC1 : 0|64@1+ (1,0) [0|9.22337203685e+18] "" Vector__XXX

CM_ SG_ 1306 SG_APPL_DCDC1 "SG_APPL_DCDC1 [source string/raw data]";

BA_ "GenMsgCycleTime" BO_ 1306 1;

BO_ 1307 SG_APPL_EM1: 8 ESP_ABR
 SG_ SG_APPL_EM1 : 0|64@1+ (1,0) [0|9.22337203685e+18] "" Vector__XXX

CM_ SG_ 1307 SG_APPL_EM1 "SG_APPL_EM1 [source string/raw data]";

BA_ "GenMsgCycleTime" BO_ 1307 1;

BO_ 1308 SG_APPL_TCM: 8 ESP_ABR
 SG_ SG_APPL_TCM : 0|64@1+ (1,0) [0|9.22337203685e+18] "" Vector__XXX

CM_ SG_ 1308 SG_APPL_TCM "SG_APPL_TCM [source string/raw data]";

BA_ "GenMsgCycleTime" BO_ 1308 1;

BO_ 1309 SG_APPL_ISM: 8 ESP_ABR
 SG_ SG_APPL_ISM : 0|64@1+ (1,0) [0|9.22337203685e+18] "" Vector__XXX

CM_ SG_ 1309 SG_APPL_ISM "SG_APPL_ISM [source string/raw data]";

BA_ "GenMsgCycleTime" BO_ 1309 1;

BO_ 1310 SG_APPL_SSP: 8 ESP_ABR
 SG_ SG_APPL_SSP : 0|64@1+ (1,0) [0|9.22337203685e+18] "" Vector__XXX

CM_ SG_ 1310 SG_APPL_SSP "SG_APPL_SSP [source string/raw data]";

BA_ "GenMsgCycleTime" BO_ 1310 1;

BO_ 1311 SG_APPL_FSCM: 8 ESP_ABR
 SG_ SG_APPL_FSCM : 0|64@1+ (1,0) [0|9.22337203685e+18] "" Vector__XXX

CM_ SG_ 1311 SG_APPL_FSCM "SG_APPL_FSCM [source string/raw data]";

BA_ "GenMsgCycleTime" BO_ 1311 1;

BO_ 1312 SG_APPL_DTR: 8 ESP_ABR
 SG_ SG_APPL_DTR : 0|64@1+ (1,0) [0|9.22337203685e+18] "" Vector__XXX

CM_ SG_ 1312 SG_APPL_DTR "SG_APPL_DTR [source string/raw data]";

BA_ "GenMsgCycleTime" BO_ 1312 1;

BO_ 1314 SG_APPL_SBC_SC: 8 ESP_ABR
 SG_ SG_APPL_SBC_SC : 0|64@1+ (1,0) [0|9.22337203685e+18] "" Vector__XXX

CM_ SG_ 1314 SG_APPL_SBC_SC "SG_APPL_SBC_SC [source string/raw data]";

BA_ "GenMsgCycleTime" BO_ 1314 1;

BO_ 1315 SG_APPL_SSM: 8 ESP_ABR
 SG_ SG_APPL_SSM : 0|64@1+ (1,0) [0|9.22337203685e+18] "" Vector__XXX

CM_ SG_ 1315 SG_APPL_SSM "SG_APPL_SSM [source string/raw data]";

BA_ "GenMsgCycleTime" BO_ 1315 1;

BO_ 1321 SG_APPL_ECM: 8 ESP_ABR
 SG_ SG_APPL_ECM : 0|64@1+ (1,0) [0|9.22337203685e+18] "" Vector__XXX

CM_ SG_ 1321 SG_APPL_ECM "SG_APPL_ECM [source string/raw data]";

BA_ "GenMsgCycleTime" BO_ 1321 1;

BO_ 1328 SG_APPL_EM2: 8 ESP_ABR
 SG_ SG_APPL_EM2 : 0|64@1+ (1,0) [0|9.22337203685e+18] "" Vector__XXX

CM_ SG_ 1328 SG_APPL_EM2 "SG_APPL_EM2 [source string/raw data]";

BA_ "GenMsgCycleTime" BO_ 1328 1;

BO_ 1331 SG_APPL_TCASE: 8 ESP_ABR
 SG_ SG_APPL_TCASE : 0|64@1+ (1,0) [0|9.22337203685e+18] "" Vector__XXX

CM_ SG_ 1331 SG_APPL_TCASE "SG_APPL_TCASE [source string/raw data]";

BA_ "GenMsgCycleTime" BO_ 1331 1;

BO_ 1332 SG_APPL_BMS: 8 ESP_ABR
 SG_ SG_APPL_BMS : 0|64@1+ (1,0) [0|9.22337203685e+18] "" Vector__XXX

CM_ SG_ 1332 SG_APPL_BMS "SG_APPL_BMS [source string/raw data]";

BA_ "GenMsgCycleTime" BO_ 1332 1;

BO_ 1352 SG_APPL_TPM: 8 ESP_ABR
 SG_ SG_APPL_TPM : 0|64@1+ (1,0) [0|9.22337203685e+18] "" Vector__XXX

CM_ SG_ 1352 SG_APPL_TPM "SG_APPL_TPM [source string/raw data]";

BA_ "GenMsgCycleTime" BO_ 1352 1;

BO_ 1409 SD_RS_IC: 8 ESP_ABR
 SG_ SD_RS_IC : 0|64@1+ (1,0) [0|9.22337203685e+18] "" Vector__XXX

CM_ SG_ 1409 SD_RS_IC "SD_RS_IC [source string/raw data]";

BA_ "GenMsgCycleTime" BO_ 1409 1;

BO_ 1410 SD_RS_EIS: 8 ESP_ABR
 SG_ SD_RS_EIS : 0|64@1+ (1,0) [0|9.22337203685e+18] "" Vector__XXX

CM_ SG_ 1410 SD_RS_EIS "SD_RS_EIS [source string/raw data]";

BA_ "GenMsgCycleTime" BO_ 1410 1;

BO_ 1412 SD_RS_SCCM: 8 ESP_ABR
 SG_ SD_RS_SCCM : 0|64@1+ (1,0) [0|9.22337203685e+18] "" Vector__XXX

CM_ SG_ 1412 SD_RS_SCCM "SD_RS_SCCM [source string/raw data]";

BA_ "GenMsgCycleTime" BO_ 1412 1;

BO_ 1413 SD_RS_DRVU: 8 ESP_ABR
 SG_ SD_RS_DRVU : 0|64@1+ (1,0) [0|9.22337203685e+18] "" Vector__XXX

CM_ SG_ 1413 SD_RS_DRVU "SD_RS_DRVU [source string/raw data]";

BA_ "GenMsgCycleTime" BO_ 1413 1;

BO_ 1414 SD_RS_SBC: 8 ESP_ABR
 SG_ SD_RS_SBC : 0|64@1+ (1,0) [0|9.22337203685e+18] "" Vector__XXX

CM_ SG_ 1414 SD_RS_SBC "SD_RS_SBC [source string/raw data]";

BA_ "GenMsgCycleTime" BO_ 1414 1;

BO_ 1415 SD_RS_RDU: 8 ESP_ABR
 SG_ SD_RS_RDU : 0|64@1+ (1,0) [0|9.22337203685e+18] "" Vector__XXX

CM_ SG_ 1415 SD_RS_RDU "SD_RS_RDU [source string/raw data]";

BA_ "GenMsgCycleTime" BO_ 1415 1;

BO_ 1416 SD_RS_TPM_CHASSIS: 8 ESP_ABR
 SG_ SD_RS_TPM_CHASSIS : 0|64@1+ (1,0) [0|9.22337203685e+18] "" Vector__XXX

CM_ SG_ 1416 SD_RS_TPM_CHASSIS "SD_RS_TPM_CHASSIS [source string/raw data]";

BA_ "GenMsgCycleTime" BO_ 1416 1;

BO_ 1417 SD_RS_ORC: 8 ESP_ABR
 SG_ SD_RS_ORC : 0|64@1+ (1,0) [0|9.22337203685e+18] "" Vector__XXX

CM_ SG_ 1417 SD_RS_ORC "SD_RS_ORC [source string/raw data]";

BA_ "GenMsgCycleTime" BO_ 1417 1;

BO_ 1426 SD_RS_SPC: 8 ESP_ABR
 SG_ SD_RS_SPC : 0|64@1+ (1,0) [0|9.22337203685e+18] "" Vector__XXX

CM_ SG_ 1426 SD_RS_SPC "SD_RS_SPC [source string/raw data]";

BA_ "GenMsgCycleTime" BO_ 1426 1;

BO_ 1428 SD_RS_MPC: 8 ESP_ABR
 SG_ SD_RS_MPC : 0|64@1+ (1,0) [0|9.22337203685e+18] "" Vector__XXX

CM_ SG_ 1428 SD_RS_MPC "SD_RS_MPC [source string/raw data]";

BA_ "GenMsgCycleTime" BO_ 1428 1;

BO_ 1430 SD_RS_EPS: 8 ESP_ABR
 SG_ SD_RS_EPS : 0|64@1+ (1,0) [0|9.22337203685e+18] "" Vector__XXX

CM_ SG_ 1430 SD_RS_EPS "SD_RS_EPS [source string/raw data]";

BA_ "GenMsgCycleTime" BO_ 1430 1;

BO_ 1431 SD_RS_RBTM_FL: 8 ESP_ABR
 SG_ SD_RS_RBTM_FL : 0|64@1+ (1,0) [0|9.22337203685e+18] "" Vector__XXX

CM_ SG_ 1431 SD_RS_RBTM_FL "SD_RS_RBTM_FL [source string/raw data]";

BA_ "GenMsgCycleTime" BO_ 1431 1;

BO_ 1432 SD_RS_RBTM_FR: 8 ESP_ABR
 SG_ SD_RS_RBTM_FR : 0|64@1+ (1,0) [0|9.22337203685e+18] "" Vector__XXX

CM_ SG_ 1432 SD_RS_RBTM_FR "SD_RS_RBTM_FR [source string/raw data]";

BA_ "GenMsgCycleTime" BO_ 1432 1;

BO_ 1433 SD_RS_EAC: 8 ESP_ABR
 SG_ SD_RS_EAC : 0|64@1+ (1,0) [0|9.22337203685e+18] "" Vector__XXX

CM_ SG_ 1433 SD_RS_EAC "SD_RS_EAC [source string/raw data]";

BA_ "GenMsgCycleTime" BO_ 1433 1;

BO_ 1434 SD_RS_DCDC1: 8 ESP_ABR
 SG_ SD_RS_DCDC1 : 0|64@1+ (1,0) [0|9.22337203685e+18] "" Vector__XXX

CM_ SG_ 1434 SD_RS_DCDC1 "SD_RS_DCDC1 [source string/raw data]";

BA_ "GenMsgCycleTime" BO_ 1434 1;

BO_ 1435 SD_RS_EM1: 8 ESP_ABR
 SG_ SD_RS_EM1 : 0|64@1+ (1,0) [0|9.22337203685e+18] "" Vector__XXX

CM_ SG_ 1435 SD_RS_EM1 "SD_RS_EM1 [source string/raw data]";

BA_ "GenMsgCycleTime" BO_ 1435 1;

BO_ 1436 SD_RS_TCM: 8 ESP_ABR
 SG_ SD_RS_TCM : 0|64@1+ (1,0) [0|9.22337203685e+18] "" Vector__XXX

CM_ SG_ 1436 SD_RS_TCM "SD_RS_TCM [source string/raw data]";

BA_ "GenMsgCycleTime" BO_ 1436 1;

BO_ 1437 SD_RS_ISM: 8 ESP_ABR
 SG_ SD_RS_ISM : 0|64@1+ (1,0) [0|9.22337203685e+18] "" Vector__XXX

CM_ SG_ 1437 SD_RS_ISM "SD_RS_ISM [source string/raw data]";

BA_ "GenMsgCycleTime" BO_ 1437 1;

BO_ 1438 SD_RS_SSP: 8 ESP_ABR
 SG_ SD_RS_SSP : 0|64@1+ (1,0) [0|9.22337203685e+18] "" Vector__XXX

CM_ SG_ 1438 SD_RS_SSP "SD_RS_SSP [source string/raw data]";

BA_ "GenMsgCycleTime" BO_ 1438 1;

BO_ 1439 SD_RS_FSCM: 8 ESP_ABR
 SG_ SD_RS_FSCM : 0|64@1+ (1,0) [0|9.22337203685e+18] "" Vector__XXX

CM_ SG_ 1439 SD_RS_FSCM "SD_RS_FSCM [source string/raw data]";

BA_ "GenMsgCycleTime" BO_ 1439 1;

BO_ 1440 SD_RS_DTR: 8 ESP_ABR
 SG_ SD_RS_DTR : 0|64@1+ (1,0) [0|9.22337203685e+18] "" Vector__XXX

CM_ SG_ 1440 SD_RS_DTR "SD_RS_DTR [source string/raw data]";

BA_ "GenMsgCycleTime" BO_ 1440 1;

BO_ 1441 SD_RS_NV: 8 ESP_ABR
 SG_ SD_RS_NV : 0|64@1+ (1,0) [0|9.22337203685e+18] "" Vector__XXX

CM_ SG_ 1441 SD_RS_NV "SD_RS_NV [source string/raw data]";

BA_ "GenMsgCycleTime" BO_ 1441 1;

BO_ 1442 SD_RS_SBC_SC: 8 ESP_ABR
 SG_ SD_RS_SBC_SC : 0|64@1+ (1,0) [0|9.22337203685e+18] "" Vector__XXX

CM_ SG_ 1442 SD_RS_SBC_SC "SD_RS_SBC_SC [source string/raw data]";

BA_ "GenMsgCycleTime" BO_ 1442 1;

BO_ 1443 SD_RS_SSM: 8 ESP_ABR
 SG_ SD_RS_SSM : 0|64@1+ (1,0) [0|9.22337203685e+18] "" Vector__XXX

CM_ SG_ 1443 SD_RS_SSM "SD_RS_SSM [source string/raw data]";

BA_ "GenMsgCycleTime" BO_ 1443 1;

BO_ 1445 SD_RS_SCRCM: 8 ESP_ABR
 SG_ SD_RS_SCRCM : 0|64@1+ (1,0) [0|9.22337203685e+18] "" Vector__XXX

CM_ SG_ 1445 SD_RS_SCRCM "SD_RS_SCRCM [source string/raw data]";

BA_ "GenMsgCycleTime" BO_ 1445 1;

BO_ 1446 SD_RS_EPKB: 8 ESP_ABR
 SG_ SD_RS_EPKB : 0|64@1+ (1,0) [0|9.22337203685e+18] "" Vector__XXX

CM_ SG_ 1446 SD_RS_EPKB "SD_RS_EPKB [source string/raw data]";

BA_ "GenMsgCycleTime" BO_ 1446 1;

BO_ 1449 SD_RS_ECM: 8 ESP_ABR
 SG_ SD_RS_ECM : 0|64@1+ (1,0) [0|9.22337203685e+18] "" Vector__XXX

CM_ SG_ 1449 SD_RS_ECM "SD_RS_ECM [source string/raw data]";

BA_ "GenMsgCycleTime" BO_ 1449 1;

BO_ 1455 SD_RS_TSLM: 8 ESP_ABR
 SG_ SD_RS_TSLM : 0|64@1+ (1,0) [0|9.22337203685e+18] "" Vector__XXX

CM_ SG_ 1455 SD_RS_TSLM "SD_RS_TSLM [source string/raw data]";

BA_ "GenMsgCycleTime" BO_ 1455 1;

BO_ 1456 SD_RS_EM2: 8 ESP_ABR
 SG_ SD_RS_EM2 : 0|64@1+ (1,0) [0|9.22337203685e+18] "" Vector__XXX

CM_ SG_ 1456 SD_RS_EM2 "SD_RS_EM2 [source string/raw data]";

BA_ "GenMsgCycleTime" BO_ 1456 1;

BO_ 1457 SD_RS_PTS_APX: 8 ESP_ABR
 SG_ SD_RS_PTS_APX : 0|64@1+ (1,0) [0|9.22337203685e+18] "" Vector__XXX

CM_ SG_ 1457 SD_RS_PTS_APX "SD_RS_PTS_APX [source string/raw data]";

BA_ "GenMsgCycleTime" BO_ 1457 1;

BO_ 1458 SD_RS_DSI: 8 ESP_ABR
 SG_ SD_RS_DSI : 0|64@1+ (1,0) [0|9.22337203685e+18] "" Vector__XXX

CM_ SG_ 1458 SD_RS_DSI "SD_RS_DSI [source string/raw data]";

BA_ "GenMsgCycleTime" BO_ 1458 1;

BO_ 1459 SD_RS_TCASE: 8 ESP_ABR
 SG_ SD_RS_TCASE : 0|64@1+ (1,0) [0|9.22337203685e+18] "" Vector__XXX

CM_ SG_ 1459 SD_RS_TCASE "SD_RS_TCASE [source string/raw data]";

BA_ "GenMsgCycleTime" BO_ 1459 1;

BO_ 1460 SD_RS_BMS: 8 ESP_ABR
 SG_ SD_RS_BMS : 0|64@1+ (1,0) [0|9.22337203685e+18] "" Vector__XXX

CM_ SG_ 1460 SD_RS_BMS "SD_RS_BMS [source string/raw data]";

BA_ "GenMsgCycleTime" BO_ 1460 1;

BO_ 1461 SD_RS_FSCM2: 8 ESP_ABR
 SG_ SD_RS_FSCM2 : 0|64@1+ (1,0) [0|9.22337203685e+18] "" Vector__XXX

CM_ SG_ 1461 SD_RS_FSCM2 "SD_RS_FSCM2 [source string/raw data]";

BA_ "GenMsgCycleTime" BO_ 1461 1;

BO_ 1536 SG_APPL_ISM2: 8 ESP_ABR
 SG_ SG_APPL_ISM2 : 0|64@1+ (1,0) [0|9.22337203685e+18] "" Vector__XXX

CM_ SG_ 1536 SG_APPL_ISM2 "SG_APPL_ISM2 [source string/raw data]";

BA_ "GenMsgCycleTime" BO_ 1536 1;

BO_ 1543 MESS_TPM1: 8 ESP_ABR
 SG_ MESS_TPM1 : 0|64@1+ (1,0) [0|9.22337203685e+18] "" Vector__XXX

CM_ SG_ 1543 MESS_TPM1 "MESS_TPM1 [source string/raw data]";

BA_ "GenMsgCycleTime" BO_ 1543 1;

BO_ 1546 D_RQ_IC: 8 ESP_ABR
 SG_ D_RQ_IC : 0|64@1+ (1,0) [0|9.22337203685e+18] "" Vector__XXX

CM_ SG_ 1546 D_RQ_IC "D_RQ_IC [source string/raw data]";

BA_ "GenMsgCycleTime" BO_ 1546 1;

BO_ 1548 APPL_SG_IC: 8 ESP_ABR
 SG_ APPL_SG_IC : 0|64@1+ (1,0) [0|9.22337203685e+18] "" Vector__XXX

CM_ SG_ 1548 APPL_SG_IC "APPL_SG_IC [source string/raw data]";

BA_ "GenMsgCycleTime" BO_ 1548 1;

BO_ 1552 SG_APPL_ECM3: 8 ESP_ABR
 SG_ SG_APPL_ECM3 : 0|64@1+ (1,0) [0|9.22337203685e+18] "" Vector__XXX

CM_ SG_ 1552 SG_APPL_ECM3 "SG_APPL_ECM3 [source string/raw data]";

BA_ "GenMsgCycleTime" BO_ 1552 1;

BO_ 1554 D_RQ_EIS: 8 ESP_ABR
 SG_ D_RQ_EIS : 0|64@1+ (1,0) [0|9.22337203685e+18] "" Vector__XXX

CM_ SG_ 1554 D_RQ_EIS "D_RQ_EIS [source string/raw data]";

BA_ "GenMsgCycleTime" BO_ 1554 1;

BO_ 1556 APPL_SG_EIS: 8 ESP_ABR
 SG_ APPL_SG_EIS : 0|64@1+ (1,0) [0|9.22337203685e+18] "" Vector__XXX

CM_ SG_ 1556 APPL_SG_EIS "APPL_SG_EIS [source string/raw data]";

BA_ "GenMsgCycleTime" BO_ 1556 1;

BO_ 1560 SG_APPL_ECM4: 8 ESP_ABR
 SG_ SG_APPL_ECM4 : 0|64@1+ (1,0) [0|9.22337203685e+18] "" Vector__XXX

CM_ SG_ 1560 SG_APPL_ECM4 "SG_APPL_ECM4 [source string/raw data]";

BA_ "GenMsgCycleTime" BO_ 1560 1;

BO_ 1568 APPL_SG_IC_FLASH: 8 ESP_ABR
 SG_ APPL_SG_IC_FLASH : 0|64@1+ (1,0) [0|9.22337203685e+18] "" Vector__XXX

CM_ SG_ 1568 APPL_SG_IC_FLASH "APPL_SG_IC_FLASH [source string/raw data]";

BA_ "GenMsgCycleTime" BO_ 1568 1;

BO_ 1570 D_RQ_SCCM: 8 ESP_ABR
 SG_ D_RQ_SCCM : 0|64@1+ (1,0) [0|9.22337203685e+18] "" Vector__XXX

CM_ SG_ 1570 D_RQ_SCCM "D_RQ_SCCM [source string/raw data]";

BA_ "GenMsgCycleTime" BO_ 1570 1;

BO_ 1572 APPL_SG_SCCM: 8 ESP_ABR
 SG_ APPL_SG_SCCM : 0|64@1+ (1,0) [0|9.22337203685e+18] "" Vector__XXX

CM_ SG_ 1572 APPL_SG_SCCM "APPL_SG_SCCM [source string/raw data]";

BA_ "GenMsgCycleTime" BO_ 1572 1;

BO_ 1576 SG_APPL_IC_FLASH: 8 ESP_ABR
 SG_ SG_APPL_IC_FLASH : 0|64@1+ (1,0) [0|9.22337203685e+18] "" Vector__XXX

CM_ SG_ 1576 SG_APPL_IC_FLASH "SG_APPL_IC_FLASH [source string/raw data]";

BA_ "GenMsgCycleTime" BO_ 1576 1;

BO_ 1578 D_RQ_DRVU: 8 ESP_ABR
 SG_ D_RQ_DRVU : 0|64@1+ (1,0) [0|9.22337203685e+18] "" Vector__XXX

CM_ SG_ 1578 D_RQ_DRVU "D_RQ_DRVU [source string/raw data]";

BA_ "GenMsgCycleTime" BO_ 1578 1;

BO_ 1586 D_RQ_SBC: 8 ESP_ABR
 SG_ D_RQ_SBC : 0|64@1+ (1,0) [0|9.22337203685e+18] "" Vector__XXX

CM_ SG_ 1586 D_RQ_SBC "D_RQ_SBC [source string/raw data]";

BA_ "GenMsgCycleTime" BO_ 1586 1;

BO_ 1588 APPL_SG_SBC: 8 ESP_ABR
 SG_ APPL_SG_SBC : 0|64@1+ (1,0) [0|9.22337203685e+18] "" Vector__XXX

CM_ SG_ 1588 APPL_SG_SBC "APPL_SG_SBC [source string/raw data]";

BA_ "GenMsgCycleTime" BO_ 1588 1;

BO_ 1594 D_RQ_RDU: 8 ESP_ABR
 SG_ D_RQ_RDU : 0|64@1+ (1,0) [0|9.22337203685e+18] "" Vector__XXX

CM_ SG_ 1594 D_RQ_RDU "D_RQ_RDU [source string/raw data]";

BA_ "GenMsgCycleTime" BO_ 1594 1;

BO_ 1596 APPL_SG_RDU: 8 ESP_ABR
 SG_ APPL_SG_RDU : 0|64@1+ (1,0) [0|9.22337203685e+18] "" Vector__XXX

CM_ SG_ 1596 APPL_SG_RDU "APPL_SG_RDU [source string/raw data]";

BA_ "GenMsgCycleTime" BO_ 1596 1;

BO_ 1602 D_RQ_TPM_CHASSIS: 8 ESP_ABR
 SG_ D_RQ_TPM_CHASSIS : 0|64@1+ (1,0) [0|9.22337203685e+18] "" Vector__XXX

CM_ SG_ 1602 D_RQ_TPM_CHASSIS "D_RQ_TPM_CHASSIS [source string/raw data]";

BA_ "GenMsgCycleTime" BO_ 1602 1;

BO_ 1605 APPL_SG_TPM: 8 ESP_ABR
 SG_ APPL_SG_TPM : 0|64@1+ (1,0) [0|9.22337203685e+18] "" Vector__XXX

CM_ SG_ 1605 APPL_SG_TPM "APPL_SG_TPM [source string/raw data]";

BA_ "GenMsgCycleTime" BO_ 1605 1;

BO_ 1610 D_RQ_ORC: 8 ESP_ABR
 SG_ D_RQ_ORC : 0|64@1+ (1,0) [0|9.22337203685e+18] "" Vector__XXX

CM_ SG_ 1610 D_RQ_ORC "D_RQ_ORC [source string/raw data]";

BA_ "GenMsgCycleTime" BO_ 1610 1;

BO_ 1612 APPL_SG_ORC: 8 ESP_ABR
 SG_ APPL_SG_ORC : 0|64@1+ (1,0) [0|9.22337203685e+18] "" Vector__XXX

CM_ SG_ 1612 APPL_SG_ORC "APPL_SG_ORC [source string/raw data]";

BA_ "GenMsgCycleTime" BO_ 1612 1;

BO_ 1630 MESS_ECM1: 8 ESP_ABR
 SG_ MESS_ECM1 : 0|64@1+ (1,0) [0|9.22337203685e+18] "" Vector__XXX

CM_ SG_ 1630 MESS_ECM1 "MESS_ECM1 [source string/raw data]";

BA_ "GenMsgCycleTime" BO_ 1630 1;

BO_ 1638 MESS_ECM2: 8 ESP_ABR
 SG_ MESS_ECM2 : 0|64@1+ (1,0) [0|9.22337203685e+18] "" Vector__XXX

CM_ SG_ 1638 MESS_ECM2 "MESS_ECM2 [source string/raw data]";

BA_ "GenMsgCycleTime" BO_ 1638 1;

BO_ 1646 MESS_EIS1: 8 ESP_ABR
 SG_ MESS_EIS1 : 0|64@1+ (1,0) [0|9.22337203685e+18] "" Vector__XXX

CM_ SG_ 1646 MESS_EIS1 "MESS_EIS1 [source string/raw data]";

BA_ "GenMsgCycleTime" BO_ 1646 1;

BO_ 1654 MESS_EIS2: 8 ESP_ABR
 SG_ MESS_EIS2 : 0|64@1+ (1,0) [0|9.22337203685e+18] "" Vector__XXX

CM_ SG_ 1654 MESS_EIS2 "MESS_EIS2 [source string/raw data]";

BA_ "GenMsgCycleTime" BO_ 1654 1;

BO_ 1682 D_RQ_SPC: 8 ESP_ABR
 SG_ D_RQ_SPC : 0|64@1+ (1,0) [0|9.22337203685e+18] "" Vector__XXX

CM_ SG_ 1682 D_RQ_SPC "D_RQ_SPC [source string/raw data]";

BA_ "GenMsgCycleTime" BO_ 1682 1;

BO_ 1684 APPL_SG_SPC: 8 ESP_ABR
 SG_ APPL_SG_SPC : 0|64@1+ (1,0) [0|9.22337203685e+18] "" Vector__XXX

CM_ SG_ 1684 APPL_SG_SPC "APPL_SG_SPC [source string/raw data]";

BA_ "GenMsgCycleTime" BO_ 1684 1;

BO_ 1694 MESS_SPC1: 8 ESP_ABR
 SG_ MESS_SPC1 : 0|64@1+ (1,0) [0|9.22337203685e+18] "" Vector__XXX

CM_ SG_ 1694 MESS_SPC1 "MESS_SPC1 [source string/raw data]";

BA_ "GenMsgCycleTime" BO_ 1694 1;

BO_ 1698 D_RQ_MPC: 8 ESP_ABR
 SG_ D_RQ_MPC : 0|64@1+ (1,0) [0|9.22337203685e+18] "" Vector__XXX

CM_ SG_ 1698 D_RQ_MPC "D_RQ_MPC [source string/raw data]";

BA_ "GenMsgCycleTime" BO_ 1698 1;

BO_ 1702 MESS_SPC2: 8 ESP_ABR
 SG_ MESS_SPC2 : 0|64@1+ (1,0) [0|9.22337203685e+18] "" Vector__XXX

CM_ SG_ 1702 MESS_SPC2 "MESS_SPC2 [source string/raw data]";

BA_ "GenMsgCycleTime" BO_ 1702 1;

BO_ 1714 D_RQ_EPS: 8 ESP_ABR
 SG_ D_RQ_EPS : 0|64@1+ (1,0) [0|9.22337203685e+18] "" Vector__XXX

CM_ SG_ 1714 D_RQ_EPS "D_RQ_EPS [source string/raw data]";

BA_ "GenMsgCycleTime" BO_ 1714 1;

BO_ 1716 APPL_SG_EPS: 8 ESP_ABR
 SG_ APPL_SG_EPS : 0|64@1+ (1,0) [0|9.22337203685e+18] "" Vector__XXX

CM_ SG_ 1716 APPL_SG_EPS "APPL_SG_EPS [source string/raw data]";

BA_ "GenMsgCycleTime" BO_ 1716 1;

BO_ 1722 D_RQ_RBTM_FL: 8 ESP_ABR
 SG_ D_RQ_RBTM_FL : 0|64@1+ (1,0) [0|9.22337203685e+18] "" Vector__XXX

CM_ SG_ 1722 D_RQ_RBTM_FL "D_RQ_RBTM_FL [source string/raw data]";

BA_ "GenMsgCycleTime" BO_ 1722 1;

BO_ 1724 APPL_SG_RBTM_FL: 8 ESP_ABR
 SG_ APPL_SG_RBTM_FL : 0|64@1+ (1,0) [0|9.22337203685e+18] "" Vector__XXX

CM_ SG_ 1724 APPL_SG_RBTM_FL "APPL_SG_RBTM_FL [source string/raw data]";

BA_ "GenMsgCycleTime" BO_ 1724 1;

BO_ 1730 D_RQ_RBTM_FR: 8 ESP_ABR
 SG_ D_RQ_RBTM_FR : 0|64@1+ (1,0) [0|9.22337203685e+18] "" Vector__XXX

CM_ SG_ 1730 D_RQ_RBTM_FR "D_RQ_RBTM_FR [source string/raw data]";

BA_ "GenMsgCycleTime" BO_ 1730 1;

BO_ 1732 APPL_SG_RBTM_FR: 8 ESP_ABR
 SG_ APPL_SG_RBTM_FR : 0|64@1+ (1,0) [0|9.22337203685e+18] "" Vector__XXX

CM_ SG_ 1732 APPL_SG_RBTM_FR "APPL_SG_RBTM_FR [source string/raw data]";

BA_ "GenMsgCycleTime" BO_ 1732 1;

BO_ 1734 MESS_RBTM_FL1: 8 ESP_ABR
 SG_ MESS_RBTM_FL1 : 0|64@1+ (1,0) [0|9.22337203685e+18] "" Vector__XXX

CM_ SG_ 1734 MESS_RBTM_FL1 "MESS_RBTM_FL1 [source string/raw data]";

BA_ "GenMsgCycleTime" BO_ 1734 1;

BO_ 1738 D_RQ_EAC: 8 ESP_ABR
 SG_ D_RQ_EAC : 0|64@1+ (1,0) [0|9.22337203685e+18] "" Vector__XXX

CM_ SG_ 1738 D_RQ_EAC "D_RQ_EAC [source string/raw data]";

BA_ "GenMsgCycleTime" BO_ 1738 1;

BO_ 1740 APPL_SG_EAC: 8 ESP_ABR
 SG_ APPL_SG_EAC : 0|64@1+ (1,0) [0|9.22337203685e+18] "" Vector__XXX

CM_ SG_ 1740 APPL_SG_EAC "APPL_SG_EAC [source string/raw data]";

BA_ "GenMsgCycleTime" BO_ 1740 1;

BO_ 1742 MESS_RBTM_FR1: 8 ESP_ABR
 SG_ MESS_RBTM_FR1 : 0|64@1+ (1,0) [0|9.22337203685e+18] "" Vector__XXX

CM_ SG_ 1742 MESS_RBTM_FR1 "MESS_RBTM_FR1 [source string/raw data]";

BA_ "GenMsgCycleTime" BO_ 1742 1;

BO_ 1744 APPL_SG_RDU_SLV: 8 ESP_ABR
 SG_ APPL_SG_RDU_SLV : 0|64@1+ (1,0) [0|9.22337203685e+18] "" Vector__XXX

CM_ SG_ 1744 APPL_SG_RDU_SLV "APPL_SG_RDU_SLV [source string/raw data]";

BA_ "GenMsgCycleTime" BO_ 1744 1;

BO_ 1746 D_RQ_DCDC1: 8 ESP_ABR
 SG_ D_RQ_DCDC1 : 0|64@1+ (1,0) [0|9.22337203685e+18] "" Vector__XXX

CM_ SG_ 1746 D_RQ_DCDC1 "D_RQ_DCDC1 [source string/raw data]";

BA_ "GenMsgCycleTime" BO_ 1746 1;

BO_ 1748 APPL_SG_DCDC1: 8 ESP_ABR
 SG_ APPL_SG_DCDC1 : 0|64@1+ (1,0) [0|9.22337203685e+18] "" Vector__XXX

CM_ SG_ 1748 APPL_SG_DCDC1 "APPL_SG_DCDC1 [source string/raw data]";

BA_ "GenMsgCycleTime" BO_ 1748 1;

BO_ 1752 SG_APPL_RDU_SLV: 8 ESP_ABR
 SG_ SG_APPL_RDU_SLV : 0|64@1+ (1,0) [0|9.22337203685e+18] "" Vector__XXX

CM_ SG_ 1752 SG_APPL_RDU_SLV "SG_APPL_RDU_SLV [source string/raw data]";

BA_ "GenMsgCycleTime" BO_ 1752 1;

BO_ 1756 APPL_SG_EM1: 8 ESP_ABR
 SG_ APPL_SG_EM1 : 0|64@1+ (1,0) [0|9.22337203685e+18] "" Vector__XXX

CM_ SG_ 1756 APPL_SG_EM1 "APPL_SG_EM1 [source string/raw data]";

BA_ "GenMsgCycleTime" BO_ 1756 1;

BO_ 1760 APPL_SG_ECM_B2: 8 ESP_ABR
 SG_ APPL_SG_ECM_B2 : 0|64@1+ (1,0) [0|9.22337203685e+18] "" Vector__XXX

CM_ SG_ 1760 APPL_SG_ECM_B2 "APPL_SG_ECM_B2 [source string/raw data]";

BA_ "GenMsgCycleTime" BO_ 1760 1;

BO_ 1764 APPL_SG_TCM: 8 ESP_ABR
 SG_ APPL_SG_TCM : 0|64@1+ (1,0) [0|9.22337203685e+18] "" Vector__XXX

CM_ SG_ 1764 APPL_SG_TCM "APPL_SG_TCM [source string/raw data]";

BA_ "GenMsgCycleTime" BO_ 1764 1;

BO_ 1768 SG_APPL_ECM_B2: 8 ESP_ABR
 SG_ SG_APPL_ECM_B2 : 0|64@1+ (1,0) [0|9.22337203685e+18] "" Vector__XXX

CM_ SG_ 1768 SG_APPL_ECM_B2 "SG_APPL_ECM_B2 [source string/raw data]";

BA_ "GenMsgCycleTime" BO_ 1768 1;

BO_ 1770 D_RQ_ISM: 8 ESP_ABR
 SG_ D_RQ_ISM : 0|64@1+ (1,0) [0|9.22337203685e+18] "" Vector__XXX

CM_ SG_ 1770 D_RQ_ISM "D_RQ_ISM [source string/raw data]";

BA_ "GenMsgCycleTime" BO_ 1770 1;

BO_ 1772 APPL_SG_ISM: 8 ESP_ABR
 SG_ APPL_SG_ISM : 0|64@1+ (1,0) [0|9.22337203685e+18] "" Vector__XXX

CM_ SG_ 1772 APPL_SG_ISM "APPL_SG_ISM [source string/raw data]";

BA_ "GenMsgCycleTime" BO_ 1772 1;

BO_ 1778 D_RQ_SSP: 8 ESP_ABR
 SG_ D_RQ_SSP : 0|64@1+ (1,0) [0|9.22337203685e+18] "" Vector__XXX

CM_ SG_ 1778 D_RQ_SSP "D_RQ_SSP [source string/raw data]";

BA_ "GenMsgCycleTime" BO_ 1778 1;

BO_ 1780 APPL_SG_SSP: 8 ESP_ABR
 SG_ APPL_SG_SSP : 0|64@1+ (1,0) [0|9.22337203685e+18] "" Vector__XXX

CM_ SG_ 1780 APPL_SG_SSP "APPL_SG_SSP [source string/raw data]";

BA_ "GenMsgCycleTime" BO_ 1780 1;

BO_ 1786 D_RQ_FSCM: 8 ESP_ABR
 SG_ D_RQ_FSCM : 0|64@1+ (1,0) [0|9.22337203685e+18] "" Vector__XXX

CM_ SG_ 1786 D_RQ_FSCM "D_RQ_FSCM [source string/raw data]";

BA_ "GenMsgCycleTime" BO_ 1786 1;

BO_ 1788 APPL_SG_FSCM: 8 ESP_ABR
 SG_ APPL_SG_FSCM : 0|64@1+ (1,0) [0|9.22337203685e+18] "" Vector__XXX

CM_ SG_ 1788 APPL_SG_FSCM "APPL_SG_FSCM [source string/raw data]";

BA_ "GenMsgCycleTime" BO_ 1788 1;

BO_ 1794 D_RQ_DTR: 8 ESP_ABR
 SG_ D_RQ_DTR : 0|64@1+ (1,0) [0|9.22337203685e+18] "" Vector__XXX

CM_ SG_ 1794 D_RQ_DTR "D_RQ_DTR [source string/raw data]";

BA_ "GenMsgCycleTime" BO_ 1794 1;

BO_ 1796 APPL_SG_DTR: 8 ESP_ABR
 SG_ APPL_SG_DTR : 0|64@1+ (1,0) [0|9.22337203685e+18] "" Vector__XXX

CM_ SG_ 1796 APPL_SG_DTR "APPL_SG_DTR [source string/raw data]";

BA_ "GenMsgCycleTime" BO_ 1796 1;

BO_ 1802 D_RQ_NV: 8 ESP_ABR
 SG_ D_RQ_NV : 0|64@1+ (1,0) [0|9.22337203685e+18] "" Vector__XXX

CM_ SG_ 1802 D_RQ_NV "D_RQ_NV [source string/raw data]";

BA_ "GenMsgCycleTime" BO_ 1802 1;

BO_ 1810 D_RQ_SBC_SC: 8 ESP_ABR
 SG_ D_RQ_SBC_SC : 0|64@1+ (1,0) [0|9.22337203685e+18] "" Vector__XXX

CM_ SG_ 1810 D_RQ_SBC_SC "D_RQ_SBC_SC [source string/raw data]";

BA_ "GenMsgCycleTime" BO_ 1810 1;

BO_ 1812 APPL_SG_SBC_SC: 8 ESP_ABR
 SG_ APPL_SG_SBC_SC : 0|64@1+ (1,0) [0|9.22337203685e+18] "" Vector__XXX

CM_ SG_ 1812 APPL_SG_SBC_SC "APPL_SG_SBC_SC [source string/raw data]";

BA_ "GenMsgCycleTime" BO_ 1812 1;

BO_ 1818 D_RQ_SSM: 8 ESP_ABR
 SG_ D_RQ_SSM : 0|64@1+ (1,0) [0|9.22337203685e+18] "" Vector__XXX

CM_ SG_ 1818 D_RQ_SSM "D_RQ_SSM [source string/raw data]";

BA_ "GenMsgCycleTime" BO_ 1818 1;

BO_ 1820 APPL_SG_SSM: 8 ESP_ABR
 SG_ APPL_SG_SSM : 0|64@1+ (1,0) [0|9.22337203685e+18] "" Vector__XXX

CM_ SG_ 1820 APPL_SG_SSM "APPL_SG_SSM [source string/raw data]";

BA_ "GenMsgCycleTime" BO_ 1820 1;

BO_ 1830 MESS_RDU1: 8 ESP_ABR
 SG_ MESS_RDU1 : 0|64@1+ (1,0) [0|9.22337203685e+18] "" Vector__XXX

CM_ SG_ 1830 MESS_RDU1 "MESS_RDU1 [source string/raw data]";

BA_ "GenMsgCycleTime" BO_ 1830 1;

BO_ 1838 MESS_RDU2: 8 ESP_ABR
 SG_ MESS_RDU2 : 0|64@1+ (1,0) [0|9.22337203685e+18] "" Vector__XXX

CM_ SG_ 1838 MESS_RDU2 "MESS_RDU2 [source string/raw data]";

BA_ "GenMsgCycleTime" BO_ 1838 1;

BO_ 1842 D_RQ_EPKB: 8 ESP_ABR
 SG_ D_RQ_EPKB : 0|64@1+ (1,0) [0|9.22337203685e+18] "" Vector__XXX

CM_ SG_ 1842 D_RQ_EPKB "D_RQ_EPKB [source string/raw data]";

BA_ "GenMsgCycleTime" BO_ 1842 1;

BO_ 1846 MESS_RDU3: 8 ESP_ABR
 SG_ MESS_RDU3 : 0|64@1+ (1,0) [0|9.22337203685e+18] "" Vector__XXX

CM_ SG_ 1846 MESS_RDU3 "MESS_RDU3 [source string/raw data]";

BA_ "GenMsgCycleTime" BO_ 1846 1;

BO_ 1854 MESS_RDU4: 8 ESP_ABR
 SG_ MESS_RDU4 : 0|64@1+ (1,0) [0|9.22337203685e+18] "" Vector__XXX

CM_ SG_ 1854 MESS_RDU4 "MESS_RDU4 [source string/raw data]";

BA_ "GenMsgCycleTime" BO_ 1854 1;

BO_ 1855 D_RQ_ORC_LIN: 8 ESP_ABR
 SG_ D_RQ_ORC_LIN : 0|64@1+ (1,0) [0|9.22337203685e+18] "" Vector__XXX

CM_ SG_ 1855 D_RQ_ORC_LIN "D_RQ_ORC_LIN [source string/raw data]";

BA_ "GenMsgCycleTime" BO_ 1855 1;

BO_ 1863 D_RS_ORC_LIN: 8 ESP_ABR
 SG_ D_RS_ORC_LIN : 0|64@1+ (1,0) [0|9.22337203685e+18] "" Vector__XXX

CM_ SG_ 1863 D_RS_ORC_LIN "D_RS_ORC_LIN [source string/raw data]";

BA_ "GenMsgCycleTime" BO_ 1863 1;

BO_ 1864 SG_APPL_ECM2: 8 ESP_ABR
 SG_ SG_APPL_ECM2 : 0|64@1+ (1,0) [0|9.22337203685e+18] "" Vector__XXX

CM_ SG_ 1864 SG_APPL_ECM2 "SG_APPL_ECM2 [source string/raw data]";

BA_ "GenMsgCycleTime" BO_ 1864 1;

BO_ 1866 APPL_SG_ECM_B1: 8 ESP_ABR
 SG_ APPL_SG_ECM_B1 : 0|64@1+ (1,0) [0|9.22337203685e+18] "" Vector__XXX

CM_ SG_ 1866 APPL_SG_ECM_B1 "APPL_SG_ECM_B1 [source string/raw data]";

BA_ "GenMsgCycleTime" BO_ 1866 1;

BO_ 1868 APPL_SG_ECM: 8 ESP_ABR
 SG_ APPL_SG_ECM : 0|64@1+ (1,0) [0|9.22337203685e+18] "" Vector__XXX

CM_ SG_ 1868 APPL_SG_ECM "APPL_SG_ECM [source string/raw data]";

BA_ "GenMsgCycleTime" BO_ 1868 1;

BO_ 1890 D_RQ_CNG: 8 ESP_ABR
 SG_ D_RQ_CNG : 0|64@1+ (1,0) [0|9.22337203685e+18] "" Vector__XXX

CM_ SG_ 1890 D_RQ_CNG "D_RQ_CNG [source string/raw data]";

BA_ "GenMsgCycleTime" BO_ 1890 1;

BO_ 1914 D_RQ_TSLM: 8 ESP_ABR
 SG_ D_RQ_TSLM : 0|64@1+ (1,0) [0|9.22337203685e+18] "" Vector__XXX

CM_ SG_ 1914 D_RQ_TSLM "D_RQ_TSLM [source string/raw data]";

BA_ "GenMsgCycleTime" BO_ 1914 1;

BO_ 1924 APPL_SG_EM2: 8 ESP_ABR
 SG_ APPL_SG_EM2 : 0|64@1+ (1,0) [0|9.22337203685e+18] "" Vector__XXX

CM_ SG_ 1924 APPL_SG_EM2 "APPL_SG_EM2 [source string/raw data]";

BA_ "GenMsgCycleTime" BO_ 1924 1;

BO_ 1930 D_RQ_PTS_APX: 8 ESP_ABR
 SG_ D_RQ_PTS_APX : 0|64@1+ (1,0) [0|9.22337203685e+18] "" Vector__XXX

CM_ SG_ 1930 D_RQ_PTS_APX "D_RQ_PTS_APX [source string/raw data]";

BA_ "GenMsgCycleTime" BO_ 1930 1;

BO_ 1936 APPL_SG_SCCM2: 8 ESP_ABR
 SG_ APPL_SG_SCCM2 : 0|64@1+ (1,0) [0|9.22337203685e+18] "" Vector__XXX

CM_ SG_ 1936 APPL_SG_SCCM2 "APPL_SG_SCCM2 [source string/raw data]";

BA_ "GenMsgCycleTime" BO_ 1936 1;

BO_ 1938 D_RQ_DSI: 8 ESP_ABR
 SG_ D_RQ_DSI : 0|64@1+ (1,0) [0|9.22337203685e+18] "" Vector__XXX

CM_ SG_ 1938 D_RQ_DSI "D_RQ_DSI [source string/raw data]";

BA_ "GenMsgCycleTime" BO_ 1938 1;

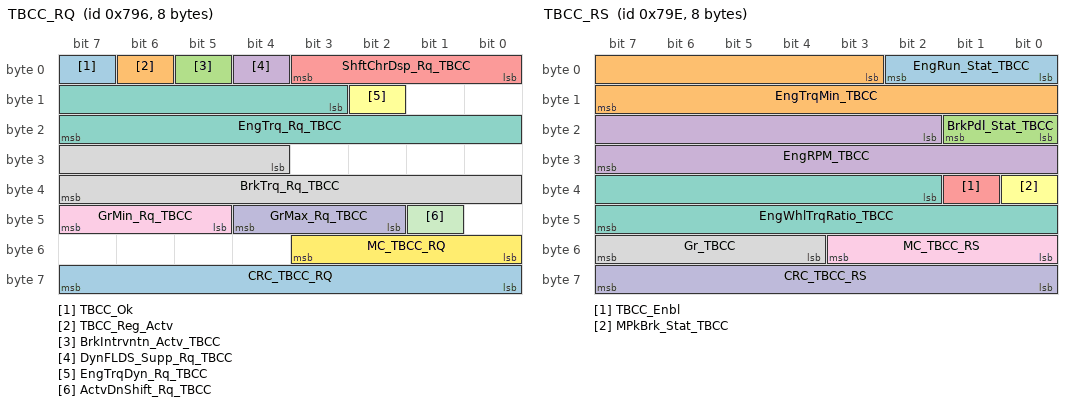
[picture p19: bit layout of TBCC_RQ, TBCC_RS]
BO_ 1942 TBCC_RQ: 8 ESP_ABR
 SG_ TBCC_Ok : 7|1@1+ (1,0) [0|1] "" Vector__XXX

CM_ SG_ 1942 TBCC_Ok "TBCC_Ok [source boolean]";
 SG_ TBCC_Reg_Actv : 6|1@1+ (1,0) [0|1] "" Vector__XXX

CM_ SG_ 1942 TBCC_Reg_Actv "TBCC_Reg_Actv [source boolean]";
 SG_ BrkIntrvntn_Actv_TBCC : 5|1@1+ (1,0) [0|1] "" Vector__XXX

CM_ SG_ 1942 BrkIntrvntn_Actv_TBCC "BrkIntrvntn_Actv_TBCC [source boolean]";
 SG_ DynFLDS_Supp_Rq_TBCC : 4|1@1+ (1,0) [0|1] "" Vector__XXX

CM_ SG_ 1942 DynFLDS_Supp_Rq_TBCC "DynFLDS_Supp_Rq_TBCC [source boolean]";
 SG_ ShftChrDsp_Rq_TBCC : 0|4@1+ (1,0) [0|15] "" Vector__XXX

CM_ SG_ 1942 ShftChrDsp_Rq_TBCC "ShftChrDsp_Rq_TBCC [source enum/value-table reference]";
 SG_ EngTrqDyn_Rq_TBCC : 10|1@1+ (1,0) [0|1] "" Vector__XXX

CM_ SG_ 1942 EngTrqDyn_Rq_TBCC "EngTrqDyn_Rq_TBCC [source boolean]";
 SG_ EngTrq_Rq_TBCC : 11|13@1+ (0.25,-500) [-500|1547.75] "Nm" Vector__XXX

CM_ SG_ 1942 EngTrq_Rq_TBCC "EngTrq_Rq_TBCC";
 SG_ BrkTrq_Rq_TBCC : 28|12@1+ (3,0) [0|12285] "Nm" Vector__XXX

CM_ SG_ 1942 BrkTrq_Rq_TBCC "BrkTrq_Rq_TBCC";
 SG_ GrMin_Rq_TBCC : 45|3@1+ (1,0) [0|7] "" Vector__XXX

CM_ SG_ 1942 GrMin_Rq_TBCC "GrMin_Rq_TBCC [source enum/value-table reference]";
 SG_ GrMax_Rq_TBCC : 42|3@1+ (1,0) [0|7] "" Vector__XXX

CM_ SG_ 1942 GrMax_Rq_TBCC "GrMax_Rq_TBCC [source enum/value-table reference]";
 SG_ ActvDnShift_Rq_TBCC : 41|1@1+ (1,0) [0|1] "" Vector__XXX

CM_ SG_ 1942 ActvDnShift_Rq_TBCC "ActvDnShift_Rq_TBCC [source boolean]";
 SG_ MC_TBCC_RQ : 48|4@1+ (1,0) [0|15] "" Vector__XXX

CM_ SG_ 1942 MC_TBCC_RQ "MC_TBCC_RQ";
 SG_ CRC_TBCC_RQ : 56|8@1+ (1,0) [0|255] "" Vector__XXX

CM_ SG_ 1942 CRC_TBCC_RQ "CRC_TBCC_RQ";

BA_ "GenMsgCycleTime" BO_ 1942 13;

BO_ 1944 SG_APPL_SCCM2: 8 ESP_ABR
 SG_ SG_APPL_SCCM2 : 0|64@1+ (1,0) [0|9.22337203685e+18] "" Vector__XXX

CM_ SG_ 1944 SG_APPL_SCCM2 "SG_APPL_SCCM2 [source string/raw data]";

BA_ "GenMsgCycleTime" BO_ 1944 1;

BO_ 1946 D_RQ_TCASE: 8 ESP_ABR
 SG_ D_RQ_TCASE : 0|64@1+ (1,0) [0|9.22337203685e+18] "" Vector__XXX

CM_ SG_ 1946 D_RQ_TCASE "D_RQ_TCASE [source string/raw data]";

BA_ "GenMsgCycleTime" BO_ 1946 1;

BO_ 1948 APPL_SG_TCASE: 8 ESP_ABR
 SG_ APPL_SG_TCASE : 0|64@1+ (1,0) [0|9.22337203685e+18] "" Vector__XXX

CM_ SG_ 1948 APPL_SG_TCASE "APPL_SG_TCASE [source string/raw data]";

BA_ "GenMsgCycleTime" BO_ 1948 1;

BO_ 1950 TBCC_RS: 8 ESP_ABR
 SG_ EngRun_Stat_TBCC : 0|3@1+ (1,0) [0|7] "" Vector__XXX

CM_ SG_ 1950 EngRun_Stat_TBCC "EngRun_Stat_TBCC [source enum/value-table reference]";
 SG_ EngTrqMin_TBCC : 3|13@1+ (0.25,-500) [-500|1547.75] "Nm" Vector__XXX

CM_ SG_ 1950 EngTrqMin_TBCC "EngTrqMin_TBCC";
 SG_ BrkPdl_Stat_TBCC : 16|2@1+ (1,0) [0|3] "" Vector__XXX

CM_ SG_ 1950 BrkPdl_Stat_TBCC "BrkPdl_Stat_TBCC [source enum/value-table reference]";
 SG_ EngRPM_TBCC : 18|14@1+ (1,0) [0|16383] "rpm" Vector__XXX

CM_ SG_ 1950 EngRPM_TBCC "EngRPM_TBCC";
 SG_ TBCC_Enbl : 33|1@1+ (1,0) [0|1] "" Vector__XXX

CM_ SG_ 1950 TBCC_Enbl "TBCC_Enbl [source boolean]";
 SG_ MPkBrk_Stat_TBCC : 32|1@1+ (1,0) [0|1] "" Vector__XXX

CM_ SG_ 1950 MPkBrk_Stat_TBCC "MPkBrk_Stat_TBCC [source boolean]";
 SG_ EngWhlTrqRatio_TBCC : 34|14@1+ (0.00999999977648,0) [0|163.829996338] "" Vector__XXX

CM_ SG_ 1950 EngWhlTrqRatio_TBCC "EngWhlTrqRatio_TBCC";
 SG_ Gr_TBCC : 52|4@1+ (1,0) [0|15] "" Vector__XXX

CM_ SG_ 1950 Gr_TBCC "Gr_TBCC [source enum/value-table reference]";
 SG_ MC_TBCC_RS : 48|4@1+ (1,0) [0|15] "" Vector__XXX

CM_ SG_ 1950 MC_TBCC_RS "MC_TBCC_RS";
 SG_ CRC_TBCC_RS : 56|8@1+ (1,0) [0|255] "" Vector__XXX

CM_ SG_ 1950 CRC_TBCC_RS "CRC_TBCC_RS";

BA_ "GenMsgCycleTime" BO_ 1950 10;

BO_ 1953 D_RS_SRD_F1: 8 ESP_ABR
 SG_ D_RS_SRD_F1 : 0|64@1+ (1,0) [0|9.22337203685e+18] "" Vector__XXX

CM_ SG_ 1953 D_RS_SRD_F1 "D_RS_SRD_F1 [source string/raw data]";

BA_ "GenMsgCycleTime" BO_ 1953 1;

BO_ 1956 APPL_SG_BMS: 8 ESP_ABR
 SG_ APPL_SG_BMS : 0|64@1+ (1,0) [0|9.22337203685e+18] "" Vector__XXX

CM_ SG_ 1956 APPL_SG_BMS "APPL_SG_BMS [source string/raw data]";

BA_ "GenMsgCycleTime" BO_ 1956 1;

BO_ 1961 D_RS_SRD_F2: 8 ESP_ABR
 SG_ D_RS_SRD_F2 : 0|64@1+ (1,0) [0|9.22337203685e+18] "" Vector__XXX

CM_ SG_ 1961 D_RS_SRD_F2 "D_RS_SRD_F2 [source string/raw data]";

BA_ "GenMsgCycleTime" BO_ 1961 1;

BO_ 1962 D_RQ_FSCM2: 8 ESP_ABR
 SG_ D_RQ_FSCM2 : 0|64@1+ (1,0) [0|9.22337203685e+18] "" Vector__XXX

CM_ SG_ 1962 D_RQ_FSCM2 "D_RQ_FSCM2 [source string/raw data]";

BA_ "GenMsgCycleTime" BO_ 1962 1;

BO_ 1969 D_RS_SRD_F3: 8 ESP_ABR
 SG_ D_RS_SRD_F3 : 0|64@1+ (1,0) [0|9.22337203685e+18] "" Vector__XXX

CM_ SG_ 1969 D_RS_SRD_F3 "D_RS_SRD_F3 [source string/raw data]";

BA_ "GenMsgCycleTime" BO_ 1969 1;

BO_ 1977 D_RS_SRD_F4: 8 ESP_ABR
 SG_ D_RS_SRD_F4 : 0|64@1+ (1,0) [0|9.22337203685e+18] "" Vector__XXX

CM_ SG_ 1977 D_RS_SRD_F4 "D_RS_SRD_F4 [source string/raw data]";

BA_ "GenMsgCycleTime" BO_ 1977 1;

BO_ 1985 D_RS_SRD_R1: 8 ESP_ABR
 SG_ D_RS_SRD_R1 : 0|64@1+ (1,0) [0|9.22337203685e+18] "" Vector__XXX

CM_ SG_ 1985 D_RS_SRD_R1 "D_RS_SRD_R1 [source string/raw data]";

BA_ "GenMsgCycleTime" BO_ 1985 1;

BO_ 1993 D_RS_SRD_R2: 8 ESP_ABR
 SG_ D_RS_SRD_R2 : 0|64@1+ (1,0) [0|9.22337203685e+18] "" Vector__XXX

CM_ SG_ 1993 D_RS_SRD_R2 "D_RS_SRD_R2 [source string/raw data]";

BA_ "GenMsgCycleTime" BO_ 1993 1;

BO_ 1998 MESS_ECM3: 8 ESP_ABR
 SG_ MESS_ECM3 : 0|64@1+ (1,0) [0|9.22337203685e+18] "" Vector__XXX

CM_ SG_ 1998 MESS_ECM3 "MESS_ECM3 [source string/raw data]";

BA_ "GenMsgCycleTime" BO_ 1998 1;

BO_ 2001 D_RS_SRD_R3: 8 ESP_ABR
 SG_ D_RS_SRD_R3 : 0|64@1+ (1,0) [0|9.22337203685e+18] "" Vector__XXX

CM_ SG_ 2001 D_RS_SRD_R3 "D_RS_SRD_R3 [source string/raw data]";

BA_ "GenMsgCycleTime" BO_ 2001 1;

BO_ 2006 MESS_ECM4: 8 ESP_ABR
 SG_ MESS_ECM4 : 0|64@1+ (1,0) [0|9.22337203685e+18] "" Vector__XXX

CM_ SG_ 2006 MESS_ECM4 "MESS_ECM4 [source string/raw data]";

BA_ "GenMsgCycleTime" BO_ 2006 1;

BO_ 2015 DG_RQ_OBD: 8 ESP_ABR
 SG_ DG_RQ_OBD : 0|64@1+ (1,0) [0|9.22337203685e+18] "" Vector__XXX

CM_ SG_ 2015 DG_RQ_OBD "DG_RQ_OBD [source string/raw data]";

BA_ "GenMsgCycleTime" BO_ 2015 1;

BO_ 2016 D_RQ_ECM: 8 ESP_ABR
 SG_ D_RQ_ECM : 0|64@1+ (1,0) [0|9.22337203685e+18] "" Vector__XXX

CM_ SG_ 2016 D_RQ_ECM "D_RQ_ECM [source string/raw data]";

BA_ "GenMsgCycleTime" BO_ 2016 1;

BO_ 2017 D_RQ_TCM: 8 ESP_ABR
 SG_ D_RQ_TCM : 0|64@1+ (1,0) [0|9.22337203685e+18] "" Vector__XXX

CM_ SG_ 2017 D_RQ_TCM "D_RQ_TCM [source string/raw data]";

BA_ "GenMsgCycleTime" BO_ 2017 1;

BO_ 2018 D_RQ_EM1: 8 ESP_ABR
 SG_ D_RQ_EM1 : 0|64@1+ (1,0) [0|9.22337203685e+18] "" Vector__XXX

CM_ SG_ 2018 D_RQ_EM1 "D_RQ_EM1 [source string/raw data]";

BA_ "GenMsgCycleTime" BO_ 2018 1;

BO_ 2019 D_RQ_FSCM_OBD: 8 ESP_ABR
 SG_ D_RQ_FSCM_OBD : 0|64@1+ (1,0) [0|9.22337203685e+18] "" Vector__XXX

CM_ SG_ 2019 D_RQ_FSCM_OBD "D_RQ_FSCM_OBD [source string/raw data]";

BA_ "GenMsgCycleTime" BO_ 2019 1;

BO_ 2020 D_RQ_SCRCM: 8 ESP_ABR
 SG_ D_RQ_SCRCM : 0|64@1+ (1,0) [0|9.22337203685e+18] "" Vector__XXX

CM_ SG_ 2020 D_RQ_SCRCM "D_RQ_SCRCM [source string/raw data]";

BA_ "GenMsgCycleTime" BO_ 2020 1;

BO_ 2022 D_RQ_EM2: 8 ESP_ABR
 SG_ D_RQ_EM2 : 0|64@1+ (1,0) [0|9.22337203685e+18] "" Vector__XXX

CM_ SG_ 2022 D_RQ_EM2 "D_RQ_EM2 [source string/raw data]";

BA_ "GenMsgCycleTime" BO_ 2022 1;

BO_ 2023 D_RQ_BMS: 8 ESP_ABR
 SG_ D_RQ_BMS : 0|64@1+ (1,0) [0|9.22337203685e+18] "" Vector__XXX

CM_ SG_ 2023 D_RQ_BMS "D_RQ_BMS [source string/raw data]";

BA_ "GenMsgCycleTime" BO_ 2023 1;

BO_ 2024 D_RS_ECM: 8 ESP_ABR
 SG_ D_RS_ECM : 0|64@1+ (1,0) [0|9.22337203685e+18] "" Vector__XXX

CM_ SG_ 2024 D_RS_ECM "D_RS_ECM [source string/raw data]";

BA_ "GenMsgCycleTime" BO_ 2024 1;

BO_ 2025 D_RS_TCM: 8 ESP_ABR
 SG_ D_RS_TCM : 0|64@1+ (1,0) [0|9.22337203685e+18] "" Vector__XXX

CM_ SG_ 2025 D_RS_TCM "D_RS_TCM [source string/raw data]";

BA_ "GenMsgCycleTime" BO_ 2025 1;

BO_ 2026 D_RS_EM1: 8 ESP_ABR
 SG_ D_RS_EM1 : 0|64@1+ (1,0) [0|9.22337203685e+18] "" Vector__XXX

CM_ SG_ 2026 D_RS_EM1 "D_RS_EM1 [source string/raw data]";

BA_ "GenMsgCycleTime" BO_ 2026 1;

BO_ 2027 D_RS_FSCM_OBD: 8 ESP_ABR
 SG_ D_RS_FSCM_OBD : 0|64@1+ (1,0) [0|9.22337203685e+18] "" Vector__XXX

CM_ SG_ 2027 D_RS_FSCM_OBD "D_RS_FSCM_OBD [source string/raw data]";

BA_ "GenMsgCycleTime" BO_ 2027 1;

BO_ 2028 D_RS_SCRCM: 8 ESP_ABR
 SG_ D_RS_SCRCM : 0|64@1+ (1,0) [0|9.22337203685e+18] "" Vector__XXX

CM_ SG_ 2028 D_RS_SCRCM "D_RS_SCRCM [source string/raw data]";

BA_ "GenMsgCycleTime" BO_ 2028 1;

BO_ 2030 D_RS_EM2: 8 ESP_ABR
 SG_ D_RS_EM2 : 0|64@1+ (1,0) [0|9.22337203685e+18] "" Vector__XXX

CM_ SG_ 2030 D_RS_EM2 "D_RS_EM2 [source string/raw data]";

BA_ "GenMsgCycleTime" BO_ 2030 1;

BO_ 2031 D_RS_BMS: 8 ESP_ABR
 SG_ D_RS_BMS : 0|64@1+ (1,0) [0|9.22337203685e+18] "" Vector__XXX

CM_ SG_ 2031 D_RS_BMS "D_RS_BMS [source string/raw data]";

BA_ "GenMsgCycleTime" BO_ 2031 1;
